VERSION "dbc-export 1 2025.20.8"

NS_ :

BS_:

BU_: ADSP APB APP APS APSB BB BMS CC CMP CMPD CP DAS DI DIF DIR DPB EPAS3P EPAS3S EPASTP EPASTS EPBL EPBR ESP EVSE FC GTW HCML HCMR HVP IBST ICR IDB LS OCS1P PARK PCS PM PMF PMR PNCD PTC RADC RCM RCM2 RCM3 RCU SCCM SCM SCS SDCR TAS TCU TPMS TRCM UI UIS UMC USM VC VCFRONT VCLEFT VCRIGHT VCSEC VEH

BO_ 1343 BMS_alertLog: 8 BMS
 SG_ BMS_alertID M : 0|8@1+ (1,0) [0|255] "" Vector__XXX
 SG_ BMS_alertSet : 15|1@1+ (1,0) [0|1] "" Vector__XXX
 SG_ BMS_a001_gatewayPackEnergy m1 : 16|2@1+ (1,0) [0|3] "" Vector__XXX
 SG_ BMS_a001_expectedPackEnergy m1 : 18|2@1+ (1,0) [0|3] "" Vector__XXX
 SG_ BMS_a002_gatewayPackPerformanceD m2 : 16|3@1+ (1,0) [0|7] "" Vector__XXX
 SG_ BMS_a002_expectedPackPerformance m2 : 19|3@1+ (1,0) [0|7] "" Vector__XXX
 SG_ BMS_a002_bmsPackMass m2 : 24|8@1+ (1,300) [300|555] "" Vector__XXX
 SG_ BMS_a003_calBlockData_0 m3 : 16|32@1+ (1,0) [0|4294967295] "" Vector__XXX
 SG_ BMS_a007_minPackTemperature m7 : 16|8@1+ (0.5,-40) [-40|87.5] "" Vector__XXX
 SG_ BMS_a007_packCurrent m7 : 24|14@1+ (0.1,0) [0|1638.3] "" Vector__XXX
 SG_ BMS_a007_idealCurrentTarget m7 : 40|14@1+ (0.1,0) [0|1638.3] "" Vector__XXX
 SG_ BMS_a017_packCurrent m17 : 16|8@1+ (8,-1500) [-1500|540] "" Vector__XXX
 SG_ BMS_a017_ovBrickVID m17 : 24|7@1+ (1,1) [1|128] "" Vector__XXX
 SG_ BMS_a017_ovBrickV m17 : 32|16@1+ (7.62939453125e-05,0) [0|4.99992370605] "" Vector__XXX
 SG_ BMS_a018_packCurrent m18 : 16|8@1+ (8,-1496) [-1496|544] "" Vector__XXX
 SG_ BMS_a018_uvBrickVID m18 : 24|7@1+ (1,1) [1|128] "" Vector__XXX
 SG_ BMS_a018_uvBrickV m18 : 32|16@1+ (7.62939453125e-05,0) [0|4.99992370605] "" Vector__XXX
 SG_ BMS_a019_coolantInletT m19 : 16|8@1+ (0.4,-20) [-20|82] "" Vector__XXX
 SG_ BMS_a019_activeCoolingTarget m19 : 24|8@1+ (0.4,-20) [-20|82] "" Vector__XXX
 SG_ BMS_a019_maxBrickT m19 : 32|8@1+ (0.4,-20) [-20|82] "" Vector__XXX
 SG_ BMS_a019_maxBrickTID m19 : 40|5@1+ (1,1) [1|32] "" Vector__XXX
 SG_ BMS_a021_chargeViolation m21 : 16|1@1+ (1,0) [0|1] "" Vector__XXX
 SG_ BMS_a021_currentLimit m21 : 24|8@1+ (8,-1496) [-1496|544] "" Vector__XXX
 SG_ BMS_a021_packCurrent m21 : 32|8@1+ (8,-1496) [-1496|544] "" Vector__XXX
 SG_ BMS_a022_chargeAccumulatorViolat m22 : 16|1@1+ (1,0) [0|1] "" Vector__XXX
 SG_ BMS_a022_chargeAccumulatorValue m22 : 17|23@1+ (10,0) [0|83886070] "" Vector__XXX
 SG_ BMS_a022_chargeAccumulatorLimit m22 : 40|23@1+ (10,0) [0|83886070] "" Vector__XXX
 SG_ BMS_a023_ovStackDeviceID m23 : 16|5@1+ (1,1) [1|32] "" Vector__XXX
 SG_ BMS_a023_ovStackV m23 : 24|16@1+ (0.00128,0) [0|83.8848] "" Vector__XXX
 SG_ BMS_a024_brickID m24 : 16|8@1+ (1,1) [1|256] "" Vector__XXX
 SG_ BMS_a024_deltaV m24 : 24|16@1- (0.0001,0) [-3.2768|3.2767] "" Vector__XXX
 SG_ BMS_a024_avgDvPrev m24 : 40|16@1- (0.0001,0) [-3.2768|3.2767] "" Vector__XXX
 SG_ BMS_a024_packCurrent m24 : 56|8@1+ (8,-1500) [-1500|540] "" Vector__XXX
 SG_ BMS_a027_swIsolationCount m27 : 16|8@1+ (1,0) [0|255] "" Vector__XXX
 SG_ BMS_a027_swIsoDegradationCount m27 : 24|8@1+ (1,0) [0|255] "" Vector__XXX
 SG_ BMS_a030_worstBrickID m30 : 16|8@1+ (1,1) [1|256] "" Vector__XXX
 SG_ BMS_a030_maxBrickImpedance m30 : 24|10@1+ (0.1,0) [0|102.3] "" Vector__XXX
 SG_ BMS_a030_maxNormalizedImpedanceD m30 : 34|7@1+ (0.04,0) [0|5.08] "" Vector__XXX
 SG_ BMS_a030_faultThreshold m30 : 41|7@1+ (0.04,0) [0|5.08] "" Vector__XXX
 SG_ BMS_a030_numBricks m30 : 48|8@1+ (1,0) [0|255] "" Vector__XXX
 SG_ BMS_a030_worstBrickSoc m30 : 56|8@1+ (0.5,0) [0|127.5] "" Vector__XXX
 SG_ BMS_a035_isoR m35 : 16|9@1+ (10,0) [0|5110] "" Vector__XXX
 SG_ BMS_a035_mode m35 : 25|3@1+ (1,0) [0|7] "" Vector__XXX
 SG_ BMS_a035_activeSideVNoR m35 : 28|9@1+ (1,0) [0|511] "" Vector__XXX
 SG_ BMS_a035_activeSideVWithR m35 : 37|9@1+ (1,0) [0|511] "" Vector__XXX
 SG_ BMS_a035_passiveSideVNoR m35 : 46|9@1+ (1,0) [0|511] "" Vector__XXX
 SG_ BMS_a035_passiveSideVWithR m35 : 55|9@1+ (1,0) [0|511] "" Vector__XXX
 SG_ BMS_a037_floodPort1State m37 : 16|3@1+ (1,0) [0|7] "" Vector__XXX
 SG_ BMS_a037_floodPort1Voltage m37 : 19|12@1+ (0.001,0) [0|4.095] "" Vector__XXX
 SG_ BMS_a037_floodPort2State m37 : 32|3@1+ (1,0) [0|7] "" Vector__XXX
 SG_ BMS_a037_floodPort2Voltage m37 : 35|12@1+ (0.001,0) [0|4.095] "" Vector__XXX
 SG_ BMS_a039_dcLinkVoltage m39 : 16|10@1+ (1,0) [0|1023] "" Vector__XXX
 SG_ BMS_a039_packVoltage m39 : 26|10@1+ (1,0) [0|1023] "" Vector__XXX
 SG_ BMS_a039_packContactorState m39 : 36|4@1+ (1,0) [0|15] "" Vector__XXX
 SG_ BMS_a039_packCurrent m39 : 40|8@1+ (8,-1496) [-1496|544] "" Vector__XXX
 SG_ BMS_a039_maxBrickV m39 : 48|8@1+ (0.01,2) [2|4.55] "" Vector__XXX
 SG_ BMS_a039_state m39 : 56|4@1+ (1,0) [0|15] "" Vector__XXX
 SG_ BMS_a041_resetType m41 : 16|4@1+ (1,0) [0|15] "" Vector__XXX
 SG_ BMS_a050_MIA_numBadReadings m50 : 16|8@1+ (1,0) [0|255] "" Vector__XXX
 SG_ BMS_a050_MIA_numSnaReadings m50 : 24|8@1+ (1,0) [0|255] "" Vector__XXX
 SG_ BMS_a051_hvp1V5Ref m51 : 16|12@1+ (0.001,0) [0|4.095] "" Vector__XXX
 SG_ BMS_a051_hvp3V0Ref m51 : 28|12@1+ (0.001,0) [0|4.095] "" Vector__XXX
 SG_ BMS_a051_bms3V0Ref m51 : 40|12@1+ (0.001,0) [0|4.095] "" Vector__XXX
 SG_ BMS_a056_standbySupplyOutV m56 : 16|12@1+ (0.01,0) [0|40.95] "" Vector__XXX
 SG_ BMS_a056_packVoltage m56 : 28|16@1+ (0.01,0) [0|655.35] "" Vector__XXX
 SG_ BMS_a056_minBrickVoltage m56 : 44|12@1+ (0.002,0) [0|8.19] "" Vector__XXX
 SG_ BMS_a056_standbyEnabled m56 : 56|1@1+ (1,0) [0|1] "" Vector__XXX
 SG_ BMS_a056_standbySwGood m56 : 57|1@1+ (1,0) [0|1] "" Vector__XXX
 SG_ BMS_a056_ssOutTooHigh m56 : 58|1@1+ (1,0) [0|1] "" Vector__XXX
 SG_ BMS_a056_ssOutTooLow m56 : 59|1@1+ (1,0) [0|1] "" Vector__XXX
 SG_ BMS_a056_ssStuckOn m56 : 60|1@1+ (1,0) [0|1] "" Vector__XXX
 SG_ BMS_a056_ssStuckOff m56 : 61|1@1+ (1,0) [0|1] "" Vector__XXX
 SG_ BMS_a058_bandoThmModelState m58 : 16|4@1+ (1,0) [0|15] "" Vector__XXX
 SG_ BMS_a058_thermistorTempsInvalid m58 : 20|1@1+ (1,0) [0|1] "" Vector__XXX
 SG_ BMS_a058_inletCoolantTempInvalid m58 : 21|1@1+ (1,0) [0|1] "" Vector__XXX
 SG_ BMS_a058_ambientTempInvalid m58 : 22|1@1+ (1,0) [0|1] "" Vector__XXX
 SG_ BMS_a058_flowRateInvalid m58 : 23|1@1+ (1,0) [0|1] "" Vector__XXX
 SG_ BMS_a058_brickDissipationInvalid m58 : 24|1@1+ (1,0) [0|1] "" Vector__XXX
 SG_ BMS_a058_sanityCheckFailed m58 : 25|1@1+ (1,0) [0|1] "" Vector__XXX
 SG_ BMS_a058_tempDelta1 m58 : 32|7@1- (0.2,0) [-12.8|12.6] "" Vector__XXX
 SG_ BMS_a058_tempDelta2 m58 : 40|7@1- (0.2,0) [-12.8|12.6] "" Vector__XXX
 SG_ BMS_a058_tempDelta3 m58 : 48|7@1- (0.2,0) [-12.8|12.6] "" Vector__XXX
 SG_ BMS_a058_tempDelta4 m58 : 56|7@1- (0.2,0) [-12.8|12.6] "" Vector__XXX
 SG_ BMS_a059_sumBrickVoltages m59 : 16|16@1+ (0.01,0) [0|655.35] "" Vector__XXX
 SG_ BMS_a059_packVoltage m59 : 32|16@1+ (0.01,0) [0|655.35] "" Vector__XXX
 SG_ BMS_a062_state m62 : 16|4@1+ (1,0) [0|15] "" Vector__XXX
 SG_ BMS_a062_minBrickVId m62 : 24|7@1+ (1,1) [1|128] "" Vector__XXX
 SG_ BMS_a062_minBrickVoltage m62 : 32|12@1+ (0.002,0) [0|8.19] "" Vector__XXX
 SG_ BMS_a062_maxBrickVId m62 : 44|7@1+ (1,1) [1|128] "" Vector__XXX
 SG_ BMS_a062_maxBrickVoltage m62 : 51|12@1+ (0.002,0) [0|8.19] "" Vector__XXX
 SG_ BMS_a063_cpFaultInV m63 : 16|12@1+ (0.001,0) [0|4.095] "" Vector__XXX
 SG_ BMS_a064_minBrickSOCID m64 : 16|7@1+ (1,1) [1|128] "" Vector__XXX
 SG_ BMS_a064_minBrickSOC m64 : 24|8@1+ (0.5,0) [0|127.5] "" Vector__XXX
 SG_ BMS_a064_maxBrickSOCID m64 : 32|7@1+ (1,1) [1|128] "" Vector__XXX
 SG_ BMS_a064_maxBrickSOC m64 : 40|8@1+ (0.5,0) [0|127.5] "" Vector__XXX
 SG_ BMS_a064_avgBrickSOC m64 : 48|8@1+ (0.5,0) [0|127.5] "" Vector__XXX
 SG_ BMS_a065_minBrickCacId m65 : 16|7@1+ (1,1) [1|128] "" Vector__XXX
 SG_ BMS_a065_minBrickCac m65 : 24|13@1+ (0.1,0) [0|819.1] "" Vector__XXX
 SG_ BMS_a065_avgBrickCac m65 : 40|13@1+ (0.1,0) [0|819.1] "" Vector__XXX
 SG_ BMS_a065_modCacImbalancePct m65 : 53|10@1+ (0.1,0) [0|102.3] "" Vector__XXX
 SG_ BMS_a066_minBrickSocId m66 : 16|7@1+ (1,1) [1|128] "" Vector__XXX
 SG_ BMS_a066_minBrickSocByOcvMax m66 : 24|8@1+ (0.5,0) [0|127.5] "" Vector__XXX
 SG_ BMS_a066_maxBrickSocId m66 : 32|7@1+ (1,1) [1|128] "" Vector__XXX
 SG_ BMS_a066_maxBrickSocByOcvMin m66 : 40|8@1+ (0.5,0) [0|127.5] "" Vector__XXX
 SG_ BMS_a066_maxBrickSoc m66 : 48|8@1+ (0.5,0) [0|127.5] "" Vector__XXX
 SG_ BMS_a066_avgBrickSoc m66 : 56|8@1+ (0.5,0) [0|127.5] "" Vector__XXX
 SG_ BMS_a067_minBrickCacId m67 : 16|7@1+ (1,1) [1|128] "" Vector__XXX
 SG_ BMS_a067_minBrickCac m67 : 24|13@1+ (0.1,0) [0|819.1] "" Vector__XXX
 SG_ BMS_a067_avgBrickCac m67 : 40|13@1+ (0.1,0) [0|819.1] "" Vector__XXX
 SG_ BMS_a067_modCacImbalancePct m67 : 53|10@1+ (0.1,0) [0|102.3] "" Vector__XXX
 SG_ BMS_a068_minBrickCacId m68 : 16|7@1+ (1,1) [1|128] "" Vector__XXX
 SG_ BMS_a068_minBrickCac m68 : 24|13@1+ (0.1,0) [0|819.1] "" Vector__XXX
 SG_ BMS_a068_avgBrickCac m68 : 40|13@1+ (0.1,0) [0|819.1] "" Vector__XXX
 SG_ BMS_a068_modCacImbalancePct m68 : 53|10@1+ (0.1,0) [0|102.3] "" Vector__XXX
 SG_ BMS_a069_dischargePowerPackVolta m69 : 16|8@1- (0.025,-3.15) [-6.35|0.025] "" Vector__XXX
 SG_ BMS_a069_dischargePowerBrickVolt m69 : 24|8@1- (0.005,-0.63) [-1.27|0.005] "" Vector__XXX
 SG_ BMS_a069_SOC m69 : 32|8@1+ (0.05,0) [0|12.75] "" Vector__XXX
 SG_ BMS_a069_minBrickT m69 : 40|8@1- (0.5,24) [-40|87.5] "" Vector__XXX
 SG_ BMS_a069_minBrickVLimit m69 : 48|8@1+ (0.01,2) [2|4.55] "" Vector__XXX
 SG_ BMS_a069_minBrickV m69 : 56|8@1+ (0.01,2) [2|4.55] "" Vector__XXX
 SG_ BMS_a070_state m70 : 16|4@1+ (1,0) [0|15] "" Vector__XXX
 SG_ BMS_a070_minBrickVId m70 : 24|7@1+ (1,1) [1|128] "" Vector__XXX
 SG_ BMS_a070_minBrickVoltage m70 : 32|12@1+ (0.002,0) [0|8.19] "" Vector__XXX
 SG_ BMS_a070_maxBrickVId m70 : 44|7@1+ (1,1) [1|128] "" Vector__XXX
 SG_ BMS_a070_maxBrickVoltage m70 : 51|12@1+ (0.002,0) [0|8.19] "" Vector__XXX
 SG_ BMS_a071_stateRequest m71 : 16|4@1+ (1,0) [0|15] "" Vector__XXX
 SG_ BMS_a071_state m71 : 20|4@1+ (1,0) [0|15] "" Vector__XXX
 SG_ BMS_a071_transitionAlertId m71 : 24|10@1+ (1,0) [0|1023] "" Vector__XXX
 SG_ BMS_a074_maxBrickVTarget m74 : 16|8@1+ (0.01,2) [2|4.55] "" Vector__XXX
 SG_ BMS_a074_maxBrickV m74 : 24|8@1+ (0.01,2) [2|4.55] "" Vector__XXX
 SG_ BMS_a075_chargeType m75 : 16|1@1+ (1,0) [0|1] "" Vector__XXX
 SG_ BMS_a076_netAh m76 : 16|21@1- (0.01,0) [-10485.76|10485.75] "" Vector__XXX
 SG_ BMS_a076_tetheringActive m76 : 37|1@1+ (1,0) [0|1] "" Vector__XXX
 SG_ BMS_a078_peakDchInChg m78 : 16|16@1- (0.1,0) [-3276.8|3276.7] "" Vector__XXX
 SG_ BMS_a079_maxBrickVTarget m79 : 16|8@1+ (0.01,2) [2|4.55] "" Vector__XXX
 SG_ BMS_a079_maxBrickV m79 : 24|8@1+ (0.01,2) [2|4.55] "" Vector__XXX
 SG_ BMS_a081_stateRequest m81 : 16|4@1+ (1,0) [0|15] "" Vector__XXX
 SG_ BMS_a081_firstBlockingAlertId m81 : 24|8@1+ (1,0) [0|255] "" Vector__XXX
 SG_ BMS_a081_secondBlockingAlertId m81 : 32|8@1+ (1,0) [0|255] "" Vector__XXX
 SG_ BMS_a081_thirdBlockingAlertId m81 : 40|8@1+ (1,0) [0|255] "" Vector__XXX
 SG_ BMS_a081_fourthBlockingAlertId m81 : 48|8@1+ (1,0) [0|255] "" Vector__XXX
 SG_ BMS_a081_totalAlertCount m81 : 56|8@1+ (1,0) [0|255] "" Vector__XXX
 SG_ BMS_a082_stateRequest m82 : 16|4@1+ (1,0) [0|15] "" Vector__XXX
 SG_ BMS_a082_firstAlertId m82 : 24|8@1+ (1,0) [0|255] "" Vector__XXX
 SG_ BMS_a082_secondAlertId m82 : 32|8@1+ (1,0) [0|255] "" Vector__XXX
 SG_ BMS_a082_thirdAlertId m82 : 40|8@1+ (1,0) [0|255] "" Vector__XXX
 SG_ BMS_a082_fourthAlertId m82 : 48|8@1+ (1,0) [0|255] "" Vector__XXX
 SG_ BMS_a082_totalAlertCount m82 : 56|8@1+ (1,0) [0|255] "" Vector__XXX
 SG_ BMS_a083_packContactorRequest m83 : 16|3@1+ (1,0) [0|7] "" Vector__XXX
 SG_ BMS_a085_packContactorSetStatePr m85 : 16|4@1+ (1,0) [0|15] "" Vector__XXX
 SG_ BMS_a085_packContactorSetState m85 : 20|4@1+ (1,0) [0|15] "" Vector__XXX
 SG_ BMS_a085_packContactorSetRe_0001 m85 : 24|3@1+ (1,0) [0|7] "" Vector__XXX
 SG_ BMS_a085_packContactorSetRequest m85 : 27|3@1+ (1,0) [0|7] "" Vector__XXX
 SG_ BMS_a086_fcContactorSetStatePrev m86 : 16|4@1+ (1,0) [0|15] "" Vector__XXX
 SG_ BMS_a086_fcContactorSetState m86 : 20|4@1+ (1,0) [0|15] "" Vector__XXX
 SG_ BMS_a086_fcContactorSetRequestPr m86 : 24|3@1+ (1,0) [0|7] "" Vector__XXX
 SG_ BMS_a086_fcContactorSetRequest m86 : 27|3@1+ (1,0) [0|7] "" Vector__XXX
 SG_ BMS_a087_blockingAlert m87 : 16|8@1+ (1,0) [0|255] "" Vector__XXX
 SG_ BMS_a090_GTWmessageTout m90 : 16|4@1+ (1,0) [0|15] "" Vector__XXX
 SG_ BMS_a097_missingFrame m97 : 16|1@1+ (1,0) [0|1] "" Vector__XXX
 SG_ BMS_a097_timeout m97 : 17|1@1+ (1,0) [0|1] "" Vector__XXX
 SG_ BMS_a098_breakLocationA m98 : 16|5@1+ (1,0) [0|31] "" Vector__XXX
 SG_ BMS_a098_bmbCommStatusTypeA m98 : 21|2@1+ (1,0) [0|3] "" Vector__XXX
 SG_ BMS_a098_breakLocationB m98 : 24|5@1+ (1,0) [0|31] "" Vector__XXX
 SG_ BMS_a098_bmbCommStatusTypeB m98 : 29|2@1+ (1,0) [0|3] "" Vector__XXX
 SG_ BMS_a098_alertFromHvp m98 : 31|1@1+ (1,0) [0|1] "" Vector__XXX
 SG_ BMS_a099_breakLocationA m99 : 16|5@1+ (1,0) [0|31] "" Vector__XXX
 SG_ BMS_a099_bmbCommStatusTypeA m99 : 21|2@1+ (1,0) [0|3] "" Vector__XXX
 SG_ BMS_a099_breakLocationB m99 : 24|5@1+ (1,0) [0|31] "" Vector__XXX
 SG_ BMS_a099_bmbCommStatusTypeB m99 : 29|2@1+ (1,0) [0|3] "" Vector__XXX
 SG_ BMS_a099_bmbChainBreakType m99 : 32|3@1+ (1,0) [0|7] "" Vector__XXX
 SG_ BMS_a099_alertFromHvp m99 : 35|1@1+ (1,0) [0|1] "" Vector__XXX
 SG_ BMS_a100_testTrigger m100 : 16|1@1+ (1,0) [0|1] "" Vector__XXX
 SG_ BMS_a100_setFromNvm m100 : 17|1@1+ (1,0) [0|1] "" Vector__XXX
 SG_ BMS_a100_voltageDeviation m100 : 18|1@1+ (1,0) [0|1] "" Vector__XXX
 SG_ BMS_a100_voltageLoss m100 : 19|1@1+ (1,0) [0|1] "" Vector__XXX
 SG_ BMS_a105_tSenseFailedModule1 m105 : 16|1@1+ (1,0) [0|1] "" Vector__XXX
 SG_ BMS_a105_avgBrickTModule1 m105 : 17|8@1+ (0.5,0) [0|127.5] "" Vector__XXX
 SG_ BMS_a105_tSenseFailedModule2 m105 : 25|1@1+ (1,0) [0|1] "" Vector__XXX
 SG_ BMS_a105_avgBrickTModule2 m105 : 26|8@1+ (0.5,0) [0|127.5] "" Vector__XXX
 SG_ BMS_a105_tSenseFailedModule3 m105 : 34|1@1+ (1,0) [0|1] "" Vector__XXX
 SG_ BMS_a105_avgBrickTModule3 m105 : 35|8@1+ (0.5,0) [0|127.5] "" Vector__XXX
 SG_ BMS_a105_tSenseFailedModule4 m105 : 43|1@1+ (1,0) [0|1] "" Vector__XXX
 SG_ BMS_a105_avgBrickTModule4 m105 : 44|8@1+ (0.5,0) [0|127.5] "" Vector__XXX
 SG_ BMS_a105_inletTemp m105 : 52|8@1+ (0.5,0) [0|127.5] "" Vector__XXX
 SG_ BMS_a106_minBrickT m106 : 16|8@1+ (0.5,0) [0|127.5] "" Vector__XXX
 SG_ BMS_a106_maxBrickT m106 : 24|8@1+ (0.5,0) [0|127.5] "" Vector__XXX
 SG_ BMS_a106_avgBrickT m106 : 32|8@1+ (0.5,0) [0|127.5] "" Vector__XXX
 SG_ BMS_a106_inletTemp m106 : 40|8@1+ (0.5,0) [0|127.5] "" Vector__XXX
 SG_ BMS_a107_MIA_numBadReadings m107 : 16|8@1+ (1,0) [0|255] "" Vector__XXX
 SG_ BMS_a107_MIA_numSnaReadings m107 : 24|8@1+ (1,0) [0|255] "" Vector__XXX
 SG_ BMS_a109_muteMask m109 : 16|16@1+ (1,0) [0|65535] "" Vector__XXX
 SG_ BMS_a109_packInBleed m109 : 32|1@1+ (1,0) [0|1] "" Vector__XXX
 SG_ BMS_a117_brickID m117 : 16|7@1+ (1,1) [1|128] "" Vector__XXX
 SG_ BMS_a117_brickSoc2 m117 : 23|10@1+ (0.1,0) [0|102.3] "" Vector__XXX
 SG_ BMS_a117_dSocAlertThreshold m117 : 33|5@1+ (0.125,-4) [-4|-0.125] "" Vector__XXX
 SG_ BMS_a117_dSocAlpha m117 : 48|12@1+ (0.0030517578125,-12.4969482422) [-12.4969482422|-1.25002230789e-11] "" Vector__XXX
 SG_ BMS_a122_thermistorID m122 : 16|5@1+ (1,1) [1|32] "" Vector__XXX
 SG_ BMS_a122_irrationalThermistorTem m122 : 24|8@1+ (0.5,-40) [-40|87.5] "" Vector__XXX
 SG_ BMS_a122_averageRawThermistorTem m122 : 32|8@1+ (0.5,-40) [-40|87.5] "" Vector__XXX
 SG_ BMS_a122_minRawThermistorTemp m122 : 40|8@1+ (0.5,-40) [-40|87.5] "" Vector__XXX
 SG_ BMS_a122_maxRawThermistorTemp m122 : 48|8@1+ (0.5,-40) [-40|87.5] "" Vector__XXX
 SG_ BMS_a122_numValidThermistors m122 : 56|5@1+ (1,0) [0|31] "" Vector__XXX
 SG_ BMS_a123_packPlus m123 : 32|8@1+ (4,0) [0|1020] "" Vector__XXX
 SG_ BMS_a123_isoR m123 : 40|10@1+ (10,0) [0|10230] "" Vector__XXX
 SG_ BMS_a123_packMinus m123 : 56|8@1- (4,0) [-512|508] "" Vector__XXX
 SG_ BMS_a129_brickID m129 : 16|8@1+ (1,1) [1|256] "" Vector__XXX
 SG_ BMS_a129_deltaV m129 : 24|16@1+ (0.0001,0) [0|6.5535] "" Vector__XXX
 SG_ BMS_a129_retryCount m129 : 40|4@1+ (1,0) [0|15] "" Vector__XXX
 SG_ BMS_a131_brickID m131 : 16|8@1+ (1,1) [1|256] "" Vector__XXX
 SG_ BMS_a131_deltaV m131 : 24|16@1+ (0.0001,0) [0|6.5535] "" Vector__XXX
 SG_ BMS_a131_retryCount m131 : 40|4@1+ (1,0) [0|15] "" Vector__XXX
 SG_ BMS_a132_multiVendorErrorMask m132 : 16|16@1+ (1,0) [0|65535] "" Vector__XXX
 SG_ BMS_a135_bmbDiagnosticsType m135 : 16|2@1+ (1,0) [0|3] "" Vector__XXX
 SG_ BMS_a135_bmbDeviceId m135 : 18|4@1+ (1,1) [1|16] "" Vector__XXX
 SG_ BMS_a135_readCVA m135 : 22|1@1+ (1,0) [0|1] "" Vector__XXX
 SG_ BMS_a135_readCVB m135 : 23|1@1+ (1,0) [0|1] "" Vector__XXX
 SG_ BMS_a135_readCVC m135 : 24|1@1+ (1,0) [0|1] "" Vector__XXX
 SG_ BMS_a135_readCVD m135 : 25|1@1+ (1,0) [0|1] "" Vector__XXX
 SG_ BMS_a135_readCVE m135 : 26|1@1+ (1,0) [0|1] "" Vector__XXX
 SG_ BMS_a135_readCVF m135 : 27|1@1+ (1,0) [0|1] "" Vector__XXX
 SG_ BMS_a135_readSNA m135 : 28|1@1+ (1,0) [0|1] "" Vector__XXX
 SG_ BMS_a135_readSNB m135 : 29|1@1+ (1,0) [0|1] "" Vector__XXX
 SG_ BMS_a135_readSNC m135 : 30|1@1+ (1,0) [0|1] "" Vector__XXX
 SG_ BMS_a135_readSND m135 : 31|1@1+ (1,0) [0|1] "" Vector__XXX
 SG_ BMS_a135_readSNE m135 : 32|1@1+ (1,0) [0|1] "" Vector__XXX
 SG_ BMS_a135_readSNF m135 : 33|1@1+ (1,0) [0|1] "" Vector__XXX
 SG_ BMS_a135_readAUXA m135 : 34|1@1+ (1,0) [0|1] "" Vector__XXX
 SG_ BMS_a135_readAUXB m135 : 35|1@1+ (1,0) [0|1] "" Vector__XXX
 SG_ BMS_a135_readSTAT m135 : 36|1@1+ (1,0) [0|1] "" Vector__XXX
 SG_ BMS_a136_maxBrickTID m136 : 16|5@1+ (1,1) [1|32] "" Vector__XXX
 SG_ BMS_a136_coolantInletT m136 : 24|8@1+ (0.4,-20) [-20|82] "" Vector__XXX
 SG_ BMS_a136_activeCoolingTarget m136 : 32|8@1+ (0.4,-20) [-20|82] "" Vector__XXX
 SG_ BMS_a136_maxBrickT m136 : 40|8@1+ (0.4,-20) [-20|82] "" Vector__XXX
 SG_ BMS_a139_packVoltage m139 : 16|16@1- (0.01,0) [-327.68|327.67] "" Vector__XXX
 SG_ BMS_a139_dcLinkVoltage m139 : 32|16@1+ (0.01,0) [0|655.35] "" Vector__XXX
 SG_ BMS_a140_bmbDeviceMask m140 : 16|16@1+ (1,0) [0|65535] "" Vector__XXX
 SG_ BMS_a140_faultType m140 : 32|8@1+ (1,0) [0|255] "" Vector__XXX
 SG_ BMS_a142_isolationResistance m142 : 16|10@1+ (10,0) [0|10230] "" Vector__XXX
 SG_ BMS_a142_mode m142 : 32|3@1+ (1,0) [0|7] "" Vector__XXX
 SG_ BMS_a143_initialSoc m143 : 16|9@1+ (0.2,0) [0|102.2] "" Vector__XXX
 SG_ BMS_a143_endingSoc m143 : 25|9@1+ (0.2,0) [0|102.2] "" Vector__XXX
 SG_ BMS_a143_deltaAh m143 : 34|9@1+ (0.5,0) [0|255.5] "" Vector__XXX
 SG_ BMS_a143_cacChangeBrickID m143 : 48|7@1+ (1,1) [1|128] "" Vector__XXX
 SG_ BMS_a143_cacUpdateError m143 : 56|8@1+ (0.1,0) [0|25.5] "" Vector__XXX
 SG_ BMS_a144_HVP_major_version m144 : 16|16@1+ (1,0) [0|65535] "" Vector__XXX
 SG_ BMS_a144_HVP_minor_version m144 : 32|16@1+ (1,0) [0|65535] "" Vector__XXX
 SG_ BMS_a144_BMS_minor_version m144 : 48|16@1+ (1,0) [0|65535] "" Vector__XXX
 SG_ BMS_a145_maxSocChange m145 : 16|11@1- (0.1,0) [-102.4|102.3] "" Vector__XXX
 SG_ BMS_a145_maxSocChangeBrickID m145 : 32|7@1+ (1,1) [1|128] "" Vector__XXX
 SG_ BMS_a145_numBricksChanged m145 : 40|7@1+ (1,0) [0|127] "" Vector__XXX
 SG_ BMS_a145_brickChangeHystRatio m145 : 48|10@1+ (0.001,0) [0|1.023] "" Vector__XXX
 SG_ BMS_a146_maxBrickV m146 : 16|8@1+ (0.01,2) [2|4.55] "" Vector__XXX
 SG_ BMS_a146_state m146 : 24|4@1+ (1,0) [0|15] "" Vector__XXX
 SG_ BMS_a146_packCurrent m146 : 32|8@1+ (8,-1496) [-1496|544] "" Vector__XXX
 SG_ BMS_a146_uvBrickVID m146 : 40|7@1+ (1,1) [1|128] "" Vector__XXX
 SG_ BMS_a146_uvBrickV m146 : 48|16@1+ (7.62939453125e-05,0) [0|4.99992370605] "" Vector__XXX
 SG_ BMS_a151_isoPositiveR m151 : 32|10@1+ (10,0) [0|10230] "" Vector__XXX
 SG_ BMS_a151_isoNegativeR m151 : 42|10@1+ (10,0) [0|10230] "" Vector__XXX
 SG_ BMS_a152_isoR m152 : 16|9@1+ (10,0) [0|5110] "" Vector__XXX
 SG_ BMS_a152_mode m152 : 25|3@1+ (1,0) [0|7] "" Vector__XXX
 SG_ BMS_a152_activeSideVNoR m152 : 28|9@1+ (1,0) [0|511] "" Vector__XXX
 SG_ BMS_a152_activeSideVWithR m152 : 37|9@1+ (1,0) [0|511] "" Vector__XXX
 SG_ BMS_a152_passiveSideVNoR m152 : 46|9@1+ (1,0) [0|511] "" Vector__XXX
 SG_ BMS_a152_passiveSideVWithR m152 : 55|9@1+ (1,0) [0|511] "" Vector__XXX
 SG_ BMS_a156_VrefSample m156 : 16|16@1+ (0.0001,0) [0|6.5535] "" Vector__XXX
 SG_ BMS_a156_bmbDeviceId m156 : 32|4@1+ (1,1) [1|16] "" Vector__XXX
 SG_ BMS_a156_VrefStatus m156 : 36|2@1+ (1,0) [0|3] "" Vector__XXX
 SG_ BMS_a158_shuntCurrentMia m158 : 16|1@1+ (1,0) [0|1] "" Vector__XXX
 SG_ BMS_a158_contactorStateMia m158 : 17|1@1+ (1,0) [0|1] "" Vector__XXX
 SG_ BMS_a158_hvpFaultsMia m158 : 18|1@1+ (1,0) [0|1] "" Vector__XXX
 SG_ BMS_a162_dischargePower_W m162 : 16|16@1- (1,0) [-32768|32767] "" Vector__XXX
 SG_ BMS_a162_minSoc m162 : 32|16@1+ (1,0) [0|65535] "" Vector__XXX
 SG_ BMS_a162_socThreshold m162 : 48|16@1+ (1,0) [0|65535] "" Vector__XXX
 SG_ BMS_a164_regenPower m164 : 16|32@1+ (1,0) [0|4294967295] "" Vector__XXX
 SG_ BMS_a165_packPositiveV m165 : 16|12@1- (0.25,0) [-512|511.75] "" Vector__XXX
 SG_ BMS_a165_packNegativeV m165 : 28|12@1- (0.25,0) [-512|511.75] "" Vector__XXX
 SG_ BMS_a165_dcLinkPositiveV m165 : 40|12@1- (0.25,0) [-512|511.75] "" Vector__XXX
 SG_ BMS_a165_dcLinkNegativeV m165 : 52|12@1- (0.25,0) [-512|511.75] "" Vector__XXX
 SG_ BMS_a166_packPositiveV m166 : 16|12@1- (0.25,0) [-512|511.75] "" Vector__XXX
 SG_ BMS_a166_packNegativeV m166 : 28|12@1- (0.25,0) [-512|511.75] "" Vector__XXX
 SG_ BMS_a166_dcLinkPositiveV m166 : 40|12@1- (0.25,0) [-512|511.75] "" Vector__XXX
 SG_ BMS_a166_dcLinkNegativeV m166 : 52|12@1- (0.25,0) [-512|511.75] "" Vector__XXX
 SG_ BMS_a167_fcContPositiveAuxOpen m167 : 16|1@1+ (1,0) [0|1] "" Vector__XXX
 SG_ BMS_a167_fcContNegativeAuxOpen m167 : 17|1@1+ (1,0) [0|1] "" Vector__XXX
 SG_ BMS_a167_dcLinkPositiveV m167 : 18|11@1- (0.5,0) [-512|511.5] "" Vector__XXX
 SG_ BMS_a167_dcLinkNegativeV m167 : 29|11@1- (0.5,0) [-512|511.5] "" Vector__XXX
 SG_ BMS_a167_fcLinkPositiveV m167 : 40|11@1- (0.5,0) [-512|511.5] "" Vector__XXX
 SG_ BMS_a167_fcLinkNegativeV m167 : 51|11@1- (0.5,0) [-512|511.5] "" Vector__XXX
 SG_ BMS_a168_fcContPositiveAuxOpen m168 : 16|1@1+ (1,0) [0|1] "" Vector__XXX
 SG_ BMS_a168_fcContNegativeAuxOpen m168 : 17|1@1+ (1,0) [0|1] "" Vector__XXX
 SG_ BMS_a168_dcLinkPositiveV m168 : 18|11@1- (0.5,0) [-512|511.5] "" Vector__XXX
 SG_ BMS_a168_dcLinkNegativeV m168 : 29|11@1- (0.5,0) [-512|511.5] "" Vector__XXX
 SG_ BMS_a168_fcLinkPositiveV m168 : 40|11@1- (0.5,0) [-512|511.5] "" Vector__XXX
 SG_ BMS_a168_fcLinkNegativeV m168 : 51|11@1- (0.5,0) [-512|511.5] "" Vector__XXX
 SG_ BMS_a169_DCAndFCContactorsWelded m169 : 16|1@1+ (1,0) [0|1] "" Vector__XXX
 SG_ BMS_a170_limpModeActive m170 : 16|1@1+ (1,0) [0|1] "" Vector__XXX
 SG_ BMS_a171_stackVoltage m171 : 16|16@1+ (0.00128,0) [0|83.8848] "" Vector__XXX
 SG_ BMS_a171_sumBrickVoltage m171 : 32|16@1+ (0.00128,0) [0|83.8848] "" Vector__XXX
 SG_ BMS_a171_stackId m171 : 48|8@1+ (1,1) [1|256] "" Vector__XXX
 SG_ BMS_a172_swIsolationCount m172 : 16|8@1+ (1,0) [0|255] "" Vector__XXX
 SG_ BMS_a172_swIsoDegradationCount m172 : 24|8@1+ (1,0) [0|255] "" Vector__XXX
 SG_ BMS_a177_energyAlertThreshold m177 : 16|10@1+ (0.1,0) [0|102.3] "" Vector__XXX
 SG_ BMS_a177_energyBuffer m177 : 26|10@1+ (0.1,0) [0|102.3] "" Vector__XXX
 SG_ BMS_a178_diPower m178 : 16|9@1- (4.3137254715,250.196075439) [-854.117645265|1350.19607067] "" Vector__XXX
 SG_ BMS_a178_energyError m178 : 25|8@1- (2,0) [-256|254] "" Vector__XXX
 SG_ BMS_a178_powerError m178 : 33|9@1- (1,0) [-256|255] "" Vector__XXX
 SG_ BMS_a178_minPowerError m178 : 42|9@1- (1,0) [-256|255] "" Vector__XXX
 SG_ BMS_a178_maxPowerError m178 : 51|9@1- (1,0) [-256|255] "" Vector__XXX
 SG_ BMS_a178_diMiaCount m178 : 60|2@1+ (1,0) [0|3] "" Vector__XXX
 SG_ BMS_a178_diSnaCount m178 : 62|2@1+ (1,0) [0|3] "" Vector__XXX

BO_ 800 BMS_alertMatrix: 8 BMS
 SG_ BMS_matrixIndex M : 0|4@1+ (1,0) [0|15] "" Vector__XXX
 SG_ BMS_a001_Pack_Config_Mismatch m0 : 4|1@1+ (1,0) [0|1] "" Vector__XXX
 SG_ BMS_a002_Pack_Performance_Config m0 : 5|1@1+ (1,0) [0|1] "" Vector__XXX
 SG_ BMS_a003_SW_Pack_Birth_Date_Miss m0 : 6|1@1+ (1,0) [0|1] "" Vector__XXX
 SG_ BMS_a004_Cal_Vs_Serial_Birth_Dat m0 : 7|1@1+ (1,0) [0|1] "" Vector__XXX
 SG_ BMS_a007_SW_Slowed_Chg_Batt_Cold m0 : 10|1@1+ (1,0) [0|1] "" Vector__XXX
 SG_ BMS_a016_Pack_Module_Id_Mismatch m0 : 19|1@1+ (1,0) [0|1] "" Vector__XXX
 SG_ BMS_a017_SW_Brick_OV m0 : 20|1@1+ (1,0) [0|1] "" Vector__XXX
 SG_ BMS_a018_SW_Brick_UV m0 : 21|1@1+ (1,0) [0|1] "" Vector__XXX
 SG_ BMS_a019_SW_Module_OT m0 : 22|1@1+ (1,0) [0|1] "" Vector__XXX
 SG_ BMS_a020_SW_Brick_Instability m0 : 23|1@1+ (1,0) [0|1] "" Vector__XXX
 SG_ BMS_a021_SW_Dr_Limits_Regulation m0 : 24|1@1+ (1,0) [0|1] "" Vector__XXX
 SG_ BMS_a022_SW_Over_Current m0 : 25|1@1+ (1,0) [0|1] "" Vector__XXX
 SG_ BMS_a023_SW_Stack_OV m0 : 26|1@1+ (1,0) [0|1] "" Vector__XXX
 SG_ BMS_a024_SW_Islanded_Brick m0 : 27|1@1+ (1,0) [0|1] "" Vector__XXX
 SG_ BMS_a025_SW_PwrBalance_Anomaly m0 : 28|1@1+ (1,0) [0|1] "" Vector__XXX
 SG_ BMS_a026_SW_HFCurrent_Anomaly m0 : 29|1@1+ (1,0) [0|1] "" Vector__XXX
 SG_ BMS_a027_SW_Repeated_Isolation_F m0 : 30|1@1+ (1,0) [0|1] "" Vector__XXX
 SG_ BMS_a028_ShuntAsicCurrentOffsetD m0 : 31|1@1+ (1,0) [0|1] "" Vector__XXX
 SG_ BMS_a029_dSoc_Limiting m0 : 32|1@1+ (1,0) [0|1] "" Vector__XXX
 SG_ BMS_a030_Impedance_Deviation m0 : 33|1@1+ (1,0) [0|1] "" Vector__XXX
 SG_ BMS_a031_AlertsSetDuringSleep m0 : 34|1@1+ (1,0) [0|1] "" Vector__XXX
 SG_ BMS_a032_VoltageLoss m0 : 35|1@1+ (1,0) [0|1] "" Vector__XXX
 SG_ BMS_a033_VoltageDeviation m0 : 36|1@1+ (1,0) [0|1] "" Vector__XXX
 SG_ BMS_a034_SW_Passive_Isolation m0 : 37|1@1+ (1,0) [0|1] "" Vector__XXX
 SG_ BMS_a035_SW_Isolation m0 : 38|1@1+ (1,0) [0|1] "" Vector__XXX
 SG_ BMS_a036_SW_HvpHvilFault m0 : 39|1@1+ (1,0) [0|1] "" Vector__XXX
 SG_ BMS_a037_SW_Flood_Port_Open m0 : 40|1@1+ (1,0) [0|1] "" Vector__XXX
 SG_ BMS_a039_SW_DC_Link_Over_Voltage m0 : 42|1@1+ (1,0) [0|1] "" Vector__XXX
 SG_ BMS_a040_SW_Watch_Dog_HW_Trigger m0 : 43|1@1+ (1,0) [0|1] "" Vector__XXX
 SG_ BMS_a041_SW_Destructive_Reset_So m0 : 44|1@1+ (1,0) [0|1] "" Vector__XXX
 SG_ BMS_a042_SW_MPU_Error m0 : 45|1@1+ (1,0) [0|1] "" Vector__XXX
 SG_ BMS_a043_SW_Watch_Dog_Reset m0 : 46|1@1+ (1,0) [0|1] "" Vector__XXX
 SG_ BMS_a044_SW_Assertion m0 : 47|1@1+ (1,0) [0|1] "" Vector__XXX
 SG_ BMS_a045_SW_Exception m0 : 48|1@1+ (1,0) [0|1] "" Vector__XXX
 SG_ BMS_a046_SW_Task_Stack_Usage m0 : 49|1@1+ (1,0) [0|1] "" Vector__XXX
 SG_ BMS_a047_SW_Task_Stack_Overflow m0 : 50|1@1+ (1,0) [0|1] "" Vector__XXX
 SG_ BMS_a048_SW_Watch_Dog_Warning m0 : 51|1@1+ (1,0) [0|1] "" Vector__XXX
 SG_ BMS_a049_SW_Thermal_Event m0 : 52|1@1+ (1,0) [0|1] "" Vector__XXX
 SG_ BMS_a050_SW_Brick_Voltage_MIA m0 : 53|1@1+ (1,0) [0|1] "" Vector__XXX
 SG_ BMS_a051_SW_HVC_Vref_Bad m0 : 54|1@1+ (1,0) [0|1] "" Vector__XXX
 SG_ BMS_a052_SW_PCS_MIA m0 : 55|1@1+ (1,0) [0|1] "" Vector__XXX
 SG_ BMS_a054_SW_Ver_Supply_Fault m0 : 57|1@1+ (1,0) [0|1] "" Vector__XXX
 SG_ BMS_a055_SW_HvChain_Model_Fault m0 : 58|1@1+ (1,0) [0|1] "" Vector__XXX
 SG_ BMS_a056_SW_Standby_Supply_Fault m0 : 59|1@1+ (1,0) [0|1] "" Vector__XXX
 SG_ BMS_a057_SW_Bandolier_Model_Warn m0 : 60|1@1+ (1,0) [0|1] "" Vector__XXX
 SG_ BMS_a058_SW_Bandolier_Model_Rese m0 : 61|1@1+ (1,0) [0|1] "" Vector__XXX
 SG_ BMS_a059_SW_Pack_Voltage_Sensing m0 : 62|1@1+ (1,0) [0|1] "" Vector__XXX
 SG_ BMS_a060_SW_Leakage_Test_Failure m0 : 63|1@1+ (1,0) [0|1] "" Vector__XXX
 SG_ BMS_a061_SW_BrickV_Change m1 : 4|1@1+ (1,0) [0|1] "" Vector__XXX
 SG_ BMS_a062_SW_BrickV_Imbalance m1 : 5|1@1+ (1,0) [0|1] "" Vector__XXX
 SG_ BMS_a063_SW_ChargePort_Fault m1 : 6|1@1+ (1,0) [0|1] "" Vector__XXX
 SG_ BMS_a064_SW_SOC_Imbalance m1 : 7|1@1+ (1,0) [0|1] "" Vector__XXX
 SG_ BMS_a065_SW_CAC_Imbalance m1 : 8|1@1+ (1,0) [0|1] "" Vector__XXX
 SG_ BMS_a066_SOC_Imbalance_Warning m1 : 9|1@1+ (1,0) [0|1] "" Vector__XXX
 SG_ BMS_a067_CAC_Imbalance_Limiting m1 : 10|1@1+ (1,0) [0|1] "" Vector__XXX
 SG_ BMS_a068_CAC_Imbalance_Limp m1 : 11|1@1+ (1,0) [0|1] "" Vector__XXX
 SG_ BMS_a069_SW_Low_Power m1 : 12|1@1+ (1,0) [0|1] "" Vector__XXX
 SG_ BMS_a070_BrickV_Imbalance_Limiti m1 : 13|1@1+ (1,0) [0|1] "" Vector__XXX
 SG_ BMS_a071_SW_SM_TransCon_Not_Met m1 : 14|1@1+ (1,0) [0|1] "" Vector__XXX
 SG_ BMS_a072_Module_Brick_Split m1 : 15|1@1+ (1,0) [0|1] "" Vector__XXX
 SG_ BMS_a073_Unexpected_Loss_Of_Lv m1 : 16|1@1+ (1,0) [0|1] "" Vector__XXX
 SG_ BMS_a074_Max_Charge_Level_Reduce m1 : 17|1@1+ (1,0) [0|1] "" Vector__XXX
 SG_ BMS_a075_SW_Chg_Disable_Failure m1 : 18|1@1+ (1,0) [0|1] "" Vector__XXX
 SG_ BMS_a076_SW_Dch_While_Charging m1 : 19|1@1+ (1,0) [0|1] "" Vector__XXX
 SG_ BMS_a077_SW_Charger_Regulation m1 : 20|1@1+ (1,0) [0|1] "" Vector__XXX
 SG_ BMS_a078_Rapid_Dch_While_Chargin m1 : 21|1@1+ (1,0) [0|1] "" Vector__XXX
 SG_ BMS_a079_Max_Charge_Level_Exceed m1 : 22|1@1+ (1,0) [0|1] "" Vector__XXX
 SG_ BMS_a080_SW_Pack_Ctr_Impedance m1 : 23|1@1+ (1,0) [0|1] "" Vector__XXX
 SG_ BMS_a081_SW_Ctr_Close_Blocked m1 : 24|1@1+ (1,0) [0|1] "" Vector__XXX
 SG_ BMS_a082_SW_Ctr_Force_Open m1 : 25|1@1+ (1,0) [0|1] "" Vector__XXX
 SG_ BMS_a083_SW_Ctr_Close_Failure m1 : 26|1@1+ (1,0) [0|1] "" Vector__XXX
 SG_ BMS_a084_SW_Sleep_Wake_Aborted m1 : 27|1@1+ (1,0) [0|1] "" Vector__XXX
 SG_ BMS_a085_SW_Pack_Contactor_Misma m1 : 28|1@1+ (1,0) [0|1] "" Vector__XXX
 SG_ BMS_a086_SW_FC_Contactor_Mismatc m1 : 29|1@1+ (1,0) [0|1] "" Vector__XXX
 SG_ BMS_a087_SW_Feim_Test_Blocked m1 : 30|1@1+ (1,0) [0|1] "" Vector__XXX
 SG_ BMS_a088_SW_VcFront_MIA_InDrive m1 : 31|1@1+ (1,0) [0|1] "" Vector__XXX
 SG_ BMS_a089_SW_VcFront_MIA m1 : 32|1@1+ (1,0) [0|1] "" Vector__XXX
 SG_ BMS_a090_SW_Gateway_MIA m1 : 33|1@1+ (1,0) [0|1] "" Vector__XXX
 SG_ BMS_a091_SW_ChargePort_MIA m1 : 34|1@1+ (1,0) [0|1] "" Vector__XXX
 SG_ BMS_a092_SW_ChargePort_Mia_On_Hv m1 : 35|1@1+ (1,0) [0|1] "" Vector__XXX
 SG_ BMS_a094_SW_Drive_Inverter_MIA m1 : 37|1@1+ (1,0) [0|1] "" Vector__XXX
 SG_ BMS_a095_SW_UI_MIA m1 : 38|1@1+ (1,0) [0|1] "" Vector__XXX
 SG_ BMS_a097_SW_BMB_Over_CAN_Communi m1 : 40|1@1+ (1,0) [0|1] "" Vector__XXX
 SG_ BMS_a098_SW_BMB_Data_Integrity_L m1 : 41|1@1+ (1,0) [0|1] "" Vector__XXX
 SG_ BMS_a099_SW_BMB_Communication m1 : 42|1@1+ (1,0) [0|1] "" Vector__XXX
 SG_ BMS_a100_ThermalEventSuspected m1 : 43|1@1+ (1,0) [0|1] "" Vector__XXX
 SG_ BMS_a105_SW_One_Module_Tsense m1 : 48|1@1+ (1,0) [0|1] "" Vector__XXX
 SG_ BMS_a106_SW_All_Module_Tsense m1 : 49|1@1+ (1,0) [0|1] "" Vector__XXX
 SG_ BMS_a107_SW_Stack_Voltage_MIA m1 : 50|1@1+ (1,0) [0|1] "" Vector__XXX
 SG_ BMS_a108_SW_BMB_Device_OT m1 : 51|1@1+ (1,0) [0|1] "" Vector__XXX
 SG_ BMS_a109_HW_BMB_Mute_Status_Mism m1 : 52|1@1+ (1,0) [0|1] "" Vector__XXX
 SG_ BMS_a110_LifeModel_AvgOffset_Cha m1 : 53|1@1+ (1,0) [0|1] "" Vector__XXX
 SG_ BMS_a111_LifeModel_Spread_Change m1 : 54|1@1+ (1,0) [0|1] "" Vector__XXX
 SG_ BMS_a112_LifeModel_Discontinuity m1 : 55|1@1+ (1,0) [0|1] "" Vector__XXX
 SG_ BMS_a115_Energy_Rubberbanding_Re m1 : 58|1@1+ (1,0) [0|1] "" Vector__XXX
 SG_ BMS_a117_SW_Delta_SOC_Weak_Short m1 : 60|1@1+ (1,0) [0|1] "" Vector__XXX
 SG_ BMS_a119_Fast_Open_Vsh_Detected m1 : 62|1@1+ (1,0) [0|1] "" Vector__XXX
 SG_ BMS_a121_SW_NVRAM_Config_Error m2 : 4|1@1+ (1,0) [0|1] "" Vector__XXX
 SG_ BMS_a122_SW_BMS_Therm_Irrational m2 : 5|1@1+ (1,0) [0|1] "" Vector__XXX
 SG_ BMS_a123_SW_Internal_Isolation m2 : 6|1@1+ (1,0) [0|1] "" Vector__XXX
 SG_ BMS_a124_Battery_Coolant_Flood m2 : 7|1@1+ (1,0) [0|1] "" Vector__XXX
 SG_ BMS_a126_SW_Thermistor_Failure m2 : 9|1@1+ (1,0) [0|1] "" Vector__XXX
 SG_ BMS_a127_SW_shunt_SNA m2 : 10|1@1+ (1,0) [0|1] "" Vector__XXX
 SG_ BMS_a128_SW_shunt_MIA m2 : 11|1@1+ (1,0) [0|1] "" Vector__XXX
 SG_ BMS_a129_SW_VSH_Failure m2 : 12|1@1+ (1,0) [0|1] "" Vector__XXX
 SG_ BMS_a130_IO_CAN_Error m2 : 13|1@1+ (1,0) [0|1] "" Vector__XXX
 SG_ BMS_a131_Bleed_FET_Failure m2 : 14|1@1+ (1,0) [0|1] "" Vector__XXX
 SG_ BMS_a132_HW_BMB_OTP_Uncorrctbl m2 : 15|1@1+ (1,0) [0|1] "" Vector__XXX
 SG_ BMS_a133_IO_CAN_Bus_Off m2 : 16|1@1+ (1,0) [0|1] "" Vector__XXX
 SG_ BMS_a134_SW_Delayed_Ctr_Off m2 : 17|1@1+ (1,0) [0|1] "" Vector__XXX
 SG_ BMS_a135_HW_BMB_Diagnostics_Fail m2 : 18|1@1+ (1,0) [0|1] "" Vector__XXX
 SG_ BMS_a136_SW_Module_OT_Warning m2 : 19|1@1+ (1,0) [0|1] "" Vector__XXX
 SG_ BMS_a137_SW_Brick_UV_Warning m2 : 20|1@1+ (1,0) [0|1] "" Vector__XXX
 SG_ BMS_a138_SW_Brick_OV_Warning m2 : 21|1@1+ (1,0) [0|1] "" Vector__XXX
 SG_ BMS_a139_SW_DC_Link_V_Irrational m2 : 22|1@1+ (1,0) [0|1] "" Vector__XXX
 SG_ BMS_a140_HW_BMB_Status_Fault m2 : 23|1@1+ (1,0) [0|1] "" Vector__XXX
 SG_ BMS_a141_SW_BMB_Status_Warning m2 : 24|1@1+ (1,0) [0|1] "" Vector__XXX
 SG_ BMS_a142_SW_Isolation_Degradatio m2 : 25|1@1+ (1,0) [0|1] "" Vector__XXX
 SG_ BMS_a143_SW_CAC_Change m2 : 26|1@1+ (1,0) [0|1] "" Vector__XXX
 SG_ BMS_a144_Hvp_Config_Mismatch m2 : 27|1@1+ (1,0) [0|1] "" Vector__XXX
 SG_ BMS_a145_SW_SOC_Change m2 : 28|1@1+ (1,0) [0|1] "" Vector__XXX
 SG_ BMS_a146_SW_Brick_Overdischarged m2 : 29|1@1+ (1,0) [0|1] "" Vector__XXX
 SG_ BMS_a147_SW_SOC_High_Ah_Error m2 : 30|1@1+ (1,0) [0|1] "" Vector__XXX
 SG_ BMS_a148_SW_Unsupported_BMB_ASIC m2 : 31|1@1+ (1,0) [0|1] "" Vector__XXX
 SG_ BMS_a149_SW_Missing_Config_Block m2 : 32|1@1+ (1,0) [0|1] "" Vector__XXX
 SG_ BMS_a150_SW_Missing_Part_Number m2 : 33|1@1+ (1,0) [0|1] "" Vector__XXX
 SG_ BMS_a151_SW_external_isolation m2 : 34|1@1+ (1,0) [0|1] "" Vector__XXX
 SG_ BMS_a152_Isolation_In_Dc_Charge m2 : 35|1@1+ (1,0) [0|1] "" Vector__XXX
 SG_ BMS_a154_SW_Brick_OV_Warning_Sto m2 : 37|1@1+ (1,0) [0|1] "" Vector__XXX
 SG_ BMS_a155_SW_Weak_short_impedence m2 : 38|1@1+ (1,0) [0|1] "" Vector__XXX
 SG_ BMS_a156_SW_BMB_Vref_bad m2 : 39|1@1+ (1,0) [0|1] "" Vector__XXX
 SG_ BMS_a157_SW_Hist_Update_Missed m2 : 40|1@1+ (1,0) [0|1] "" Vector__XXX
 SG_ BMS_a158_SW_HVP_HVI_Comms m2 : 41|1@1+ (1,0) [0|1] "" Vector__XXX
 SG_ BMS_a159_SW_HVP_ECU_Error m2 : 42|1@1+ (1,0) [0|1] "" Vector__XXX
 SG_ BMS_a160_SW_FC_Ctr_Clean_Failed m2 : 43|1@1+ (1,0) [0|1] "" Vector__XXX
 SG_ BMS_a161_SW_BMB_Vref_warning m2 : 44|1@1+ (1,0) [0|1] "" Vector__XXX
 SG_ BMS_a162_SW_No_Power_For_Support m2 : 45|1@1+ (1,0) [0|1] "" Vector__XXX
 SG_ BMS_a164_SW_Uncontrolled_Regen m2 : 47|1@1+ (1,0) [0|1] "" Vector__XXX
 SG_ BMS_a165_SW_Pack_Partial_Weld m2 : 48|1@1+ (1,0) [0|1] "" Vector__XXX
 SG_ BMS_a166_SW_Pack_Full_Weld m2 : 49|1@1+ (1,0) [0|1] "" Vector__XXX
 SG_ BMS_a167_SW_FC_Partial_Weld m2 : 50|1@1+ (1,0) [0|1] "" Vector__XXX
 SG_ BMS_a168_SW_FC_Full_Weld m2 : 51|1@1+ (1,0) [0|1] "" Vector__XXX
 SG_ BMS_a169_SW_FC_Pack_Weld m2 : 52|1@1+ (1,0) [0|1] "" Vector__XXX
 SG_ BMS_a170_SW_Limp_Mode m2 : 53|1@1+ (1,0) [0|1] "" Vector__XXX
 SG_ BMS_a171_SW_Stack_Voltage_Sense m2 : 54|1@1+ (1,0) [0|1] "" Vector__XXX
 SG_ BMS_a172_SW_Isolation_Failure_In m2 : 55|1@1+ (1,0) [0|1] "" Vector__XXX
 SG_ BMS_a174_SW_Charge_Failure m2 : 57|1@1+ (1,0) [0|1] "" Vector__XXX
 SG_ BMS_a175_Charge_Failure_External m2 : 58|1@1+ (1,0) [0|1] "" Vector__XXX
 SG_ BMS_a176_SW_GracefulPowerOff m2 : 59|1@1+ (1,0) [0|1] "" Vector__XXX
 SG_ BMS_a177_SW_Energy_Buffer_Size m2 : 60|1@1+ (1,0) [0|1] "" Vector__XXX
 SG_ BMS_a178_SW_Uncontrolled_Regen_P m2 : 61|1@1+ (1,0) [0|1] "" Vector__XXX
 SG_ BMS_a179_HvpGpoRequestActive m2 : 62|1@1+ (1,0) [0|1] "" Vector__XXX
 SG_ BMS_a180_SW_ECU_reset_blocked m2 : 63|1@1+ (1,0) [0|1] "" Vector__XXX
 SG_ BMS_a181_SW_Shunt_Over_Temperatu m3 : 4|1@1+ (1,0) [0|1] "" Vector__XXX
 SG_ BMS_a182_LifeModel_NoCurrentLoss m3 : 5|1@1+ (1,0) [0|1] "" Vector__XXX
 SG_ BMS_a183_LifeModel_StoDcrGrowth_ m3 : 6|1@1+ (1,0) [0|1] "" Vector__XXX
 SG_ BMS_a184_LifeModel_CyclingLoss_C m3 : 7|1@1+ (1,0) [0|1] "" Vector__XXX
 SG_ BMS_a185_LifeModel_CyclingDcrGro m3 : 8|1@1+ (1,0) [0|1] "" Vector__XXX
 SG_ BMS_a186_RippleHeatingChargeFaul m3 : 9|1@1+ (1,0) [0|1] "" Vector__XXX
 SG_ BMS_a187_RippleHeatingEmergencyS m3 : 10|1@1+ (1,0) [0|1] "" Vector__XXX
 SG_ BMS_a188_DtcConfirmed m3 : 11|1@1+ (1,0) [0|1] "" Vector__XXX

BO_ 818 BMS_bmbMinMax: 8 BMS
 SG_ BMS_bmbMinMaxMultiplexer M : 0|2@1+ (1,0) [0|3] "" Vector__XXX
 SG_ BMS_thermistorNumTMin m0 : 2|4@1+ (1,0) [0|15] "" Vector__XXX
 SG_ BMS_thermistorNumTMax m0 : 8|4@1+ (1,0) [0|15] "" Vector__XXX
 SG_ BMS_thermistorTMax m0 : 16|8@1+ (0.5,-40) [-40|87.5] "DegC" Vector__XXX
 SG_ BMS_thermistorTMin m0 : 24|8@1+ (0.5,-40) [-40|87.5] "DegC" Vector__XXX
 SG_ BMS_thermistorTAvg m0 : 32|8@1+ (0.5,-40) [-40|87.5] "DegC" Vector__XXX
 SG_ BMS_brickVoltageMax m1 : 2|12@1+ (0.002,0) [0|5] "V" Vector__XXX
 SG_ BMS_brickVoltageMin m1 : 16|12@1+ (0.002,0) [0|5] "V" Vector__XXX
 SG_ BMS_brickNumVoltageMax m1 : 32|7@1+ (1,1) [1|128] "" Vector__XXX
 SG_ BMS_brickNumVoltageMin m1 : 40|7@1+ (1,1) [1|128] "" Vector__XXX

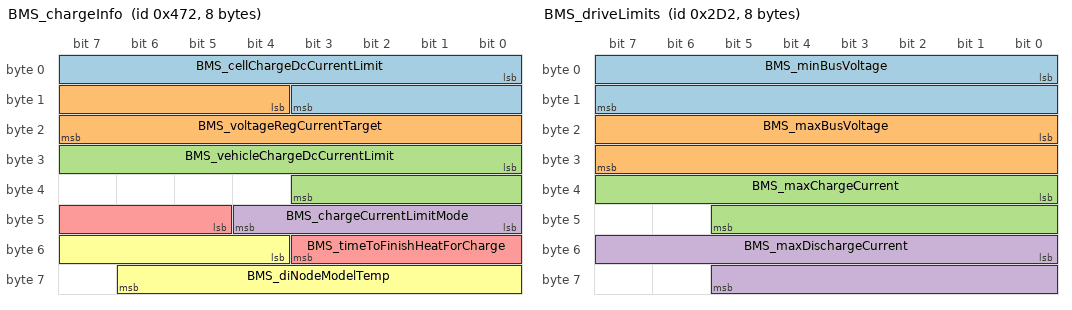
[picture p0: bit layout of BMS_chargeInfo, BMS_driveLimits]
BO_ 1138 BMS_chargeInfo: 8 BMS
 SG_ BMS_cellChargeDcCurrentLimit : 0|12@1+ (0.5,0) [0|2047.5] "A" Vector__XXX
 SG_ BMS_voltageRegCurrentTarget : 12|12@1+ (0.5,0) [0|2047.5] "A" Vector__XXX
 SG_ BMS_vehicleChargeDcCurrentLimit : 24|12@1+ (0.5,0) [0|2047.5] "A" Vector__XXX
 SG_ BMS_chargeCurrentLimitMode : 40|5@1+ (1,0) [0|31] "" Vector__XXX
 SG_ BMS_timeToFinishHeatForCharge : 45|7@1+ (5,0) [0|600] "min" Vector__XXX
 SG_ BMS_diNodeModelTemp : 52|11@1+ (0.1,-50) [-50|154.7] "degC" Vector__XXX

BO_ 2029 BMS_debugInfo_10Hz: 8 BMS
 SG_ BMS_10HzDebug_Id M : 0|6@1+ (1,0) [0|63] "" Vector__XXX
 SG_ BMS_activeCoolCellTargetT m33 : 6|9@1+ (0.25,-25) [-25|100] "DegC" Vector__XXX
 SG_ BMS_passiveCoolCellTargetT m33 : 15|9@1+ (0.25,-25) [-25|100] "DegC" Vector__XXX

BO_ 722 BMS_driveLimits: 8 BMS
 SG_ BMS_minBusVoltage : 0|16@1+ (0.02,0) [0|1200] "V" Vector__XXX
 SG_ BMS_maxBusVoltage : 16|16@1+ (0.02,0) [0|1200] "V" Vector__XXX
 SG_ BMS_maxChargeCurrent : 32|14@1+ (0.1,0) [0|1638.2] "A" Vector__XXX
 SG_ BMS_maxDischargeCurrent : 48|14@1+ (0.15,0) [0|2455] "A" Vector__XXX

BO_ 690 BMS_energyStatus: 8 BMS
 SG_ BMS_energyStatusMultiplexer M : 0|2@1+ (1,0) [0|3] "" Vector__XXX
 SG_ BMS_nominalFullPackEnergy m0 : 16|16@1+ (0.02,0) [0|1310.68] "kWh" Vector__XXX
 SG_ BMS_nominalEnergyRemaining m0 : 32|16@1+ (0.02,0) [0|1310.68] "kWh" Vector__XXX
 SG_ BMS_idealEnergyRemaining m0 : 48|16@1+ (0.02,0) [0|1310.68] "kWh" Vector__XXX
 SG_ BMS_fullChargeComplete m1 : 15|1@1+ (1,0) [0|1] "" Vector__XXX
 SG_ BMS_energyBuffer m1 : 16|16@1+ (0.01,0) [0|655.34] "kWh" Vector__XXX
 SG_ BMS_expectedEnergyRemaining m1 : 32|16@1+ (0.02,0) [0|1310.68] "kWh" Vector__XXX
 SG_ BMS_energyToChargeComplete m1 : 48|16@1+ (0.02,0) [0|1310.68] "kWh" Vector__XXX
 SG_ BMS_energyRemainingDisplay m2 : 8|16@1+ (0.02,0) [0|1310.68] "kWh" Vector__XXX
 SG_ BMS_energyRemainingTDisplay m2 : 24|16@1+ (0.02,0) [0|1310.68] "kWh" Vector__XXX
 SG_ BMS_energyDisplayErrorBlendRate m2 : 40|12@1+ (0.0156288165599,0) [0|64] "%" Vector__XXX
 SG_ BMS_userFacingSoe m2 : 52|11@1+ (0.05,0) [0|100] "%" Vector__XXX

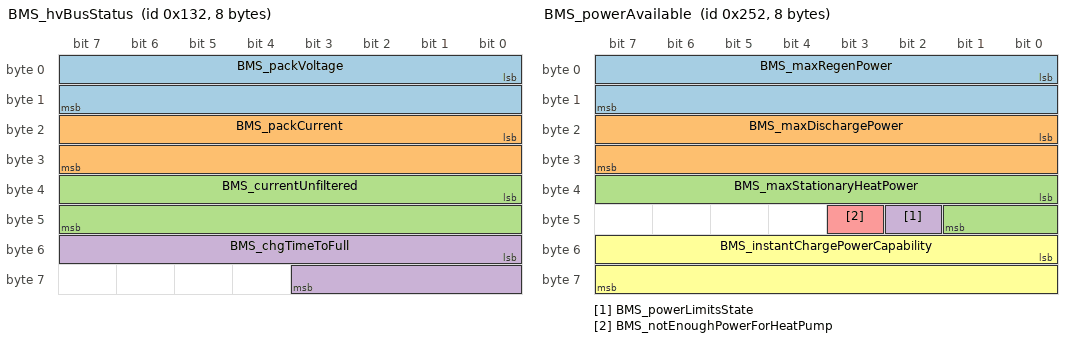
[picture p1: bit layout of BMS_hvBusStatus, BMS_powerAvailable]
BO_ 306 BMS_hvBusStatus: 8 BMS
 SG_ BMS_packVoltage : 0|16@1+ (0.01,0) [0|655.35] "V" Vector__XXX
 SG_ BMS_packCurrent : 16|16@1- (0.1,0) [-3276.7|3276.7] "A" Vector__XXX
 SG_ BMS_currentUnfiltered : 32|16@1- (0.05,-822) [-2460.3|816.3] "A" Vector__XXX
 SG_ BMS_chgTimeToFull : 48|12@1+ (0.01666667,0) [0|68.25001365] "Hours" Vector__XXX

BO_ 768 BMS_info: 8 BMS
 SG_ BMS_infoIndex M : 0|8@1+ (1,0) [0|255] "" Vector__XXX
 SG_ BMS_buildType m10 : 8|3@1+ (1,0) [0|7] "" Vector__XXX
 SG_ BMS_buildConfigId m10 : 16|16@1+ (1,0) [0|65535] "" Vector__XXX
 SG_ BMS_hardwareId m10 : 32|16@1+ (1,0) [0|65535] "" Vector__XXX
 SG_ BMS_componentId m10 : 48|16@1+ (1,0) [0|65535] "" Vector__XXX
 SG_ BMS_pcbaId m11 : 16|8@1+ (1,0) [0|255] "" Vector__XXX
 SG_ BMS_assemblyId m11 : 24|8@1+ (1,0) [0|255] "" Vector__XXX
 SG_ BMS_usageId m11 : 32|16@1+ (1,0) [0|65535] "" Vector__XXX
 SG_ BMS_subUsageId m11 : 48|16@1+ (1,0) [0|65535] "" Vector__XXX
 SG_ BMS_platformType m13 : 8|8@1+ (1,0) [0|255] "" Vector__XXX
 SG_ BMS_appCrc m13 : 32|32@1+ (1,0) [0|4294967295] "" Vector__XXX
 SG_ BMS_appGitHash m17 : 8|56@1+ (1,0) [0|7.20575940379e+16] "" Vector__XXX
 SG_ BMS_bootGitHash m18 : 8|56@1+ (1,0) [0|7.20575940379e+16] "" Vector__XXX
 SG_ BMS_bootUdsProtoVersion m20 : 8|8@1+ (1,0) [0|255] "" Vector__XXX
 SG_ BMS_bootCrc m20 : 32|32@1+ (1,0) [0|4294967295] "" Vector__XXX

BO_ 978 BMS_kwhCounter: 8 BMS
 SG_ BMS_kwhDischargeTotal : 0|32@1+ (0.001,0) [0|268435.456] "KWh" Vector__XXX
 SG_ BMS_kwhChargeTotal : 32|32@1+ (0.001,0) [0|268435.456] "KWh" Vector__XXX

BO_ 1010 BMS_kwhCountersMultiplexed: 8 BMS
 SG_ BMS_kwhCounter_Id M : 0|4@1+ (1,0) [0|15] "" Vector__XXX
 SG_ BMS_acChargerKwhTotal m0 : 8|32@1+ (0.001,0) [0|268435.456] "KWh" Vector__XXX
 SG_ BMS_dcChargerKwhTotal m1 : 8|32@1+ (0.001,0) [0|268435.456] "KWh" Vector__XXX
 SG_ BMS_kwhRegenChargeTotal m2 : 8|32@1+ (0.001,0) [0|268435.456] "KWh" Vector__XXX
 SG_ BMS_kwhDriveDischargeTotal m3 : 8|32@1+ (0.001,0) [0|268435.456] "KWh" Vector__XXX
 SG_ BMS_kwhDischargeTotalModule1 m4 : 8|28@1+ (0.001,0) [0|268435.455] "KWh" Vector__XXX
 SG_ BMS_kwhChargeTotalModule1 m4 : 36|28@1+ (0.001,0) [0|268435.455] "KWh" Vector__XXX
 SG_ BMS_kwhAcChargeTotalModule1 m5 : 8|28@1+ (0.001,0) [0|268435.455] "KWh" Vector__XXX
 SG_ BMS_kwhDcChargeTotalModule1 m5 : 36|28@1+ (0.001,0) [0|268435.455] "KWh" Vector__XXX
 SG_ BMS_kwhDischargeTotalModule2 m6 : 8|28@1+ (0.001,0) [0|268435.455] "KWh" Vector__XXX
 SG_ BMS_kwhChargeTotalModule2 m6 : 36|28@1+ (0.001,0) [0|268435.455] "KWh" Vector__XXX
 SG_ BMS_kwhAcChargeTotalModule2 m7 : 8|28@1+ (0.001,0) [0|268435.455] "KWh" Vector__XXX
 SG_ BMS_kwhDcChargeTotalModule2 m7 : 36|28@1+ (0.001,0) [0|268435.455] "KWh" Vector__XXX
 SG_ BMS_kwhDischargeTotalModule3 m8 : 8|28@1+ (0.001,0) [0|268435.455] "KWh" Vector__XXX
 SG_ BMS_kwhChargeTotalModule3 m8 : 36|28@1+ (0.001,0) [0|268435.455] "KWh" Vector__XXX
 SG_ BMS_kwhAcChargeTotalModule3 m9 : 8|28@1+ (0.001,0) [0|268435.455] "KWh" Vector__XXX
 SG_ BMS_kwhDcChargeTotalModule3 m9 : 36|28@1+ (0.001,0) [0|268435.455] "KWh" Vector__XXX
 SG_ BMS_kwhDischargeTotalModule4 m10 : 8|28@1+ (0.001,0) [0|268435.455] "KWh" Vector__XXX
 SG_ BMS_kwhChargeTotalModule4 m10 : 36|28@1+ (0.001,0) [0|268435.455] "KWh" Vector__XXX
 SG_ BMS_kwhAcChargeTotalModule4 m11 : 8|28@1+ (0.001,0) [0|268435.455] "KWh" Vector__XXX
 SG_ BMS_kwhDcChargeTotalModule4 m11 : 36|28@1+ (0.001,0) [0|268435.455] "KWh" Vector__XXX

BO_ 884 BMS_log1: 8 BMS
 SG_ BMS_log1MuxId M : 0|8@1+ (1,0) [0|255] "" Vector__XXX
 SG_ BMS_hvChargeStatus m8 : 16|4@1+ (1,0) [0|15] "" Vector__XXX
 SG_ BMS_extDcPrechargeVoltageLimit m8 : 20|12@1+ (0.146502256393,0) [0|599.926739929] "V" Vector__XXX
 SG_ BMS_dcChargeCurrentRequest m8 : 32|14@1- (0.25,0) [-2048|2047.75] "A" Vector__XXX
 SG_ BMS_dcChargeCurrentLimit m8 : 46|13@1- (0.5,0) [-2048|2047.5] "A" Vector__XXX
 SG_ BMS_dcDischargeEnabled m8 : 59|1@1+ (1,0) [0|1] "" Vector__XXX
 SG_ BMS_rippleChargeRetryCount m8 : 60|3@1+ (1,0) [0|7] "" Vector__XXX
 SG_ BMS_dcChargeVoltageLimit m9 : 8|12@1+ (0.146502256393,0) [0|599.926739929] "V" Vector__XXX
 SG_ BMS_dcChargePowerLimit m9 : 20|12@1- (1,0) [-2048|2047] "kW" Vector__XXX
 SG_ BMS_acChargePowerRequest m9 : 32|16@1+ (0.001,0) [0|65.535] "" Vector__XXX
 SG_ BMS_maxExtIsoFcLinkV m9 : 48|13@1+ (0.134293735027,0) [0|1099.99998361] "V" Vector__XXX
 SG_ BMS_socByDeltaVEnabled m15 : 8|1@1+ (1,0) [0|1] "" Vector__XXX
 SG_ BMS_socByDvMaxSocLimit m15 : 9|10@1+ (0.1,0) [0|102.2] "%" Vector__XXX
 SG_ BMS_socByDvVoltageChangeOverAh m15 : 19|9@1+ (0.002,0) [0|1] "V" Vector__XXX
 SG_ BMS_socByDvMaxSocByAhCorrected m15 : 28|10@1+ (0.1,0) [0|102.2] "%" Vector__XXX
 SG_ BMS_socByDvMaxBrickVoltage m15 : 40|12@1+ (0.002,0) [0|5] "V" Vector__XXX
 SG_ BMS_socByDvMaxBrickId m15 : 56|8@1+ (1,1) [1|256] "" Vector__XXX

BO_ 946 BMS_log2: 8 BMS
 SG_ BMS_log2MuxId M : 0|7@1+ (1,0) [0|127] "" Vector__XXX
 SG_ BMS_cacAvg m0 : 8|13@1+ (0.1,0) [0|819.1] "Ah" Vector__XXX
 SG_ BMS_cacMin m0 : 24|13@1+ (0.1,0) [0|819.1] "Ah" Vector__XXX
 SG_ BMS_cacMinBrickId m0 : 37|7@1+ (1,1) [1|128] "" Vector__XXX
 SG_ BMS_cacMax m0 : 44|13@1+ (0.1,0) [0|819.1] "Ah" Vector__XXX
 SG_ BMS_cacMaxBrickId m0 : 57|7@1+ (1,1) [1|128] "" Vector__XXX
 SG_ BMS_acRippleConfigNvramValid m18 : 7|1@1+ (1,0) [0|1] "" Vector__XXX
 SG_ BMS_hvChain_useLeakyBucket m18 : 8|1@1+ (1,0) [0|1] "" Vector__XXX
 SG_ BMS_hvChain_iLimit m18 : 9|14@1+ (0.2,0) [0|3275] "A" Vector__XXX
 SG_ BMS_hvChain_limitingState m18 : 23|9@1+ (1,1) [1|512] "" Vector__XXX
 SG_ BMS_hvChain_limitingStateTempera m18 : 32|13@1- (0.1,367.6) [-40|775] "DegC" Vector__XXX
 SG_ BMS_acRippleIsSupported m18 : 45|1@1+ (1,0) [0|1] "" Vector__XXX
 SG_ BMS_acRippleStartTemperatureMax m18 : 46|9@1+ (0.25,-25) [-25|100] "DegC" Vector__XXX
 SG_ BMS_acRippleStartTemperatureMin m18 : 55|9@1+ (0.25,-25) [-25|100] "DegC" Vector__XXX
 SG_ BMS_fcLinkTestDecayTime m20 : 8|10@1+ (2,0) [0|2044] "mS" Vector__XXX
 SG_ BMS_fcLinkTestTimeSinceLastRun m20 : 18|12@1+ (0.0175824183971,0) [0|71.99] "Hours" Vector__XXX
 SG_ BMS_pcsPrechargeRequestActive m20 : 30|1@1+ (1,0) [0|1] "" Vector__XXX
 SG_ BMS_pcsPrechargeTargetVoltage m20 : 32|16@1- (0.1,0) [-3276.8|3276.7] "V" Vector__XXX
 SG_ BMS_recentOvUvAlert m20 : 48|1@1+ (1,0) [0|1] "" Vector__XXX
 SG_ BMS_recentIsoAlert m20 : 49|1@1+ (1,0) [0|1] "" Vector__XXX
 SG_ BMS_recentBmbMiaAlert m20 : 50|1@1+ (1,0) [0|1] "" Vector__XXX
 SG_ BMS_cacBlendingConfigNvramValid m20 : 51|1@1+ (1,0) [0|1] "" Vector__XXX
 SG_ BMS_cacBlendingEnabled m20 : 52|1@1+ (1,0) [0|1] "" Vector__XXX
 SG_ BMS_cacBlendPercentPerCycle m20 : 53|10@1+ (0.001,0) [0|1.023] "%" Vector__XXX
 SG_ BMS_energyVariableChgRequested m21 : 8|1@1+ (1,0) [0|1] "" Vector__XXX
 SG_ BMS_packRestTime m21 : 9|12@1+ (0.0175824183971,0) [0|71.99] "Hours" Vector__XXX
 SG_ BMS_idealEnergyFloor m21 : 21|10@1+ (0.1,0) [0|102.2] "KWh" Vector__XXX
 SG_ BMS_thmGradientSlopeCondition m21 : 31|1@1+ (1,0) [0|1] "" Vector__XXX
 SG_ BMS_recentSlopeConditon m21 : 32|1@1+ (1,0) [0|1] "" Vector__XXX
 SG_ BMS_dynamicEnergyBuffer m21 : 33|10@1+ (0.1,0) [0|102.2] "KWh" Vector__XXX
 SG_ BMS_temperatureCondition m21 : 43|1@1+ (1,0) [0|1] "" Vector__XXX
 SG_ BMS_thmGradientSlope m21 : 44|10@1- (0.01,0) [-5.12|5.11] "C/min" Vector__XXX
 SG_ BMS_thmGradient m21 : 56|8@1+ (0.1,0) [0|25.5] "C" Vector__XXX
 SG_ BMS_dSocNormalizedMin m33 : 8|12@1+ (0.0030517578125,-12.4969482422) [-12.4969482422|-0.0030517578125] "%" Vector__XXX
 SG_ BMS_dSocNormalizedFiltMin m33 : 20|12@1+ (0.0030517578125,-12.4969482422) [-12.4969482422|-0.0030517578125] "%" Vector__XXX
 SG_ BMS_dSocMinAlpha m33 : 32|12@1+ (0.0030517578125,-12.4969482422) [-12.4969482422|-0.0030517578125] "%" Vector__XXX
 SG_ BMS_dSocMaxLowAlphaCounter m33 : 44|4@1+ (1,0) [0|15] "" Vector__XXX
 SG_ BMS_dSocMinAlphaBrickID m33 : 48|7@1+ (1,1) [1|128] "" Vector__XXX
 SG_ BMS_dSocCacMargin m33 : 55|9@1+ (0.0030517578125,0) [0|1.55639648438] "%" Vector__XXX
 SG_ BMS_lifeModelAvgTempSeverity m55 : 8|5@1+ (0.1,0) [0|3] "-" Vector__XXX
 SG_ BMS_lifeModelDepthOfDischargeSev m55 : 16|8@1+ (0.01,0) [0|1.5] "-" Vector__XXX
 SG_ BMS_lifeModelHistogramCapacityLo m55 : 24|9@1+ (0.1,0) [0|51] "%" Vector__XXX
 SG_ BMS_lifeModelHistogramBrickCapac m55 : 33|13@1+ (0.1,0) [0|819] "Ah" Vector__XXX
 SG_ BMS_lifeModelDcrGrowthPercent m55 : 48|14@1- (0.1,200) [-100|500] "%" Vector__XXX
 SG_ BMS_nominalFullPackEnergyRaw m56 : 8|16@1+ (0.02,0) [0|1310.68] "kWh" Vector__XXX
 SG_ BMS_userChargeCalibratingReason m56 : 24|2@1+ (1,0) [0|3] "" Vector__XXX
 SG_ BMS_nominalEnergyRemainingBuffer m56 : 32|16@1+ (0.02,0) [0|1310.68] "kWh" Vector__XXX
 SG_ BMS_idealEnergyRemainingBuffered m56 : 48|16@1+ (0.02,0) [0|1310.68] "kWh" Vector__XXX
 SG_ BMS_largestCacSpreadErrorLower m64 : 8|12@1+ (0.1,0) [0|409.4] "Ah" Vector__XXX
 SG_ BMS_lifeModelAverageCac m64 : 20|12@1+ (0.1,0) [0|409.4] "Ah" Vector__XXX
 SG_ BMS_lifeModelCacBrick1 m64 : 32|12@1+ (0.1,0) [0|409.4] "Ah" Vector__XXX
 SG_ BMS_lifeModelAverageOffset m64 : 44|10@1- (0.1,0) [-51.1|51.1] "Ah" Vector__XXX
 SG_ BMS_percentCacUpdatesInTimeWindo m64 : 54|10@1+ (0.1,0) [0|100] "%" Vector__XXX
 SG_ BMS_lifeModelMaxCacBrickId m65 : 8|8@1+ (1,1) [1|255] "" Vector__XXX
 SG_ BMS_lifeModelMaxCac m65 : 16|12@1+ (0.1,0) [0|409.4] "Ah" Vector__XXX
 SG_ BMS_lifeModelMinCacBrickId m65 : 28|8@1+ (1,1) [1|255] "" Vector__XXX
 SG_ BMS_lifeModelMinCac m65 : 36|12@1+ (0.1,0) [0|409.4] "Ah" Vector__XXX
 SG_ BMS_restingPointCacAvg m65 : 48|12@1+ (0.1,0) [0|409.4] "Ah" Vector__XXX
 SG_ BMS_cacEstimationSource m65 : 60|2@1+ (1,0) [0|3] "" Vector__XXX
 SG_ BMS_synchronizedCacMaxRaw m71 : 8|12@1+ (0.1,0) [0|409.4] "Ah" Vector__XXX
 SG_ BMS_synchronizedCacMinRaw m71 : 20|12@1+ (0.1,0) [0|409.4] "Ah" Vector__XXX
 SG_ BMS_largestSyncCacErrorStartSoc m71 : 32|10@1+ (0.1,0) [0|102.2] "%" Vector__XXX
 SG_ BMS_largestSyncCacErrorEndSoc m71 : 42|10@1+ (0.1,0) [0|102.2] "%" Vector__XXX
 SG_ BMS_runtimeSocConfigNvramValid m71 : 52|1@1+ (1,0) [0|1] "" Vector__XXX
 SG_ BMS_runtimeSocCorrectionsEnabled m71 : 53|1@1+ (1,0) [0|1] "" Vector__XXX
 SG_ BMS_rubberBandingEnabled m71 : 54|1@1+ (1,0) [0|1] "" Vector__XXX
 SG_ BMS_rubberBandingConfigNvramVali m71 : 55|1@1+ (1,0) [0|1] "" Vector__XXX
 SG_ BMS_runtimeSocMinTempForModel m71 : 56|6@1+ (0.5,0) [0|20] "DegC" Vector__XXX
 SG_ BMS_energyBufferConfigNvramValid m71 : 62|1@1+ (1,0) [0|1] "" Vector__XXX
 SG_ BMS_thermalEvent1pDetectConfigDi m71 : 63|1@1+ (1,0) [0|1] "" Vector__XXX
 SG_ BMS_sohEnergy m79 : 8|11@1+ (0.1,0) [0|204.7] "KWh" Vector__XXX
 SG_ BMS_fullCapacitySohEnergy m79 : 19|11@1+ (0.1,0) [0|204.7] "KWh" Vector__XXX
 SG_ BMS_calibratedCapacitySohEnergy m79 : 30|11@1+ (0.1,0) [0|204.7] "KWh" Vector__XXX
 SG_ BMS_estimatedCapacitySohEnergy m79 : 41|11@1+ (0.1,0) [0|204.7] "KWh" Vector__XXX
 SG_ BMS_prevUserFacingSohEnergy m79 : 52|11@1+ (0.1,0) [0|204.7] "KWh" Vector__XXX
 SG_ BMS_stateOfHealthMinCac m80 : 8|13@1+ (0.1,0) [0|819] "Ah" Vector__XXX
 SG_ BMS_lifeModelStorageLossPackAge m80 : 24|14@1+ (1,0) [0|16382] "days" Vector__XXX
 SG_ BMS_lifeModelThroughputCycleCoun m80 : 40|12@1+ (1,0) [0|4094] "Cycles" Vector__XXX
 SG_ BMS_lifeModelThroughputDcrCycleC m80 : 52|12@1+ (1,0) [0|4094] "Cycles" Vector__XXX
 SG_ BMS_energyWalkCounter m83 : 8|8@1+ (1,0) [0|255] "" Vector__XXX
 SG_ BMS_energyWalkTimeoutCounter m83 : 16|8@1+ (1,0) [0|255] "" Vector__XXX
 SG_ BMS_dynamicCcvEnabled m83 : 24|1@1+ (1,0) [0|1] "" Vector__XXX
 SG_ BMS_chargeTargetLookupSoc m83 : 32|10@1+ (0.1,0) [0|102.2] "%" Vector__XXX
 SG_ BMS_stateOfHealth m83 : 42|10@1+ (0.1,0) [0|100] "%" Vector__XXX

BO_ 914 BMS_packConfig: 8 BMS
 SG_ BMS_packConfigMultiplexer M : 0|8@1+ (1,0) [0|255] "" Vector__XXX
 SG_ BMS_reservedConfig_0 m0 : 8|5@1+ (1,0) [0|31] "" Vector__XXX
 SG_ BMS_moduleType m1 : 8|3@1+ (1,0) [0|7] "" Vector__XXX
 SG_ BMS_thermalPackType m1 : 11|4@1+ (1,0) [0|15] "" Vector__XXX
 SG_ BMS_packMass m1 : 16|8@1+ (1,300) [342|540] "kg" Vector__XXX
 SG_ BMS_platformMaxBusVoltage m1 : 24|10@1+ (1,300) [300|1300] "V" Vector__XXX
 SG_ BMS_standbySupplyContinuousPower m1 : 36|2@1+ (1,0) [0|3] "" Vector__XXX

BO_ 594 BMS_powerAvailable: 8 BMS
 SG_ BMS_maxRegenPower : 0|16@1+ (0.01,0) [0|655.35] "kW" Vector__XXX
 SG_ BMS_maxDischargePower : 16|16@1+ (0.013,0) [0|850] "kW" Vector__XXX
 SG_ BMS_maxStationaryHeatPower : 32|10@1+ (0.01,0) [0|10.23] "kW" Vector__XXX
 SG_ BMS_powerLimitsState : 42|1@1+ (1,0) [0|1] "" Vector__XXX
 SG_ BMS_notEnoughPowerForHeatPump : 43|1@1+ (1,0) [0|1] "" Vector__XXX
 SG_ BMS_instantChargePowerCapability : 48|16@1+ (0.05,0) [0|3276.75] "kW" Vector__XXX

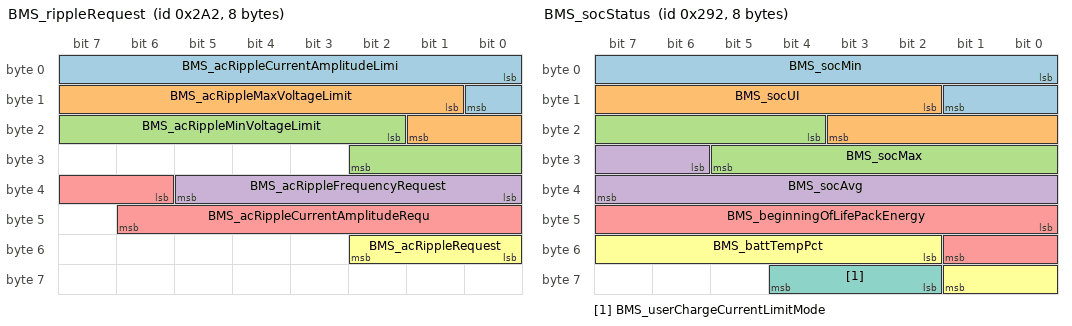
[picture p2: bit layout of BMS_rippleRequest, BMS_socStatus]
BO_ 674 BMS_rippleRequest: 8 BMS
 SG_ BMS_acRippleCurrentAmplitudeLimi : 0|9@1+ (1,0) [0|511] "A" Vector__XXX
 SG_ BMS_acRippleMaxVoltageLimit : 9|9@1+ (1,0) [0|511] "V" Vector__XXX
 SG_ BMS_acRippleMinVoltageLimit : 18|9@1+ (1,0) [0|511] "V" Vector__XXX
 SG_ BMS_acRippleFrequencyRequest : 32|6@1+ (1,80) [80|143] "Hz" Vector__XXX
 SG_ BMS_acRippleCurrentAmplitudeRequ : 38|9@1+ (1,0) [0|511] "A" Vector__XXX
 SG_ BMS_acRippleRequest : 48|3@1+ (1,0) [0|7] "" Vector__XXX

BO_ 658 BMS_socStatus: 8 BMS
 SG_ BMS_socMin : 0|10@1+ (0.1,0) [0|102.2] "%" Vector__XXX
 SG_ BMS_socUI : 10|10@1+ (0.1,0) [0|100] "%" Vector__XXX
 SG_ BMS_socMax : 20|10@1+ (0.1,0) [0|102.2] "%" Vector__XXX
 SG_ BMS_socAvg : 30|10@1+ (0.1,0) [0|102.2] "%" Vector__XXX
 SG_ BMS_beginningOfLifePackEnergy : 40|10@1+ (0.1,0) [0|102.2] "KWh" Vector__XXX
 SG_ BMS_battTempPct : 50|8@1+ (0.4,0) [0|100] "%" Vector__XXX
 SG_ BMS_userChargeCurrentLimitMode : 58|3@1+ (1,0) [0|7] "" Vector__XXX

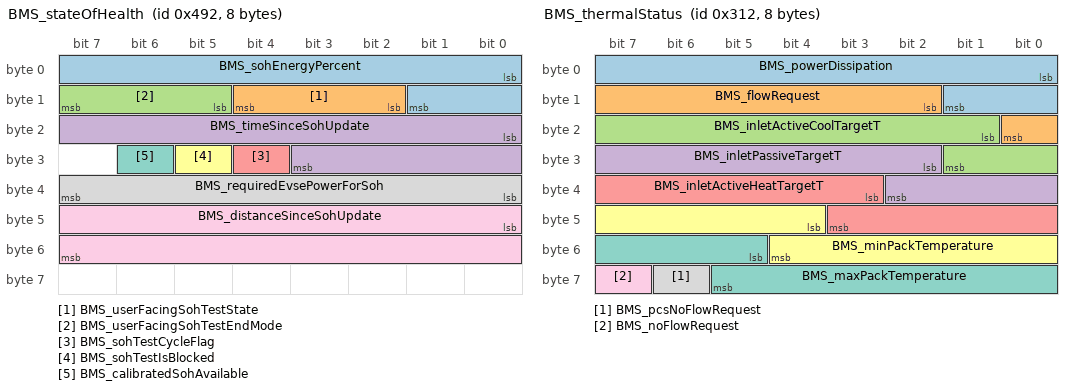
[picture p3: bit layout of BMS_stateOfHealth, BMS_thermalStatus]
BO_ 1170 BMS_stateOfHealth: 8 BMS
 SG_ BMS_sohEnergyPercent : 0|10@1+ (0.1,0) [0|100] "%" Vector__XXX
 SG_ BMS_userFacingSohTestState : 10|3@1+ (1,0) [0|7] "" Vector__XXX
 SG_ BMS_userFacingSohTestEndMode : 13|3@1+ (1,0) [0|7] "" Vector__XXX
 SG_ BMS_timeSinceSohUpdate : 16|12@1+ (1,0) [0|3650] "days" Vector__XXX
 SG_ BMS_sohTestCycleFlag : 28|1@1+ (1,0) [0|1] "" Vector__XXX
 SG_ BMS_sohTestIsBlocked : 29|1@1+ (1,0) [0|1] "" Vector__XXX
 SG_ BMS_calibratedSohAvailable : 30|1@1+ (1,0) [0|1] "" Vector__XXX
 SG_ BMS_requiredEvsePowerForSoh : 32|8@1+ (0.125,0) [0|31.75] "kW" Vector__XXX
 SG_ BMS_distanceSinceSohUpdate : 40|16@1+ (1,0) [0|65534] "km" Vector__XXX

BO_ 530 BMS_status: 8 BMS
 SG_ BMS_hvacPowerRequest : 0|1@1+ (1,0) [0|1] "" Vector__XXX
 SG_ BMS_notEnoughPowerForDrive : 1|1@1+ (1,0) [0|1] "" Vector__XXX
 SG_ BMS_notEnoughPowerForSupport : 2|1@1+ (1,0) [0|1] "" Vector__XXX
 SG_ BMS_preconditionAllowed : 3|1@1+ (1,0) [0|1] "" Vector__XXX
 SG_ BMS_updateAllowed : 4|1@1+ (1,0) [0|1] "" Vector__XXX
 SG_ BMS_activeHeatingWorthwhile : 5|1@1+ (1,0) [0|1] "" Vector__XXX
 SG_ BMS_cpMiaOnHvs : 6|1@1+ (1,0) [0|1] "" Vector__XXX
 SG_ BMS_pcsPwmEnabled : 7|1@1+ (1,0) [0|1] "" Vector__XXX
 SG_ BMS_contactorState : 8|3@1+ (1,0) [0|7] "" Vector__XXX
 SG_ BMS_userChargeStatus : 11|3@1+ (1,0) [0|7] "" Vector__XXX
 SG_ BMS_totalBatteryPower : 14|17@1- (0.05,0) [-3276.8|3276.75] "" Vector__XXX
 SG_ BMS_chargeRequest : 31|1@1+ (1,0) [0|1] "" Vector__XXX
 SG_ BMS_state : 32|4@1+ (1,0) [0|15] "" Vector__XXX
 SG_ BMS_diLimpRequest : 37|1@1+ (1,0) [0|1] "" Vector__XXX
 SG_ BMS_okToShipByAir : 38|1@1+ (1,0) [0|1] "" Vector__XXX
 SG_ BMS_okToShipByLand : 39|1@1+ (1,0) [0|1] "" Vector__XXX
 SG_ BMS_chgPowerAvailable : 40|12@1+ (0.125,0) [0|511.75] "kW" Vector__XXX
 SG_ BMS_chargeRetryCount : 53|3@1+ (1,0) [0|7] "" Vector__XXX
 SG_ BMS_conditioningRequest : 56|1@1+ (1,0) [0|1] "" Vector__XXX
 SG_ BMS_smStateRequest : 57|4@1+ (1,0) [0|15] "" Vector__XXX
 SG_ BMS_hvState : 61|3@1+ (1,0) [0|7] "" Vector__XXX

BO_ 786 BMS_thermalStatus: 8 BMS
 SG_ BMS_powerDissipation : 0|10@1+ (0.02,0) [0|20] "kW" Vector__XXX
 SG_ BMS_flowRequest : 10|7@1+ (0.3,0) [0|38.1] "LPM" Vector__XXX
 SG_ BMS_inletActiveCoolTargetT : 17|9@1+ (0.25,-25) [-25|100] "DegC" Vector__XXX
 SG_ BMS_inletPassiveTargetT : 26|9@1+ (0.25,-25) [-25|100] "DegC" Vector__XXX
 SG_ BMS_inletActiveHeatTargetT : 35|9@1+ (0.25,-25) [-25|100] "DegC" Vector__XXX
 SG_ BMS_minPackTemperature : 44|9@1+ (0.25,-25) [-25|102.75] "DegC" Vector__XXX
 SG_ BMS_maxPackTemperature : 53|9@1+ (0.25,-25) [-25|102.75] "DegC" Vector__XXX
 SG_ BMS_pcsNoFlowRequest : 62|1@1+ (1,0) [0|1] "" Vector__XXX
 SG_ BMS_noFlowRequest : 63|1@1+ (1,0) [0|1] "" Vector__XXX

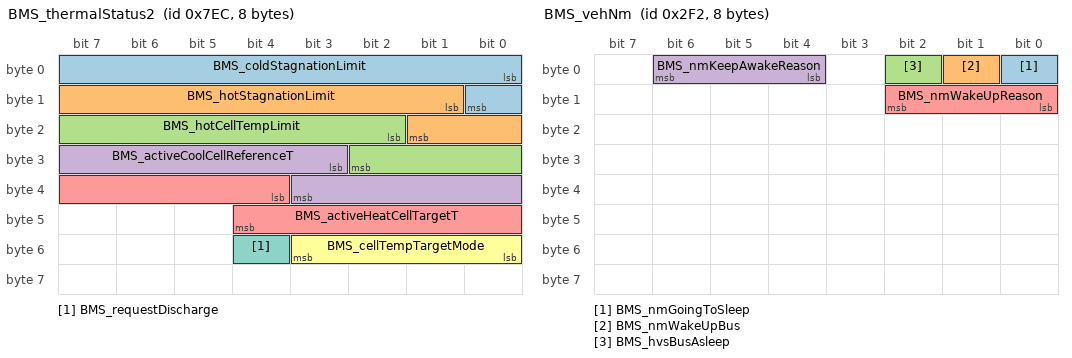
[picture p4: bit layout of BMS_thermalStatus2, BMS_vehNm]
BO_ 2028 BMS_thermalStatus2: 8 BMS
 SG_ BMS_coldStagnationLimit : 0|9@1+ (0.25,-25) [-25|100] "DegC" Vector__XXX
 SG_ BMS_hotStagnationLimit : 9|9@1+ (0.25,-25) [-25|100] "DegC" Vector__XXX
 SG_ BMS_hotCellTempLimit : 18|9@1+ (0.25,-25) [-25|100] "DegC" Vector__XXX
 SG_ BMS_activeCoolCellReferenceT : 27|9@1+ (0.25,-25) [-25|100] "DegC" Vector__XXX
 SG_ BMS_activeHeatCellTargetT : 36|9@1+ (0.25,-25) [-25|100] "DegC" Vector__XXX
 SG_ BMS_cellTempTargetMode : 48|4@1+ (1,0) [0|15] "" Vector__XXX
 SG_ BMS_requestDischarge : 52|1@1+ (1,0) [0|1] "" Vector__XXX

BO_ 754 BMS_vehNm: 8 BMS
 SG_ BMS_nmGoingToSleep : 0|1@1+ (1,0) [0|1] "" Vector__XXX
 SG_ BMS_nmWakeUpBus : 1|1@1+ (1,0) [0|1] "" Vector__XXX
 SG_ BMS_hvsBusAsleep : 2|1@1+ (1,0) [0|1] "" Vector__XXX
 SG_ BMS_nmKeepAwakeReason : 4|3@1+ (1,0) [0|7] "" Vector__XXX
 SG_ BMS_nmWakeUpReason : 8|3@1+ (1,0) [0|7] "" Vector__XXX

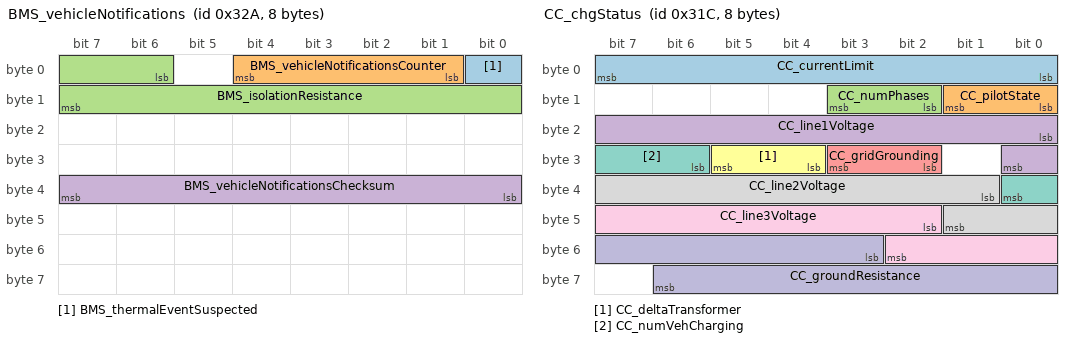
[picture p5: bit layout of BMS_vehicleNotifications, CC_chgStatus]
BO_ 810 BMS_vehicleNotifications: 8 BMS
 SG_ BMS_thermalEventSuspected : 0|1@1+ (1,0) [0|1] "" Vector__XXX
 SG_ BMS_vehicleNotificationsCounter : 1|4@1+ (1,0) [0|15] "" Vector__XXX
 SG_ BMS_isolationResistance : 6|10@1+ (10,0) [0|10000] "kOhm" Vector__XXX
 SG_ BMS_vehicleNotificationsChecksum : 32|8@1+ (1,0) [0|255] "" Vector__XXX

BO_ 1116 CC_alertLog: 8 CC
 SG_ CC_alertID M : 0|15@1+ (1,0) [0|32767] "" Vector__XXX
 SG_ CC_alertType : 15|1@1+ (1,0) [0|1] "" Vector__XXX
 SG_ CC_a001_groundResistance m1 : 16|12@1+ (1000,0) [0|4095000] "" Vector__XXX
 SG_ CC_a003_gfciRmsCurrent m3 : 16|12@1+ (0.001,0) [0|4.095] "" Vector__XXX
 SG_ CC_a003_gfciRmsCurrentAvg m3 : 28|12@1+ (0.001,0) [0|4.095] "" Vector__XXX
 SG_ CC_a003_dcGfciCurrent m3 : 40|10@1- (0.001,0) [-0.512|0.511] "" Vector__XXX
 SG_ CC_a003_gfciFaultReason m3 : 50|4@1+ (1,0) [0|15] "" Vector__XXX
 SG_ CC_a003_gfciFaultBucket m3 : 56|4@1+ (1,0) [0|15] "" Vector__XXX
 SG_ CC_a004_gfciErrorReason m4 : 16|8@1+ (1,0) [0|255] "" Vector__XXX
 SG_ CC_a004_gfciAsicErrorBitfield m4 : 24|8@1+ (1,0) [0|255] "" Vector__XXX
 SG_ CC_a004_gfciSelfTestDuty m4 : 32|16@1- (0.0001,50) [46.7232|53.2767] "" Vector__XXX
 SG_ CC_a004_gfciSelfTestCurrent m4 : 48|16@1- (0.0001,0) [-3.2768|3.2767] "" Vector__XXX
 SG_ CC_a006_line1Current m6 : 16|16@1+ (0.01,0) [0|655.35] "" Vector__XXX
 SG_ CC_a006_line2Current m6 : 32|16@1+ (0.01,0) [0|655.35] "" Vector__XXX
 SG_ CC_a006_line3Current m6 : 48|16@1+ (0.01,0) [0|655.35] "" Vector__XXX
 SG_ CC_a007_inputVoltage m7 : 16|16@1+ (0.01,0) [0|655.35] "" Vector__XXX
 SG_ CC_a007_inputLineVoltage m7 : 32|16@1+ (0.01,0) [0|655.35] "" Vector__XXX
 SG_ CC_a007_inputNeutralVoltage m7 : 48|16@1+ (0.01,0) [0|655.35] "" Vector__XXX
 SG_ CC_a008_inputVoltage m8 : 16|16@1+ (0.01,0) [0|655.35] "" Vector__XXX
 SG_ CC_a008_inputLineVoltage m8 : 32|16@1+ (0.01,0) [0|655.35] "" Vector__XXX
 SG_ CC_a008_inputNeutralVoltage m8 : 48|16@1+ (0.01,0) [0|655.35] "" Vector__XXX
 SG_ CC_a010_line1Voltage m10 : 16|12@1+ (0.1,0) [0|409.5] "" Vector__XXX
 SG_ CC_a010_line2Voltage m10 : 28|12@1+ (0.1,0) [0|409.5] "" Vector__XXX
 SG_ CC_a010_line3Voltage m10 : 40|12@1+ (0.1,0) [0|409.5] "" Vector__XXX
 SG_ CC_a010_line1StuckClosed m10 : 52|1@1+ (1,0) [0|1] "" Vector__XXX
 SG_ CC_a010_line2StuckClosed m10 : 53|1@1+ (1,0) [0|1] "" Vector__XXX
 SG_ CC_a010_line3StuckClosed m10 : 54|1@1+ (1,0) [0|1] "" Vector__XXX
 SG_ CC_a011_pcbaTemp m11 : 16|9@1- (1,88) [-168|343] "" Vector__XXX
 SG_ CC_a012_inputThermopile m12 : 16|12@1+ (1.0e-06,0) [0|0.004095] "" Vector__XXX
 SG_ CC_a012_inputThermopileDvdt m12 : 28|12@1+ (1.0e-06,0) [0|0.004095] "" Vector__XXX
 SG_ CC_a013_handleTemp m13 : 16|9@1- (1,88) [-168|343] "" Vector__XXX
 SG_ CC_a014_failureCause m14 : 16|9@1+ (1,0) [0|511] "" Vector__XXX
 SG_ CC_a014_meterFaultAddress m14 : 25|16@1+ (1,0) [0|65535] "" Vector__XXX
 SG_ CC_a014_meterFaultData m14 : 41|16@1+ (1,0) [0|65535] "" Vector__XXX
 SG_ CC_a014_meterRetryCount m14 : 57|4@1+ (1,0) [0|15] "" Vector__XXX
 SG_ CC_a015_pilotHighVolage m15 : 16|16@1+ (0.001,0) [0|65.535] "" Vector__XXX
 SG_ CC_a015_smState m15 : 32|8@1+ (1,0) [0|255] "" Vector__XXX
 SG_ CC_a027_handleTemperature m27 : 16|12@1- (0.1,0) [-204.8|204.7] "" Vector__XXX
 SG_ CC_a027_handleTempFaultReason m27 : 28|4@1+ (1,0) [0|15] "" Vector__XXX
 SG_ CC_a032_meteringSpiCommsFailure m32 : 16|1@1+ (1,0) [0|1] "" Vector__XXX
 SG_ CC_a032_meteringConfigMismatch m32 : 17|1@1+ (1,0) [0|1] "" Vector__XXX
 SG_ CC_a033_nominalVoltage m33 : 16|9@1+ (0.01,0) [0|5.11] "" Vector__XXX
 SG_ CC_a033_measuredVoltage m33 : 25|9@1+ (0.01,0) [0|5.11] "" Vector__XXX
 SG_ CC_a036_line1Voltage m36 : 16|12@1+ (0.1,0) [0|409.5] "" Vector__XXX
 SG_ CC_a036_line2Voltage m36 : 28|12@1+ (0.1,0) [0|409.5] "" Vector__XXX
 SG_ CC_a036_line3Voltage m36 : 40|12@1+ (0.1,0) [0|409.5] "" Vector__XXX
 SG_ CC_a036_line1StuckOpen m36 : 52|1@1+ (1,0) [0|1] "" Vector__XXX
 SG_ CC_a036_line2StuckOpen m36 : 53|1@1+ (1,0) [0|1] "" Vector__XXX
 SG_ CC_a036_line3StuckOpen m36 : 54|1@1+ (1,0) [0|1] "" Vector__XXX
 SG_ CC_a037_expiredWatchdogModuleId m37 : 16|8@1+ (1,0) [0|255] "" Vector__XXX
 SG_ CC_a037_expiredWatchdogTaskId m37 : 24|8@1+ (1,0) [0|255] "" Vector__XXX
 SG_ CC_a037_expiredWatchdogAppCRC m37 : 32|32@1+ (1,0) [0|4294967295] "" Vector__XXX
 SG_ CC_a038_moduleMiaModuleId m38 : 16|8@1+ (1,0) [0|255] "" Vector__XXX
 SG_ CC_a038_moduleMiaTaskId m38 : 24|8@1+ (1,0) [0|255] "" Vector__XXX
 SG_ CC_a038_moduleMiaAppCRC m38 : 32|32@1+ (1,0) [0|4294967295] "" Vector__XXX
 SG_ CC_a039_intModuleTemperature m39 : 16|9@1- (1,88) [-168|343] "" Vector__XXX
 SG_ CC_a040_handleTemperature m40 : 16|9@1- (1,88) [-168|343] "" Vector__XXX
 SG_ CC_a041_inputThermopile m41 : 16|16@1- (1.0e-06,0) [-0.032768|0.032767] "" Vector__XXX
 SG_ CC_a041_inputThermopileDvdt m41 : 32|16@1- (1.0e-06,0) [-0.032768|0.032767] "" Vector__XXX
 SG_ CC_a042_pcbaTemperature m42 : 16|9@1- (1,88) [-168|343] "" Vector__XXX
 SG_ CC_a044_relayCoilVoltage m44 : 16|8@1+ (0.14,0) [0|35.7] "" Vector__XXX
 SG_ CC_a044_pcbaTemperature m44 : 24|9@1- (1,88) [-168|343] "" Vector__XXX

BO_ 1132 CC_alertMatrix1: 8 CC
 SG_ CC_a001_gndMonIntrptLineSide : 0|1@1+ (1,0) [0|1] "" Vector__XXX
 SG_ CC_a002_gndMonIntrptLoadSide : 1|1@1+ (1,0) [0|1] "" Vector__XXX
 SG_ CC_a003_CCIDTripped : 2|1@1+ (1,0) [0|1] "" Vector__XXX
 SG_ CC_a004_CCIDSelfTestFault : 3|1@1+ (1,0) [0|1] "" Vector__XXX
 SG_ CC_a005_groundedNeutral : 4|1@1+ (1,0) [0|1] "" Vector__XXX
 SG_ CC_a006_inputOverCurrent : 5|1@1+ (1,0) [0|1] "" Vector__XXX
 SG_ CC_a007_inputOverVoltage : 6|1@1+ (1,0) [0|1] "" Vector__XXX
 SG_ CC_a008_inputUnderVoltage : 7|1@1+ (1,0) [0|1] "" Vector__XXX
 SG_ CC_a009_inputMiswired : 8|1@1+ (1,0) [0|1] "" Vector__XXX
 SG_ CC_a010_contactorWelded : 9|1@1+ (1,0) [0|1] "" Vector__XXX
 SG_ CC_a011_ambientOT : 10|1@1+ (1,0) [0|1] "" Vector__XXX
 SG_ CC_a012_wallPlugOT : 11|1@1+ (1,0) [0|1] "" Vector__XXX
 SG_ CC_a013_vehConnOT : 12|1@1+ (1,0) [0|1] "" Vector__XXX
 SG_ CC_a014_mcuSelfTestFault : 13|1@1+ (1,0) [0|1] "" Vector__XXX
 SG_ CC_a015_PilotAFault : 14|1@1+ (1,0) [0|1] "" Vector__XXX
 SG_ CC_a016_PilotBFault : 15|1@1+ (1,0) [0|1] "" Vector__XXX
 SG_ CC_a017_PilotCFault : 16|1@1+ (1,0) [0|1] "" Vector__XXX
 SG_ CC_a018_PilotDFault : 17|1@1+ (1,0) [0|1] "" Vector__XXX
 SG_ CC_a019_proxDisconnected : 18|1@1+ (1,0) [0|1] "" Vector__XXX
 SG_ CC_a020_3vRailIncorrect : 19|1@1+ (1,0) [0|1] "" Vector__XXX
 SG_ CC_a021_CB_noMaster : 20|1@1+ (1,0) [0|1] "" Vector__XXX
 SG_ CC_a022_CB_tooManyMasters : 21|1@1+ (1,0) [0|1] "" Vector__XXX
 SG_ CC_a023_CB_tooManySlaves : 22|1@1+ (1,0) [0|1] "" Vector__XXX
 SG_ CC_a024_CB_masterISetTooLow : 23|1@1+ (1,0) [0|1] "" Vector__XXX
 SG_ CC_a025_evseTemp : 24|1@1+ (1,0) [0|1] "" Vector__XXX
 SG_ CC_a026_wallPlugTemp : 25|1@1+ (1,0) [0|1] "" Vector__XXX
 SG_ CC_a027_vehicleHandleTemp : 26|1@1+ (1,0) [0|1] "" Vector__XXX
 SG_ CC_a028_CB_rotarySelect : 27|1@1+ (1,0) [0|1] "" Vector__XXX
 SG_ CC_a029_PilotFFault : 28|1@1+ (1,0) [0|1] "" Vector__XXX
 SG_ CC_a030_masterSlaveMismatch : 29|1@1+ (1,0) [0|1] "" Vector__XXX
 SG_ CC_a031_pllLockLost : 30|1@1+ (1,0) [0|1] "" Vector__XXX
 SG_ CC_a032_meteringFailure : 31|1@1+ (1,0) [0|1] "" Vector__XXX
 SG_ CC_a033_vRefOutOfRange : 32|1@1+ (1,0) [0|1] "" Vector__XXX
 SG_ CC_a034_bootAlert : 33|1@1+ (1,0) [0|1] "" Vector__XXX
 SG_ CC_a035_CCIDCalibration : 34|1@1+ (1,0) [0|1] "" Vector__XXX
 SG_ CC_a036_contactorStuckOpen : 35|1@1+ (1,0) [0|1] "" Vector__XXX
 SG_ CC_a037_internalModuleWatchdogEx : 36|1@1+ (1,0) [0|1] "" Vector__XXX
 SG_ CC_a038_internalModuleMia : 37|1@1+ (1,0) [0|1] "" Vector__XXX
 SG_ CC_a039_internalModuleOverTemp : 38|1@1+ (1,0) [0|1] "" Vector__XXX
 SG_ CC_a040_handleTempFoldback : 39|1@1+ (1,0) [0|1] "" Vector__XXX
 SG_ CC_a041_inputWiringFoldback : 40|1@1+ (1,0) [0|1] "" Vector__XXX
 SG_ CC_a042_pcbaTempFoldback : 41|1@1+ (1,0) [0|1] "" Vector__XXX
 SG_ CC_a043_configurationRequired : 42|1@1+ (1,0) [0|1] "" Vector__XXX
 SG_ CC_a044_relayCoilVoltageRational : 43|1@1+ (1,0) [0|1] "" Vector__XXX
 SG_ CC_a045_ACPowerLoss : 44|1@1+ (1,0) [0|1] "" Vector__XXX
 SG_ CC_a046_GFCIConfigInvalid : 45|1@1+ (1,0) [0|1] "" Vector__XXX
 SG_ CC_a047_MDMotorContFault : 46|1@1+ (1,0) [0|1] "" Vector__XXX
 SG_ CC_a048_ACMDAdapterFault : 47|1@1+ (1,0) [0|1] "" Vector__XXX
 SG_ CC_a049_rs485Fault : 48|1@1+ (1,0) [0|1] "" Vector__XXX
 SG_ CC_a050_eFuseFault : 49|1@1+ (1,0) [0|1] "" Vector__XXX
 SG_ CC_a051_chcCriticalFault : 50|1@1+ (1,0) [0|1] "" Vector__XXX
 SG_ CC_a052_vRefOutOfRangePWM : 51|1@1+ (1,0) [0|1] "" Vector__XXX
 SG_ CC_a057_chcVitalsRequestFailure : 56|1@1+ (1,0) [0|1] "" Vector__XXX
 SG_ CC_a060_persistenceFault : 59|1@1+ (1,0) [0|1] "" Vector__XXX
 SG_ CC_a061_unfinishedCommissioning : 60|1@1+ (1,0) [0|1] "" Vector__XXX

BO_ 796 CC_chgStatus: 8 CC
 SG_ CC_currentLimit : 0|8@1+ (0.5,0) [0|127.5] "A" Vector__XXX
 SG_ CC_pilotState : 8|2@1+ (1,0) [0|3] "" Vector__XXX
 SG_ CC_numPhases : 10|2@1+ (1,0) [0|3] "" Vector__XXX
 SG_ CC_line1Voltage : 16|9@1+ (1,0) [0|511] "V" Vector__XXX
 SG_ CC_gridGrounding : 26|2@1+ (1,0) [0|3] "" Vector__XXX
 SG_ CC_deltaTransformer : 28|2@1+ (1,0) [0|3] "" Vector__XXX
 SG_ CC_numVehCharging : 30|3@1+ (1,0) [0|7] "" Vector__XXX
 SG_ CC_line2Voltage : 33|9@1+ (1,0) [0|511] "V" Vector__XXX
 SG_ CC_line3Voltage : 42|9@1+ (1,0) [0|511] "V" Vector__XXX
 SG_ CC_groundResistance : 51|12@1+ (1,0) [0|4094] "kOhm" Vector__XXX

BO_ 797 CC_chgStatus2: 8 CC
 SG_ CC_chgStatus2Index M : 0|8@1+ (1,0) [0|255] "" Vector__XXX
 SG_ CC_buttonState m0 : 8|1@1+ (1,0) [0|1] "" Vector__XXX

BO_ 812 CC_logData: 8 CC
 SG_ CC_logIndex M : 0|8@1+ (1,0) [0|255] "" Vector__XXX
 SG_ CC_activeConnectorID m0 : 8|8@1+ (1,0) [0|255] "" Vector__XXX
 SG_ CC_temperature1 m0 : 16|8@1- (1,88) [-40|215] "DegC" Vector__XXX
 SG_ CC_temperature2 m0 : 24|8@1- (1,88) [-40|215] "DegC" Vector__XXX
 SG_ CC_temperature3 m0 : 32|8@1- (1,88) [-40|215] "DegC" Vector__XXX
 SG_ CC_contactor1Closed m0 : 40|2@1+ (1,0) [0|3] "" Vector__XXX
 SG_ CC_contactor2Closed m0 : 42|2@1+ (1,0) [0|3] "" Vector__XXX
 SG_ CC_temperature4 m0 : 44|8@1- (1,88) [-40|215] "DegC" Vector__XXX
 SG_ CC_conn1Current m1 : 8|8@1+ (0.5,0) [0|127.5] "A" Vector__XXX
 SG_ CC_conn2Current m2 : 8|8@1+ (0.5,0) [0|127.5] "A" Vector__XXX
 SG_ CC_conn3Current m3 : 8|8@1+ (0.5,0) [0|127.5] "A" Vector__XXX
 SG_ CC_conn4Current m4 : 8|8@1+ (0.5,0) [0|127.5] "A" Vector__XXX
 SG_ CC_lifetimei2t m10 : 32|32@1+ (0.1,0) [0|429496729.5] "A2h" Vector__XXX
 SG_ CC_lifetimeCtrCycles m11 : 8|28@1+ (1,0) [0|268435455] "" Vector__XXX
 SG_ CC_lifetimeCtrCyclesLoaded m11 : 36|28@1+ (1,0) [0|268435455] "" Vector__XXX
 SG_ CC_lifetimeAlertCount m12 : 8|28@1+ (1,0) [0|268435455] "" Vector__XXX
 SG_ CC_lifetimeThermalFoldbacks m12 : 36|28@1+ (1,0) [0|268435455] "" Vector__XXX
 SG_ CC_lifetimeAvgStartupTemp m13 : 36|28@1- (0.1,0) [-13421772.8|13421772.7] "degC" Vector__XXX

BO_ 870 CMPD_info: 8 CMPD
 SG_ CMPD_infoIndex M : 0|8@1+ (1,0) [0|255] "" Vector__XXX
 SG_ CMPD_infoBuildType m10 : 8|8@1+ (1,0) [0|255] "" Vector__XXX
 SG_ CMPD_infoBuildConfigId m10 : 16|16@1+ (1,0) [0|65535] "" Vector__XXX
 SG_ CMPD_infoHardwareId m10 : 32|16@1+ (1,0) [0|65535] "" Vector__XXX
 SG_ CMPD_infoComponentId m10 : 48|16@1+ (1,0) [0|65535] "" Vector__XXX
 SG_ CMPD_infoPcbaId m11 : 16|8@1+ (1,0) [0|255] "" Vector__XXX
 SG_ CMPD_infoAssemblyId m11 : 24|8@1+ (1,0) [0|255] "" Vector__XXX
 SG_ CMPD_infoUsageId m11 : 32|16@1+ (1,0) [0|65535] "" Vector__XXX
 SG_ CMPD_infoSubUsageId m11 : 48|16@1+ (1,0) [0|65535] "" Vector__XXX

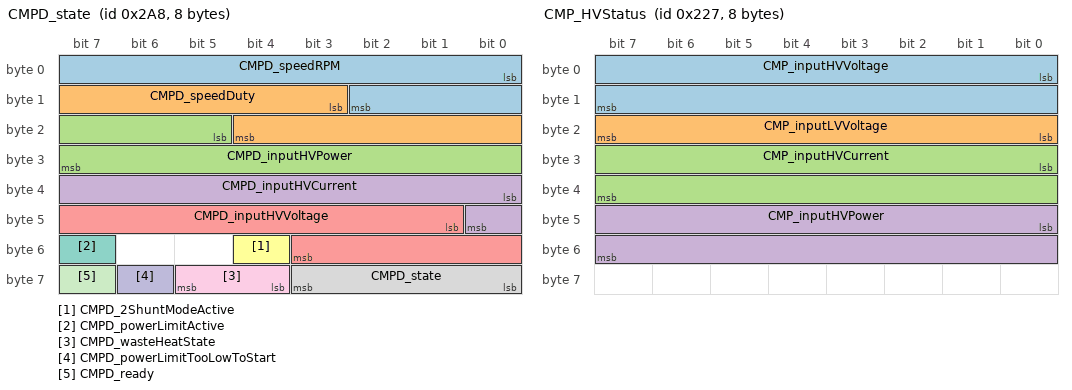
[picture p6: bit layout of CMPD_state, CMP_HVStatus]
BO_ 680 CMPD_state: 8 CMPD
 SG_ CMPD_speedRPM : 0|11@1+ (10,0) [0|20000] "RPM" Vector__XXX
 SG_ CMPD_speedDuty : 11|10@1+ (0.1,0) [0|100] "%" Vector__XXX
 SG_ CMPD_inputHVPower : 21|11@1+ (10,0) [0|20000] "W" Vector__XXX
 SG_ CMPD_inputHVCurrent : 32|9@1+ (0.1,0) [0|50] "A" Vector__XXX
 SG_ CMPD_inputHVVoltage : 41|11@1+ (0.5,0) [0|1000] "V" Vector__XXX
 SG_ CMPD_2ShuntModeActive : 52|1@1+ (1,0) [0|1] "" Vector__XXX
 SG_ CMPD_powerLimitActive : 55|1@1+ (1,0) [0|1] "" Vector__XXX
 SG_ CMPD_state : 56|4@1+ (1,0) [0|15] "" Vector__XXX
 SG_ CMPD_wasteHeatState : 60|2@1+ (1,0) [0|3] "" Vector__XXX
 SG_ CMPD_powerLimitTooLowToStart : 62|1@1+ (1,0) [0|1] "" Vector__XXX
 SG_ CMPD_ready : 63|1@1+ (1,0) [0|1] "" Vector__XXX

BO_ 551 CMP_HVStatus: 8 CMP
 SG_ CMP_inputHVVoltage : 0|16@1+ (0.1,0) [0|6553.4] "V" Vector__XXX
 SG_ CMP_inputLVVoltage : 16|8@1+ (0.1,0) [0|25.5] "V" Vector__XXX
 SG_ CMP_inputHVCurrent : 24|16@1+ (0.1,0) [0|6553.4] "A" Vector__XXX
 SG_ CMP_inputHVPower : 40|16@1+ (1,0) [0|65534] "W" Vector__XXX

BO_ 867 CMP_info: 8 CMP
 SG_ CMP_infoIndex M : 0|8@1+ (1,0) [0|255] "" Vector__XXX
 SG_ CMP_infoBuildType m10 : 8|8@1+ (1,0) [0|255] "" Vector__XXX
 SG_ CMP_infoBuildConfigId m10 : 16|16@1+ (1,0) [0|65535] "" Vector__XXX
 SG_ CMP_infoHardwareId m10 : 32|16@1+ (1,0) [0|65535] "" Vector__XXX
 SG_ CMP_infoComponentId m10 : 48|16@1+ (1,0) [0|65535] "" Vector__XXX
 SG_ CMP_infoPcbaId m11 : 16|8@1+ (1,0) [0|255] "" Vector__XXX
 SG_ CMP_infoAssemblyId m11 : 24|8@1+ (1,0) [0|255] "" Vector__XXX
 SG_ CMP_infoUsageId m11 : 32|16@1+ (1,0) [0|65535] "" Vector__XXX
 SG_ CMP_infoSubUsageId m11 : 48|16@1+ (1,0) [0|65535] "" Vector__XXX
 SG_ CMP_infoPlatformType m13 : 8|8@1+ (1,0) [0|255] "" Vector__XXX
 SG_ CMP_infoAppCrc m13 : 32|32@1+ (1,0) [0|4294967295] "" Vector__XXX
 SG_ CMP_infoBootUdsProtoVersion m20 : 8|8@1+ (1,0) [0|255] "" Vector__XXX
 SG_ CMP_infoBootCrc m20 : 32|32@1+ (1,0) [0|4294967295] "" Vector__XXX

BO_ 1767 CP_IsoTpPipeToPncd: 8 CP
 SG_ CP_isoTpToPncdData : 0|64@1+ (1,0) [0|1.84467440737e+19] "" Vector__XXX

CM_ BO_ 1343 "High-voltage battery management system message: alert log";
CM_ SG_ 1343 BMS_alertID "High-voltage battery management system: alert ID";
CM_ SG_ 1343 BMS_alertSet "High-voltage battery management system: alert set";
CM_ SG_ 1343 BMS_a001_gatewayPackEnergy "High-voltage battery management system: a001 gateway pack energy";
CM_ SG_ 1343 BMS_a001_expectedPackEnergy "High-voltage battery management system: a001 expected pack energy";
CM_ SG_ 1343 BMS_a002_gatewayPackPerformanceD "High-voltage battery management system: a002 gateway pack performance deviation";
CM_ SG_ 1343 BMS_a002_expectedPackPerformance "High-voltage battery management system: a002 expected pack performance deviation";
CM_ SG_ 1343 BMS_a002_bmsPackMass "High-voltage battery management system: a002 bms pack mass";
CM_ SG_ 1343 BMS_a003_calBlockData_0 "High-voltage battery management system: a003 cal block data 0";
CM_ SG_ 1343 BMS_a007_minPackTemperature "High-voltage battery management system: a007 min pack temperature";
CM_ SG_ 1343 BMS_a007_packCurrent "High-voltage battery management system: a007 pack current";
CM_ SG_ 1343 BMS_a007_idealCurrentTarget "High-voltage battery management system: a007 ideal current target";
CM_ SG_ 1343 BMS_a017_packCurrent "High-voltage battery management system: a017 pack current";
CM_ SG_ 1343 BMS_a017_ovBrickVID "High-voltage battery management system: a017 ov brick VID";
CM_ SG_ 1343 BMS_a017_ovBrickV "High-voltage battery management system: a017 ov brick v";
CM_ SG_ 1343 BMS_a018_packCurrent "High-voltage battery management system: a018 pack current";
CM_ SG_ 1343 BMS_a018_uvBrickVID "High-voltage battery management system: a018 uv brick VID";
CM_ SG_ 1343 BMS_a018_uvBrickV "High-voltage battery management system: a018 uv brick v";
CM_ SG_ 1343 BMS_a019_coolantInletT "High-voltage battery management system: a019 coolant inlet t";
CM_ SG_ 1343 BMS_a019_activeCoolingTarget "High-voltage battery management system: a019 active cooling target";
CM_ SG_ 1343 BMS_a019_maxBrickT "High-voltage battery management system: a019 max brick t";
CM_ SG_ 1343 BMS_a019_maxBrickTID "High-voltage battery management system: a019 max brick TID";
CM_ SG_ 1343 BMS_a021_chargeViolation "High-voltage battery management system: a021 charge violation";
CM_ SG_ 1343 BMS_a021_currentLimit "High-voltage battery management system: a021 current limit";
CM_ SG_ 1343 BMS_a021_packCurrent "High-voltage battery management system: a021 pack current";
CM_ SG_ 1343 BMS_a022_chargeAccumulatorViolat "High-voltage battery management system: a022 charge accumulator violation";
CM_ SG_ 1343 BMS_a022_chargeAccumulatorValue "High-voltage battery management system: a022 charge accumulator value";
CM_ SG_ 1343 BMS_a022_chargeAccumulatorLimit "High-voltage battery management system: a022 charge accumulator limit";
CM_ SG_ 1343 BMS_a023_ovStackDeviceID "High-voltage battery management system: a023 ov stack device ID";
CM_ SG_ 1343 BMS_a023_ovStackV "High-voltage battery management system: a023 ov stack v";
CM_ SG_ 1343 BMS_a024_brickID "High-voltage battery management system: a024 brick ID";
CM_ SG_ 1343 BMS_a024_deltaV "High-voltage battery management system: a024 delta v";
CM_ SG_ 1343 BMS_a024_avgDvPrev "High-voltage battery management system: a024 avg dv prev";
CM_ SG_ 1343 BMS_a024_packCurrent "High-voltage battery management system: a024 pack current";
CM_ SG_ 1343 BMS_a027_swIsolationCount "High-voltage battery management system: a027 sw isolation count";
CM_ SG_ 1343 BMS_a027_swIsoDegradationCount "High-voltage battery management system: a027 sw iso degradation count";
CM_ SG_ 1343 BMS_a030_worstBrickID "High-voltage battery management system: a030 worst brick ID";
CM_ SG_ 1343 BMS_a030_maxBrickImpedance "High-voltage battery management system: a030 max brick impedance";
CM_ SG_ 1343 BMS_a030_maxNormalizedImpedanceD "High-voltage battery management system: a030 max normalized impedance dev";
CM_ SG_ 1343 BMS_a030_faultThreshold "High-voltage battery management system: a030 fault threshold";
CM_ SG_ 1343 BMS_a030_numBricks "High-voltage battery management system: a030 num bricks";
CM_ SG_ 1343 BMS_a030_worstBrickSoc "High-voltage battery management system: a030 worst brick soc";
CM_ SG_ 1343 BMS_a035_isoR "High-voltage battery management system: a035 iso r";
CM_ SG_ 1343 BMS_a035_mode "High-voltage battery management system: a035 mode";
CM_ SG_ 1343 BMS_a035_activeSideVNoR "High-voltage battery management system: a035 active side v no r";
CM_ SG_ 1343 BMS_a035_activeSideVWithR "High-voltage battery management system: a035 active side v with r";
CM_ SG_ 1343 BMS_a035_passiveSideVNoR "High-voltage battery management system: a035 passive side v no r";
CM_ SG_ 1343 BMS_a035_passiveSideVWithR "High-voltage battery management system: a035 passive side v with r";
CM_ SG_ 1343 BMS_a037_floodPort1State "High-voltage battery management system: a037 flood port1 state";
CM_ SG_ 1343 BMS_a037_floodPort1Voltage "High-voltage battery management system: a037 flood port1 voltage";
CM_ SG_ 1343 BMS_a037_floodPort2State "High-voltage battery management system: a037 flood port2 state";
CM_ SG_ 1343 BMS_a037_floodPort2Voltage "High-voltage battery management system: a037 flood port2 voltage";
CM_ SG_ 1343 BMS_a039_dcLinkVoltage "High-voltage battery management system: a039 dc link voltage";
CM_ SG_ 1343 BMS_a039_packVoltage "High-voltage battery management system: a039 pack voltage";
CM_ SG_ 1343 BMS_a039_packContactorState "High-voltage battery management system: a039 pack contactor state";
CM_ SG_ 1343 BMS_a039_packCurrent "High-voltage battery management system: a039 pack current";
CM_ SG_ 1343 BMS_a039_maxBrickV "High-voltage battery management system: a039 max brick v";
CM_ SG_ 1343 BMS_a039_state "High-voltage battery management system: a039 state";
CM_ SG_ 1343 BMS_a041_resetType "High-voltage battery management system: a041 reset type";
CM_ SG_ 1343 BMS_a050_MIA_numBadReadings "High-voltage battery management system: a050 MIA num bad readings";
CM_ SG_ 1343 BMS_a050_MIA_numSnaReadings "High-voltage battery management system: a050 MIA num sna readings";
CM_ SG_ 1343 BMS_a051_hvp1V5Ref "High-voltage battery management system: a051 hvp1 V5 ref";
CM_ SG_ 1343 BMS_a051_hvp3V0Ref "High-voltage battery management system: a051 hvp3 V0 ref";
CM_ SG_ 1343 BMS_a051_bms3V0Ref "High-voltage battery management system: a051 bms3 V0 ref";
CM_ SG_ 1343 BMS_a056_standbySupplyOutV "High-voltage battery management system: a056 standby supply out v";
CM_ SG_ 1343 BMS_a056_packVoltage "High-voltage battery management system: a056 pack voltage";
CM_ SG_ 1343 BMS_a056_minBrickVoltage "High-voltage battery management system: a056 min brick voltage";
CM_ SG_ 1343 BMS_a056_standbyEnabled "High-voltage battery management system: a056 standby enabled";
CM_ SG_ 1343 BMS_a056_standbySwGood "High-voltage battery management system: a056 standby sw good";
CM_ SG_ 1343 BMS_a056_ssOutTooHigh "High-voltage battery management system: a056 ss out too high";
CM_ SG_ 1343 BMS_a056_ssOutTooLow "High-voltage battery management system: a056 ss out too low";
CM_ SG_ 1343 BMS_a056_ssStuckOn "High-voltage battery management system: a056 ss stuck on";
CM_ SG_ 1343 BMS_a056_ssStuckOff "High-voltage battery management system: a056 ss stuck off";
CM_ SG_ 1343 BMS_a058_bandoThmModelState "High-voltage battery management system: a058 bando thm model state";
CM_ SG_ 1343 BMS_a058_thermistorTempsInvalid "High-voltage battery management system: a058 thermistor temps invalid";
CM_ SG_ 1343 BMS_a058_inletCoolantTempInvalid "High-voltage battery management system: a058 inlet coolant temp invalid";
CM_ SG_ 1343 BMS_a058_ambientTempInvalid "High-voltage battery management system: a058 ambient temp invalid";
CM_ SG_ 1343 BMS_a058_flowRateInvalid "High-voltage battery management system: a058 flow rate invalid";
CM_ SG_ 1343 BMS_a058_brickDissipationInvalid "High-voltage battery management system: a058 brick dissipation invalid";
CM_ SG_ 1343 BMS_a058_sanityCheckFailed "High-voltage battery management system: a058 sanity check failed";
CM_ SG_ 1343 BMS_a058_tempDelta1 "High-voltage battery management system: a058 temp delta1";
CM_ SG_ 1343 BMS_a058_tempDelta2 "High-voltage battery management system: a058 temp delta2";
CM_ SG_ 1343 BMS_a058_tempDelta3 "High-voltage battery management system: a058 temp delta3";
CM_ SG_ 1343 BMS_a058_tempDelta4 "High-voltage battery management system: a058 temp delta4";
CM_ SG_ 1343 BMS_a059_sumBrickVoltages "High-voltage battery management system: a059 sum brick voltages";
CM_ SG_ 1343 BMS_a059_packVoltage "High-voltage battery management system: a059 pack voltage";
CM_ SG_ 1343 BMS_a062_state "High-voltage battery management system: a062 state";
CM_ SG_ 1343 BMS_a062_minBrickVId "High-voltage battery management system: a062 min brick v id";
CM_ SG_ 1343 BMS_a062_minBrickVoltage "High-voltage battery management system: a062 min brick voltage";
CM_ SG_ 1343 BMS_a062_maxBrickVId "High-voltage battery management system: a062 max brick v id";
CM_ SG_ 1343 BMS_a062_maxBrickVoltage "High-voltage battery management system: a062 max brick voltage";
CM_ SG_ 1343 BMS_a063_cpFaultInV "High-voltage battery management system: a063 cp fault in v";
CM_ SG_ 1343 BMS_a064_minBrickSOCID "High-voltage battery management system: a064 min brick SOCID";
CM_ SG_ 1343 BMS_a064_minBrickSOC "High-voltage battery management system: a064 min brick SOC";
CM_ SG_ 1343 BMS_a064_maxBrickSOCID "High-voltage battery management system: a064 max brick SOCID";
CM_ SG_ 1343 BMS_a064_maxBrickSOC "High-voltage battery management system: a064 max brick SOC";
CM_ SG_ 1343 BMS_a064_avgBrickSOC "High-voltage battery management system: a064 avg brick SOC";
CM_ SG_ 1343 BMS_a065_minBrickCacId "High-voltage battery management system: a065 min brick cac id";
CM_ SG_ 1343 BMS_a065_minBrickCac "High-voltage battery management system: a065 min brick cac";
CM_ SG_ 1343 BMS_a065_avgBrickCac "High-voltage battery management system: a065 avg brick cac";
CM_ SG_ 1343 BMS_a065_modCacImbalancePct "High-voltage battery management system: a065 mod cac imbalance pct";
CM_ SG_ 1343 BMS_a066_minBrickSocId "High-voltage battery management system: a066 min brick soc id";
CM_ SG_ 1343 BMS_a066_minBrickSocByOcvMax "High-voltage battery management system: a066 min brick soc by ocv max";
CM_ SG_ 1343 BMS_a066_maxBrickSocId "High-voltage battery management system: a066 max brick soc id";
CM_ SG_ 1343 BMS_a066_maxBrickSocByOcvMin "High-voltage battery management system: a066 max brick soc by ocv min";
CM_ SG_ 1343 BMS_a066_maxBrickSoc "High-voltage battery management system: a066 max brick soc";
CM_ SG_ 1343 BMS_a066_avgBrickSoc "High-voltage battery management system: a066 avg brick soc";
CM_ SG_ 1343 BMS_a067_minBrickCacId "High-voltage battery management system: a067 min brick cac id";
CM_ SG_ 1343 BMS_a067_minBrickCac "High-voltage battery management system: a067 min brick cac";
CM_ SG_ 1343 BMS_a067_avgBrickCac "High-voltage battery management system: a067 avg brick cac";
CM_ SG_ 1343 BMS_a067_modCacImbalancePct "High-voltage battery management system: a067 mod cac imbalance pct";
CM_ SG_ 1343 BMS_a068_minBrickCacId "High-voltage battery management system: a068 min brick cac id";
CM_ SG_ 1343 BMS_a068_minBrickCac "High-voltage battery management system: a068 min brick cac";
CM_ SG_ 1343 BMS_a068_avgBrickCac "High-voltage battery management system: a068 avg brick cac";
CM_ SG_ 1343 BMS_a068_modCacImbalancePct "High-voltage battery management system: a068 mod cac imbalance pct";
CM_ SG_ 1343 BMS_a069_dischargePowerPackVolta "High-voltage battery management system: a069 discharge power pack voltage floor";
CM_ SG_ 1343 BMS_a069_dischargePowerBrickVolt "High-voltage battery management system: a069 discharge power brick voltage floor";
CM_ SG_ 1343 BMS_a069_SOC "High-voltage battery management system: a069 SOC";
CM_ SG_ 1343 BMS_a069_minBrickT "High-voltage battery management system: a069 min brick t";
CM_ SG_ 1343 BMS_a069_minBrickVLimit "High-voltage battery management system: a069 min brick v limit";
CM_ SG_ 1343 BMS_a069_minBrickV "High-voltage battery management system: a069 min brick v";
CM_ SG_ 1343 BMS_a070_state "High-voltage battery management system: a070 state";
CM_ SG_ 1343 BMS_a070_minBrickVId "High-voltage battery management system: a070 min brick v id";
CM_ SG_ 1343 BMS_a070_minBrickVoltage "High-voltage battery management system: a070 min brick voltage";
CM_ SG_ 1343 BMS_a070_maxBrickVId "High-voltage battery management system: a070 max brick v id";
CM_ SG_ 1343 BMS_a070_maxBrickVoltage "High-voltage battery management system: a070 max brick voltage";
CM_ SG_ 1343 BMS_a071_stateRequest "High-voltage battery management system: a071 state request";
CM_ SG_ 1343 BMS_a071_state "High-voltage battery management system: a071 state";
CM_ SG_ 1343 BMS_a071_transitionAlertId "High-voltage battery management system: a071 transition alert id";
CM_ SG_ 1343 BMS_a074_maxBrickVTarget "High-voltage battery management system: a074 max brick v target";
CM_ SG_ 1343 BMS_a074_maxBrickV "High-voltage battery management system: a074 max brick v";
CM_ SG_ 1343 BMS_a075_chargeType "High-voltage battery management system: a075 charge type";
CM_ SG_ 1343 BMS_a076_netAh "High-voltage battery management system: a076 net ah";
CM_ SG_ 1343 BMS_a076_tetheringActive "High-voltage battery management system: a076 tethering active";
CM_ SG_ 1343 BMS_a078_peakDchInChg "High-voltage battery management system: a078 peak dch in chg";
CM_ SG_ 1343 BMS_a079_maxBrickVTarget "High-voltage battery management system: a079 max brick v target";
CM_ SG_ 1343 BMS_a079_maxBrickV "High-voltage battery management system: a079 max brick v";
CM_ SG_ 1343 BMS_a081_stateRequest "High-voltage battery management system: a081 state request";
CM_ SG_ 1343 BMS_a081_firstBlockingAlertId "High-voltage battery management system: a081 first blocking alert id";
CM_ SG_ 1343 BMS_a081_secondBlockingAlertId "High-voltage battery management system: a081 second blocking alert id";
CM_ SG_ 1343 BMS_a081_thirdBlockingAlertId "High-voltage battery management system: a081 third blocking alert id";
CM_ SG_ 1343 BMS_a081_fourthBlockingAlertId "High-voltage battery management system: a081 fourth blocking alert id";
CM_ SG_ 1343 BMS_a081_totalAlertCount "High-voltage battery management system: a081 total alert count";
CM_ SG_ 1343 BMS_a082_stateRequest "High-voltage battery management system: a082 state request";
CM_ SG_ 1343 BMS_a082_firstAlertId "High-voltage battery management system: a082 first alert id";
CM_ SG_ 1343 BMS_a082_secondAlertId "High-voltage battery management system: a082 second alert id";
CM_ SG_ 1343 BMS_a082_thirdAlertId "High-voltage battery management system: a082 third alert id";
CM_ SG_ 1343 BMS_a082_fourthAlertId "High-voltage battery management system: a082 fourth alert id";
CM_ SG_ 1343 BMS_a082_totalAlertCount "High-voltage battery management system: a082 total alert count";
CM_ SG_ 1343 BMS_a083_packContactorRequest "High-voltage battery management system: a083 pack contactor request";
CM_ SG_ 1343 BMS_a085_packContactorSetStatePr "High-voltage battery management system: a085 pack contactor set state prev";
CM_ SG_ 1343 BMS_a085_packContactorSetState "High-voltage battery management system: a085 pack contactor set state";
CM_ SG_ 1343 BMS_a085_packContactorSetRe_0001 "High-voltage battery management system: a085 pack contactor set request prev";
CM_ SG_ 1343 BMS_a085_packContactorSetRequest "High-voltage battery management system: a085 pack contactor set request";
CM_ SG_ 1343 BMS_a086_fcContactorSetStatePrev "High-voltage battery management system: a086 fc contactor set state prev";
CM_ SG_ 1343 BMS_a086_fcContactorSetState "High-voltage battery management system: a086 fc contactor set state";
CM_ SG_ 1343 BMS_a086_fcContactorSetRequestPr "High-voltage battery management system: a086 fc contactor set request prev";
CM_ SG_ 1343 BMS_a086_fcContactorSetRequest "High-voltage battery management system: a086 fc contactor set request";
CM_ SG_ 1343 BMS_a087_blockingAlert "High-voltage battery management system: a087 blocking alert";
CM_ SG_ 1343 BMS_a090_GTWmessageTout "High-voltage battery management system: a090 GT wmessage tout";
CM_ SG_ 1343 BMS_a097_missingFrame "High-voltage battery management system: a097 missing frame";
CM_ SG_ 1343 BMS_a097_timeout "High-voltage battery management system: a097 timeout";
CM_ SG_ 1343 BMS_a098_breakLocationA "High-voltage battery management system: a098 break location a";
CM_ SG_ 1343 BMS_a098_bmbCommStatusTypeA "High-voltage battery management system: a098 bmb comm status type a";
CM_ SG_ 1343 BMS_a098_breakLocationB "High-voltage battery management system: a098 break location b";
CM_ SG_ 1343 BMS_a098_bmbCommStatusTypeB "High-voltage battery management system: a098 bmb comm status type b";
CM_ SG_ 1343 BMS_a098_alertFromHvp "High-voltage battery management system: a098 alert from hvp";
CM_ SG_ 1343 BMS_a099_breakLocationA "High-voltage battery management system: a099 break location a";
CM_ SG_ 1343 BMS_a099_bmbCommStatusTypeA "High-voltage battery management system: a099 bmb comm status type a";
CM_ SG_ 1343 BMS_a099_breakLocationB "High-voltage battery management system: a099 break location b";
CM_ SG_ 1343 BMS_a099_bmbCommStatusTypeB "High-voltage battery management system: a099 bmb comm status type b";
CM_ SG_ 1343 BMS_a099_bmbChainBreakType "High-voltage battery management system: a099 bmb chain break type";
CM_ SG_ 1343 BMS_a099_alertFromHvp "High-voltage battery management system: a099 alert from hvp";
CM_ SG_ 1343 BMS_a100_testTrigger "High-voltage battery management system: a100 test trigger";
CM_ SG_ 1343 BMS_a100_setFromNvm "High-voltage battery management system: a100 set from nvm";
CM_ SG_ 1343 BMS_a100_voltageDeviation "High-voltage battery management system: a100 voltage deviation";
CM_ SG_ 1343 BMS_a100_voltageLoss "High-voltage battery management system: a100 voltage loss";
CM_ SG_ 1343 BMS_a105_tSenseFailedModule1 "High-voltage battery management system: a105 t sense failed module1";
CM_ SG_ 1343 BMS_a105_avgBrickTModule1 "High-voltage battery management system: a105 avg brick t module1";
CM_ SG_ 1343 BMS_a105_tSenseFailedModule2 "High-voltage battery management system: a105 t sense failed module2";
CM_ SG_ 1343 BMS_a105_avgBrickTModule2 "High-voltage battery management system: a105 avg brick t module2";
CM_ SG_ 1343 BMS_a105_tSenseFailedModule3 "High-voltage battery management system: a105 t sense failed module3";
CM_ SG_ 1343 BMS_a105_avgBrickTModule3 "High-voltage battery management system: a105 avg brick t module3";
CM_ SG_ 1343 BMS_a105_tSenseFailedModule4 "High-voltage battery management system: a105 t sense failed module4";
CM_ SG_ 1343 BMS_a105_avgBrickTModule4 "High-voltage battery management system: a105 avg brick t module4";
CM_ SG_ 1343 BMS_a105_inletTemp "High-voltage battery management system: a105 inlet temp";
CM_ SG_ 1343 BMS_a106_minBrickT "High-voltage battery management system: a106 min brick t";
CM_ SG_ 1343 BMS_a106_maxBrickT "High-voltage battery management system: a106 max brick t";
CM_ SG_ 1343 BMS_a106_avgBrickT "High-voltage battery management system: a106 avg brick t";
CM_ SG_ 1343 BMS_a106_inletTemp "High-voltage battery management system: a106 inlet temp";
CM_ SG_ 1343 BMS_a107_MIA_numBadReadings "High-voltage battery management system: a107 MIA num bad readings";
CM_ SG_ 1343 BMS_a107_MIA_numSnaReadings "High-voltage battery management system: a107 MIA num sna readings";
CM_ SG_ 1343 BMS_a109_muteMask "High-voltage battery management system: a109 mute mask";
CM_ SG_ 1343 BMS_a109_packInBleed "High-voltage battery management system: a109 pack in bleed";
CM_ SG_ 1343 BMS_a117_brickID "High-voltage battery management system: a117 brick ID";
CM_ SG_ 1343 BMS_a117_brickSoc2 "High-voltage battery management system: a117 brick soc2";
CM_ SG_ 1343 BMS_a117_dSocAlertThreshold "High-voltage battery management system: a117 d soc alert threshold";
CM_ SG_ 1343 BMS_a117_dSocAlpha "High-voltage battery management system: a117 d soc alpha";
CM_ SG_ 1343 BMS_a122_thermistorID "High-voltage battery management system: a122 thermistor ID";
CM_ SG_ 1343 BMS_a122_irrationalThermistorTem "High-voltage battery management system: a122 irrational thermistor temp";
CM_ SG_ 1343 BMS_a122_averageRawThermistorTem "High-voltage battery management system: a122 average raw thermistor temp";
CM_ SG_ 1343 BMS_a122_minRawThermistorTemp "High-voltage battery management system: a122 min raw thermistor temp";
CM_ SG_ 1343 BMS_a122_maxRawThermistorTemp "High-voltage battery management system: a122 max raw thermistor temp";
CM_ SG_ 1343 BMS_a122_numValidThermistors "High-voltage battery management system: a122 num valid thermistors";
CM_ SG_ 1343 BMS_a123_packPlus "High-voltage battery management system: a123 pack plus";
CM_ SG_ 1343 BMS_a123_isoR "High-voltage battery management system: a123 iso r";
CM_ SG_ 1343 BMS_a123_packMinus "High-voltage battery management system: a123 pack minus";
CM_ SG_ 1343 BMS_a129_brickID "High-voltage battery management system: a129 brick ID";
CM_ SG_ 1343 BMS_a129_deltaV "High-voltage battery management system: a129 delta v";
CM_ SG_ 1343 BMS_a129_retryCount "High-voltage battery management system: a129 retry count";
CM_ SG_ 1343 BMS_a131_brickID "High-voltage battery management system: a131 brick ID";
CM_ SG_ 1343 BMS_a131_deltaV "High-voltage battery management system: a131 delta v";
CM_ SG_ 1343 BMS_a131_retryCount "High-voltage battery management system: a131 retry count";
CM_ SG_ 1343 BMS_a132_multiVendorErrorMask "High-voltage battery management system: a132 multi vendor error mask";
CM_ SG_ 1343 BMS_a135_bmbDiagnosticsType "High-voltage battery management system: a135 bmb diagnostics type";
CM_ SG_ 1343 BMS_a135_bmbDeviceId "High-voltage battery management system: a135 bmb device id";
CM_ SG_ 1343 BMS_a135_readCVA "High-voltage battery management system: a135 read CVA";
CM_ SG_ 1343 BMS_a135_readCVB "High-voltage battery management system: a135 read CVB";
CM_ SG_ 1343 BMS_a135_readCVC "High-voltage battery management system: a135 read CVC";
CM_ SG_ 1343 BMS_a135_readCVD "High-voltage battery management system: a135 read CVD";
CM_ SG_ 1343 BMS_a135_readCVE "High-voltage battery management system: a135 read CVE";
CM_ SG_ 1343 BMS_a135_readCVF "High-voltage battery management system: a135 read CVF";
CM_ SG_ 1343 BMS_a135_readSNA "High-voltage battery management system: a135 read SNA";
CM_ SG_ 1343 BMS_a135_readSNB "High-voltage battery management system: a135 read SNB";
CM_ SG_ 1343 BMS_a135_readSNC "High-voltage battery management system: a135 read SNC";
CM_ SG_ 1343 BMS_a135_readSND "High-voltage battery management system: a135 read SND";
CM_ SG_ 1343 BMS_a135_readSNE "High-voltage battery management system: a135 read SNE";
CM_ SG_ 1343 BMS_a135_readSNF "High-voltage battery management system: a135 read SNF";
CM_ SG_ 1343 BMS_a135_readAUXA "High-voltage battery management system: a135 read AUXA";
CM_ SG_ 1343 BMS_a135_readAUXB "High-voltage battery management system: a135 read AUXB";
CM_ SG_ 1343 BMS_a135_readSTAT "High-voltage battery management system: a135 read STAT";
CM_ SG_ 1343 BMS_a136_maxBrickTID "High-voltage battery management system: a136 max brick TID";
CM_ SG_ 1343 BMS_a136_coolantInletT "High-voltage battery management system: a136 coolant inlet t";
CM_ SG_ 1343 BMS_a136_activeCoolingTarget "High-voltage battery management system: a136 active cooling target";
CM_ SG_ 1343 BMS_a136_maxBrickT "High-voltage battery management system: a136 max brick t";
CM_ SG_ 1343 BMS_a139_packVoltage "High-voltage battery management system: a139 pack voltage";
CM_ SG_ 1343 BMS_a139_dcLinkVoltage "High-voltage battery management system: a139 dc link voltage";
CM_ SG_ 1343 BMS_a140_bmbDeviceMask "High-voltage battery management system: a140 bmb device mask";
CM_ SG_ 1343 BMS_a140_faultType "High-voltage battery management system: a140 fault type";
CM_ SG_ 1343 BMS_a142_isolationResistance "High-voltage battery management system: a142 isolation resistance";
CM_ SG_ 1343 BMS_a142_mode "High-voltage battery management system: a142 mode";
CM_ SG_ 1343 BMS_a143_initialSoc "High-voltage battery management system: a143 initial soc";
CM_ SG_ 1343 BMS_a143_endingSoc "High-voltage battery management system: a143 ending soc";
CM_ SG_ 1343 BMS_a143_deltaAh "High-voltage battery management system: a143 delta ah";
CM_ SG_ 1343 BMS_a143_cacChangeBrickID "High-voltage battery management system: a143 cac change brick ID";
CM_ SG_ 1343 BMS_a143_cacUpdateError "High-voltage battery management system: a143 cac update error";
CM_ SG_ 1343 BMS_a144_HVP_major_version "High-voltage battery management system: a144 HVP major version";
CM_ SG_ 1343 BMS_a144_HVP_minor_version "High-voltage battery management system: a144 HVP minor version";
CM_ SG_ 1343 BMS_a144_BMS_minor_version "High-voltage battery management system: a144 BMS minor version";
CM_ SG_ 1343 BMS_a145_maxSocChange "High-voltage battery management system: a145 max soc change";
CM_ SG_ 1343 BMS_a145_maxSocChangeBrickID "High-voltage battery management system: a145 max soc change brick ID";
CM_ SG_ 1343 BMS_a145_numBricksChanged "High-voltage battery management system: a145 num bricks changed";
CM_ SG_ 1343 BMS_a145_brickChangeHystRatio "High-voltage battery management system: a145 brick change hyst ratio";
CM_ SG_ 1343 BMS_a146_maxBrickV "High-voltage battery management system: a146 max brick v";
CM_ SG_ 1343 BMS_a146_state "High-voltage battery management system: a146 state";
CM_ SG_ 1343 BMS_a146_packCurrent "High-voltage battery management system: a146 pack current";
CM_ SG_ 1343 BMS_a146_uvBrickVID "High-voltage battery management system: a146 uv brick VID";
CM_ SG_ 1343 BMS_a146_uvBrickV "High-voltage battery management system: a146 uv brick v";
CM_ SG_ 1343 BMS_a151_isoPositiveR "High-voltage battery management system: a151 iso positive r";
CM_ SG_ 1343 BMS_a151_isoNegativeR "High-voltage battery management system: a151 iso negative r";
CM_ SG_ 1343 BMS_a152_isoR "High-voltage battery management system: a152 iso r";
CM_ SG_ 1343 BMS_a152_mode "High-voltage battery management system: a152 mode";
CM_ SG_ 1343 BMS_a152_activeSideVNoR "High-voltage battery management system: a152 active side v no r";
CM_ SG_ 1343 BMS_a152_activeSideVWithR "High-voltage battery management system: a152 active side v with r";
CM_ SG_ 1343 BMS_a152_passiveSideVNoR "High-voltage battery management system: a152 passive side v no r";
CM_ SG_ 1343 BMS_a152_passiveSideVWithR "High-voltage battery management system: a152 passive side v with r";
CM_ SG_ 1343 BMS_a156_VrefSample "High-voltage battery management system: a156 vref sample";
CM_ SG_ 1343 BMS_a156_bmbDeviceId "High-voltage battery management system: a156 bmb device id";
CM_ SG_ 1343 BMS_a156_VrefStatus "High-voltage battery management system: a156 vref status";
CM_ SG_ 1343 BMS_a158_shuntCurrentMia "High-voltage battery management system: a158 shunt current mia";
CM_ SG_ 1343 BMS_a158_contactorStateMia "High-voltage battery management system: a158 contactor state mia";
CM_ SG_ 1343 BMS_a158_hvpFaultsMia "High-voltage battery management system: a158 hvp faults mia";
CM_ SG_ 1343 BMS_a162_dischargePower_W "High-voltage battery management system: a162 discharge power w";
CM_ SG_ 1343 BMS_a162_minSoc "High-voltage battery management system: a162 min soc";
CM_ SG_ 1343 BMS_a162_socThreshold "High-voltage battery management system: a162 soc threshold";
CM_ SG_ 1343 BMS_a164_regenPower "High-voltage battery management system: a164 regen power";
CM_ SG_ 1343 BMS_a165_packPositiveV "High-voltage battery management system: a165 pack positive v";
CM_ SG_ 1343 BMS_a165_packNegativeV "High-voltage battery management system: a165 pack negative v";
CM_ SG_ 1343 BMS_a165_dcLinkPositiveV "High-voltage battery management system: a165 dc link positive v";
CM_ SG_ 1343 BMS_a165_dcLinkNegativeV "High-voltage battery management system: a165 dc link negative v";
CM_ SG_ 1343 BMS_a166_packPositiveV "High-voltage battery management system: a166 pack positive v";
CM_ SG_ 1343 BMS_a166_packNegativeV "High-voltage battery management system: a166 pack negative v";
CM_ SG_ 1343 BMS_a166_dcLinkPositiveV "High-voltage battery management system: a166 dc link positive v";
CM_ SG_ 1343 BMS_a166_dcLinkNegativeV "High-voltage battery management system: a166 dc link negative v";
CM_ SG_ 1343 BMS_a167_fcContPositiveAuxOpen "High-voltage battery management system: a167 fc cont positive aux open";
CM_ SG_ 1343 BMS_a167_fcContNegativeAuxOpen "High-voltage battery management system: a167 fc cont negative aux open";
CM_ SG_ 1343 BMS_a167_dcLinkPositiveV "High-voltage battery management system: a167 dc link positive v";
CM_ SG_ 1343 BMS_a167_dcLinkNegativeV "High-voltage battery management system: a167 dc link negative v";
CM_ SG_ 1343 BMS_a167_fcLinkPositiveV "High-voltage battery management system: a167 fc link positive v";
CM_ SG_ 1343 BMS_a167_fcLinkNegativeV "High-voltage battery management system: a167 fc link negative v";
CM_ SG_ 1343 BMS_a168_fcContPositiveAuxOpen "High-voltage battery management system: a168 fc cont positive aux open";
CM_ SG_ 1343 BMS_a168_fcContNegativeAuxOpen "High-voltage battery management system: a168 fc cont negative aux open";
CM_ SG_ 1343 BMS_a168_dcLinkPositiveV "High-voltage battery management system: a168 dc link positive v";
CM_ SG_ 1343 BMS_a168_dcLinkNegativeV "High-voltage battery management system: a168 dc link negative v";
CM_ SG_ 1343 BMS_a168_fcLinkPositiveV "High-voltage battery management system: a168 fc link positive v";
CM_ SG_ 1343 BMS_a168_fcLinkNegativeV "High-voltage battery management system: a168 fc link negative v";
CM_ SG_ 1343 BMS_a169_DCAndFCContactorsWelded "High-voltage battery management system: a169 DC and FC contactors welded";
CM_ SG_ 1343 BMS_a170_limpModeActive "High-voltage battery management system: a170 limp mode active";
CM_ SG_ 1343 BMS_a171_stackVoltage "High-voltage battery management system: a171 stack voltage";
CM_ SG_ 1343 BMS_a171_sumBrickVoltage "High-voltage battery management system: a171 sum brick voltage";
CM_ SG_ 1343 BMS_a171_stackId "High-voltage battery management system: a171 stack id";
CM_ SG_ 1343 BMS_a172_swIsolationCount "High-voltage battery management system: a172 sw isolation count";
CM_ SG_ 1343 BMS_a172_swIsoDegradationCount "High-voltage battery management system: a172 sw iso degradation count";
CM_ SG_ 1343 BMS_a177_energyAlertThreshold "High-voltage battery management system: a177 energy alert threshold";
CM_ SG_ 1343 BMS_a177_energyBuffer "High-voltage battery management system: a177 energy buffer";
CM_ SG_ 1343 BMS_a178_diPower "High-voltage battery management system: a178 di power";
CM_ SG_ 1343 BMS_a178_energyError "High-voltage battery management system: a178 energy error";
CM_ SG_ 1343 BMS_a178_powerError "High-voltage battery management system: a178 power error";
CM_ SG_ 1343 BMS_a178_minPowerError "High-voltage battery management system: a178 min power error";
CM_ SG_ 1343 BMS_a178_maxPowerError "High-voltage battery management system: a178 max power error";
CM_ SG_ 1343 BMS_a178_diMiaCount "High-voltage battery management system: a178 di mia count";
CM_ SG_ 1343 BMS_a178_diSnaCount "High-voltage battery management system: a178 di sna count";
CM_ BO_ 800 "High-voltage battery management system message: alert matrix";
CM_ SG_ 800 BMS_matrixIndex "High-voltage battery management system: matrix index";
CM_ SG_ 800 BMS_a001_Pack_Config_Mismatch "High-voltage battery management system: a001 pack config mismatch";
CM_ SG_ 800 BMS_a002_Pack_Performance_Config "High-voltage battery management system: a002 pack performance config mismatch";
CM_ SG_ 800 BMS_a003_SW_Pack_Birth_Date_Miss "High-voltage battery management system: a003 SW pack birth date missing";
CM_ SG_ 800 BMS_a004_Cal_Vs_Serial_Birth_Dat "High-voltage battery management system: a004 cal vs serial birth date mismatch";
CM_ SG_ 800 BMS_a007_SW_Slowed_Chg_Batt_Cold "High-voltage battery management system: a007 SW slowed chg batt cold";
CM_ SG_ 800 BMS_a016_Pack_Module_Id_Mismatch "High-voltage battery management system: a016 pack module id mismatch";
CM_ SG_ 800 BMS_a017_SW_Brick_OV "High-voltage battery management system: a017 SW brick OV";
CM_ SG_ 800 BMS_a018_SW_Brick_UV "High-voltage battery management system: a018 SW brick UV";
CM_ SG_ 800 BMS_a019_SW_Module_OT "High-voltage battery management system: a019 SW module OT";
CM_ SG_ 800 BMS_a020_SW_Brick_Instability "High-voltage battery management system: a020 SW brick instability";
CM_ SG_ 800 BMS_a021_SW_Dr_Limits_Regulation "High-voltage battery management system: a021 SW dr limits regulation";
CM_ SG_ 800 BMS_a022_SW_Over_Current "High-voltage battery management system: a022 SW over current";
CM_ SG_ 800 BMS_a023_SW_Stack_OV "High-voltage battery management system: a023 SW stack OV";
CM_ SG_ 800 BMS_a024_SW_Islanded_Brick "High-voltage battery management system: a024 SW islanded brick";
CM_ SG_ 800 BMS_a025_SW_PwrBalance_Anomaly "High-voltage battery management system: a025 SW pwr balance anomaly";
CM_ SG_ 800 BMS_a026_SW_HFCurrent_Anomaly "High-voltage battery management system: a026 SW HF current anomaly";
CM_ SG_ 800 BMS_a027_SW_Repeated_Isolation_F "High-voltage battery management system: a027 SW repeated isolation failure in drive";
CM_ SG_ 800 BMS_a028_ShuntAsicCurrentOffsetD "High-voltage battery management system: a028 shunt asic current offset deviation";
CM_ SG_ 800 BMS_a029_dSoc_Limiting "High-voltage battery management system: a029 d soc limiting";
CM_ SG_ 800 BMS_a030_Impedance_Deviation "High-voltage battery management system: a030 impedance deviation";
CM_ SG_ 800 BMS_a031_AlertsSetDuringSleep "High-voltage battery management system: a031 alerts set during sleep";
CM_ SG_ 800 BMS_a032_VoltageLoss "High-voltage battery management system: a032 voltage loss";
CM_ SG_ 800 BMS_a033_VoltageDeviation "High-voltage battery management system: a033 voltage deviation";
CM_ SG_ 800 BMS_a034_SW_Passive_Isolation "High-voltage battery management system: a034 SW passive isolation";
CM_ SG_ 800 BMS_a035_SW_Isolation "High-voltage battery management system: a035 SW isolation";
CM_ SG_ 800 BMS_a036_SW_HvpHvilFault "High-voltage battery management system: a036 SW hvp hvil fault";
CM_ SG_ 800 BMS_a037_SW_Flood_Port_Open "High-voltage battery management system: a037 SW flood port open";
CM_ SG_ 800 BMS_a039_SW_DC_Link_Over_Voltage "High-voltage battery management system: a039 SW DC link over voltage";
CM_ SG_ 800 BMS_a040_SW_Watch_Dog_HW_Trigger "High-voltage battery management system: a040 SW watch dog HW triggered";
CM_ SG_ 800 BMS_a041_SW_Destructive_Reset_So "High-voltage battery management system: a041 SW destructive reset source";
CM_ SG_ 800 BMS_a042_SW_MPU_Error "High-voltage battery management system: a042 SW MPU error";
CM_ SG_ 800 BMS_a043_SW_Watch_Dog_Reset "High-voltage battery management system: a043 SW watch dog reset";
CM_ SG_ 800 BMS_a044_SW_Assertion "High-voltage battery management system: a044 SW assertion";
CM_ SG_ 800 BMS_a045_SW_Exception "High-voltage battery management system: a045 SW exception";
CM_ SG_ 800 BMS_a046_SW_Task_Stack_Usage "High-voltage battery management system: a046 SW task stack usage";
CM_ SG_ 800 BMS_a047_SW_Task_Stack_Overflow "High-voltage battery management system: a047 SW task stack overflow";
CM_ SG_ 800 BMS_a048_SW_Watch_Dog_Warning "High-voltage battery management system: a048 SW watch dog warning";
CM_ SG_ 800 BMS_a049_SW_Thermal_Event "High-voltage battery management system: a049 SW thermal event";
CM_ SG_ 800 BMS_a050_SW_Brick_Voltage_MIA "High-voltage battery management system: a050 SW brick voltage MIA";
CM_ SG_ 800 BMS_a051_SW_HVC_Vref_Bad "High-voltage battery management system: a051 SW HVC vref bad";
CM_ SG_ 800 BMS_a052_SW_PCS_MIA "High-voltage battery management system: a052 SW PCS MIA";
CM_ SG_ 800 BMS_a054_SW_Ver_Supply_Fault "High-voltage battery management system: a054 SW ver supply fault";
CM_ SG_ 800 BMS_a055_SW_HvChain_Model_Fault "High-voltage battery management system: a055 SW hv chain model fault";
CM_ SG_ 800 BMS_a056_SW_Standby_Supply_Fault "High-voltage battery management system: a056 SW standby supply fault";
CM_ SG_ 800 BMS_a057_SW_Bandolier_Model_Warn "High-voltage battery management system: a057 SW bandolier model warning";
CM_ SG_ 800 BMS_a058_SW_Bandolier_Model_Rese "High-voltage battery management system: a058 SW bandolier model reset";
CM_ SG_ 800 BMS_a059_SW_Pack_Voltage_Sensing "High-voltage battery management system: a059 SW pack voltage sensing";
CM_ SG_ 800 BMS_a060_SW_Leakage_Test_Failure "High-voltage battery management system: a060 SW leakage test failure";
CM_ SG_ 800 BMS_a061_SW_BrickV_Change "High-voltage battery management system: a061 SW brick v change";
CM_ SG_ 800 BMS_a062_SW_BrickV_Imbalance "High-voltage battery management system: a062 SW brick v imbalance";
CM_ SG_ 800 BMS_a063_SW_ChargePort_Fault "High-voltage battery management system: a063 SW charge port fault";
CM_ SG_ 800 BMS_a064_SW_SOC_Imbalance "High-voltage battery management system: a064 SW SOC imbalance";
CM_ SG_ 800 BMS_a065_SW_CAC_Imbalance "High-voltage battery management system: a065 SW CAC imbalance";
CM_ SG_ 800 BMS_a066_SOC_Imbalance_Warning "High-voltage battery management system: a066 SOC imbalance warning";
CM_ SG_ 800 BMS_a067_CAC_Imbalance_Limiting "High-voltage battery management system: a067 CAC imbalance limiting";
CM_ SG_ 800 BMS_a068_CAC_Imbalance_Limp "High-voltage battery management system: a068 CAC imbalance limp";
CM_ SG_ 800 BMS_a069_SW_Low_Power "High-voltage battery management system: a069 SW low power";
CM_ SG_ 800 BMS_a070_BrickV_Imbalance_Limiti "High-voltage battery management system: a070 brick v imbalance limiting";
CM_ SG_ 800 BMS_a071_SW_SM_TransCon_Not_Met "High-voltage battery management system: a071 SW SM trans con not met";
CM_ SG_ 800 BMS_a072_Module_Brick_Split "High-voltage battery management system: a072 module brick split";
CM_ SG_ 800 BMS_a073_Unexpected_Loss_Of_Lv "High-voltage battery management system: a073 unexpected loss of lv";
CM_ SG_ 800 BMS_a074_Max_Charge_Level_Reduce "High-voltage battery management system: a074 max charge level reduced";
CM_ SG_ 800 BMS_a075_SW_Chg_Disable_Failure "High-voltage battery management system: a075 SW chg disable failure";
CM_ SG_ 800 BMS_a076_SW_Dch_While_Charging "High-voltage battery management system: a076 SW dch while charging";
CM_ SG_ 800 BMS_a077_SW_Charger_Regulation "High-voltage battery management system: a077 SW charger regulation";
CM_ SG_ 800 BMS_a078_Rapid_Dch_While_Chargin "High-voltage battery management system: a078 rapid dch while charging";
CM_ SG_ 800 BMS_a079_Max_Charge_Level_Exceed "High-voltage battery management system: a079 max charge level exceeded";
CM_ SG_ 800 BMS_a080_SW_Pack_Ctr_Impedance "High-voltage battery management system: a080 SW pack ctr impedance";
CM_ SG_ 800 BMS_a081_SW_Ctr_Close_Blocked "High-voltage battery management system: a081 SW ctr close blocked";
CM_ SG_ 800 BMS_a082_SW_Ctr_Force_Open "High-voltage battery management system: a082 SW ctr force open";
CM_ SG_ 800 BMS_a083_SW_Ctr_Close_Failure "High-voltage battery management system: a083 SW ctr close failure";
CM_ SG_ 800 BMS_a084_SW_Sleep_Wake_Aborted "High-voltage battery management system: a084 SW sleep wake aborted";
CM_ SG_ 800 BMS_a085_SW_Pack_Contactor_Misma "High-voltage battery management system: a085 SW pack contactor mismatch";
CM_ SG_ 800 BMS_a086_SW_FC_Contactor_Mismatc "High-voltage battery management system: a086 SW FC contactor mismatch";
CM_ SG_ 800 BMS_a087_SW_Feim_Test_Blocked "High-voltage battery management system: a087 SW feim test blocked";
CM_ SG_ 800 BMS_a088_SW_VcFront_MIA_InDrive "High-voltage battery management system: a088 SW vc front MIA in drive";
CM_ SG_ 800 BMS_a089_SW_VcFront_MIA "High-voltage battery management system: a089 SW vc front MIA";
CM_ SG_ 800 BMS_a090_SW_Gateway_MIA "High-voltage battery management system: a090 SW gateway MIA";
CM_ SG_ 800 BMS_a091_SW_ChargePort_MIA "High-voltage battery management system: a091 SW charge port MIA";
CM_ SG_ 800 BMS_a092_SW_ChargePort_Mia_On_Hv "High-voltage battery management system: a092 SW charge port mia on hvs";
CM_ SG_ 800 BMS_a094_SW_Drive_Inverter_MIA "High-voltage battery management system: a094 SW drive inverter MIA";
CM_ SG_ 800 BMS_a095_SW_UI_MIA "High-voltage battery management system: a095 SW UI MIA";
CM_ SG_ 800 BMS_a097_SW_BMB_Over_CAN_Communi "High-voltage battery management system: a097 SW BMB over CAN communication";
CM_ SG_ 800 BMS_a098_SW_BMB_Data_Integrity_L "High-voltage battery management system: a098 SW BMB data integrity loss";
CM_ SG_ 800 BMS_a099_SW_BMB_Communication "High-voltage battery management system: a099 SW BMB communication";
CM_ SG_ 800 BMS_a100_ThermalEventSuspected "High-voltage battery management system: a100 thermal event suspected";
CM_ SG_ 800 BMS_a105_SW_One_Module_Tsense "High-voltage battery management system: a105 SW one module tsense";
CM_ SG_ 800 BMS_a106_SW_All_Module_Tsense "High-voltage battery management system: a106 SW all module tsense";
CM_ SG_ 800 BMS_a107_SW_Stack_Voltage_MIA "High-voltage battery management system: a107 SW stack voltage MIA";
CM_ SG_ 800 BMS_a108_SW_BMB_Device_OT "High-voltage battery management system: a108 SW BMB device OT";
CM_ SG_ 800 BMS_a109_HW_BMB_Mute_Status_Mism "High-voltage battery management system: a109 HW BMB mute status mismatch";
CM_ SG_ 800 BMS_a110_LifeModel_AvgOffset_Cha "High-voltage battery management system: a110 life model avg offset change";
CM_ SG_ 800 BMS_a111_LifeModel_Spread_Change "High-voltage battery management system: a111 life model spread change";
CM_ SG_ 800 BMS_a112_LifeModel_Discontinuity "High-voltage battery management system: a112 life model discontinuity";
CM_ SG_ 800 BMS_a115_Energy_Rubberbanding_Re "High-voltage battery management system: a115 energy rubberbanding reset";
CM_ SG_ 800 BMS_a117_SW_Delta_SOC_Weak_Short "High-voltage battery management system: a117 SW delta SOC weak short";
CM_ SG_ 800 BMS_a119_Fast_Open_Vsh_Detected "High-voltage battery management system: a119 fast open vsh detected";
CM_ SG_ 800 BMS_a121_SW_NVRAM_Config_Error "High-voltage battery management system: a121 SW NVRAM config error";
CM_ SG_ 800 BMS_a122_SW_BMS_Therm_Irrational "High-voltage battery management system: a122 SW BMS therm irrational";
CM_ SG_ 800 BMS_a123_SW_Internal_Isolation "High-voltage battery management system: a123 SW internal isolation";
CM_ SG_ 800 BMS_a124_Battery_Coolant_Flood "High-voltage battery management system: a124 battery coolant flood";
CM_ SG_ 800 BMS_a126_SW_Thermistor_Failure "High-voltage battery management system: a126 SW thermistor failure";
CM_ SG_ 800 BMS_a127_SW_shunt_SNA "High-voltage battery management system: a127 SW shunt SNA";
CM_ SG_ 800 BMS_a128_SW_shunt_MIA "High-voltage battery management system: a128 SW shunt MIA";
CM_ SG_ 800 BMS_a129_SW_VSH_Failure "High-voltage battery management system: a129 SW VSH failure";
CM_ SG_ 800 BMS_a130_IO_CAN_Error "High-voltage battery management system: a130 IO CAN error";
CM_ SG_ 800 BMS_a131_Bleed_FET_Failure "High-voltage battery management system: a131 bleed FET failure";
CM_ SG_ 800 BMS_a132_HW_BMB_OTP_Uncorrctbl "High-voltage battery management system: a132 HW BMB OTP uncorrctbl";
CM_ SG_ 800 BMS_a133_IO_CAN_Bus_Off "High-voltage battery management system: a133 IO CAN bus off";
CM_ SG_ 800 BMS_a134_SW_Delayed_Ctr_Off "High-voltage battery management system: a134 SW delayed ctr off";
CM_ SG_ 800 BMS_a135_HW_BMB_Diagnostics_Fail "High-voltage battery management system: a135 HW BMB diagnostics failure";
CM_ SG_ 800 BMS_a136_SW_Module_OT_Warning "High-voltage battery management system: a136 SW module OT warning";
CM_ SG_ 800 BMS_a137_SW_Brick_UV_Warning "High-voltage battery management system: a137 SW brick UV warning";
CM_ SG_ 800 BMS_a138_SW_Brick_OV_Warning "High-voltage battery management system: a138 SW brick OV warning";
CM_ SG_ 800 BMS_a139_SW_DC_Link_V_Irrational "High-voltage battery management system: a139 SW DC link v irrational";
CM_ SG_ 800 BMS_a140_HW_BMB_Status_Fault "High-voltage battery management system: a140 HW BMB status fault";
CM_ SG_ 800 BMS_a141_SW_BMB_Status_Warning "High-voltage battery management system: a141 SW BMB status warning";
CM_ SG_ 800 BMS_a142_SW_Isolation_Degradatio "High-voltage battery management system: a142 SW isolation degradation";
CM_ SG_ 800 BMS_a143_SW_CAC_Change "High-voltage battery management system: a143 SW CAC change";
CM_ SG_ 800 BMS_a144_Hvp_Config_Mismatch "High-voltage battery management system: a144 hvp config mismatch";
CM_ SG_ 800 BMS_a145_SW_SOC_Change "High-voltage battery management system: a145 SW SOC change";
CM_ SG_ 800 BMS_a146_SW_Brick_Overdischarged "High-voltage battery management system: a146 SW brick overdischarged";
CM_ SG_ 800 BMS_a147_SW_SOC_High_Ah_Error "High-voltage battery management system: a147 SW SOC high ah error";
CM_ SG_ 800 BMS_a148_SW_Unsupported_BMB_ASIC "High-voltage battery management system: a148 SW unsupported BMB ASIC type";
CM_ SG_ 800 BMS_a149_SW_Missing_Config_Block "High-voltage battery management system: a149 SW missing config block";
CM_ SG_ 800 BMS_a150_SW_Missing_Part_Number "High-voltage battery management system: a150 SW missing part number";
CM_ SG_ 800 BMS_a151_SW_external_isolation "High-voltage battery management system: a151 SW external isolation";
CM_ SG_ 800 BMS_a152_Isolation_In_Dc_Charge "High-voltage battery management system: a152 isolation in dc charge";
CM_ SG_ 800 BMS_a154_SW_Brick_OV_Warning_Sto "High-voltage battery management system: a154 SW brick OV warning stop charge";
CM_ SG_ 800 BMS_a155_SW_Weak_short_impedence "High-voltage battery management system: a155 SW weak short impedence";
CM_ SG_ 800 BMS_a156_SW_BMB_Vref_bad "High-voltage battery management system: a156 SW BMB vref bad";
CM_ SG_ 800 BMS_a157_SW_Hist_Update_Missed "High-voltage battery management system: a157 SW hist update missed";
CM_ SG_ 800 BMS_a158_SW_HVP_HVI_Comms "High-voltage battery management system: a158 SW HVP HVI comms";
CM_ SG_ 800 BMS_a159_SW_HVP_ECU_Error "High-voltage battery management system: a159 SW HVP ECU error";
CM_ SG_ 800 BMS_a160_SW_FC_Ctr_Clean_Failed "High-voltage battery management system: a160 SW FC ctr clean failed";
CM_ SG_ 800 BMS_a161_SW_BMB_Vref_warning "High-voltage battery management system: a161 SW BMB vref warning";
CM_ SG_ 800 BMS_a162_SW_No_Power_For_Support "High-voltage battery management system: a162 SW no power for support";
CM_ SG_ 800 BMS_a164_SW_Uncontrolled_Regen "High-voltage battery management system: a164 SW uncontrolled regen";
CM_ SG_ 800 BMS_a165_SW_Pack_Partial_Weld "High-voltage battery management system: a165 SW pack partial weld";
CM_ SG_ 800 BMS_a166_SW_Pack_Full_Weld "High-voltage battery management system: a166 SW pack full weld";
CM_ SG_ 800 BMS_a167_SW_FC_Partial_Weld "High-voltage battery management system: a167 SW FC partial weld";
CM_ SG_ 800 BMS_a168_SW_FC_Full_Weld "High-voltage battery management system: a168 SW FC full weld";
CM_ SG_ 800 BMS_a169_SW_FC_Pack_Weld "High-voltage battery management system: a169 SW FC pack weld";
CM_ SG_ 800 BMS_a170_SW_Limp_Mode "High-voltage battery management system: a170 SW limp mode";
CM_ SG_ 800 BMS_a171_SW_Stack_Voltage_Sense "High-voltage battery management system: a171 SW stack voltage sense";
CM_ SG_ 800 BMS_a172_SW_Isolation_Failure_In "High-voltage battery management system: a172 SW isolation failure in drive warning";
CM_ SG_ 800 BMS_a174_SW_Charge_Failure "High-voltage battery management system: a174 SW charge failure";
CM_ SG_ 800 BMS_a175_Charge_Failure_External "High-voltage battery management system: a175 charge failure external";
CM_ SG_ 800 BMS_a176_SW_GracefulPowerOff "High-voltage battery management system: a176 SW graceful power off";
CM_ SG_ 800 BMS_a177_SW_Energy_Buffer_Size "High-voltage battery management system: a177 SW energy buffer size";
CM_ SG_ 800 BMS_a178_SW_Uncontrolled_Regen_P "High-voltage battery management system: a178 SW uncontrolled regen pwr b";
CM_ SG_ 800 BMS_a179_HvpGpoRequestActive "High-voltage battery management system: a179 hvp gpo request active";
CM_ SG_ 800 BMS_a180_SW_ECU_reset_blocked "High-voltage battery management system: a180 SW ECU reset blocked";
CM_ SG_ 800 BMS_a181_SW_Shunt_Over_Temperatu "High-voltage battery management system: a181 SW shunt over temperature";
CM_ SG_ 800 BMS_a182_LifeModel_NoCurrentLoss "High-voltage battery management system: a182 life model no current loss change";
CM_ SG_ 800 BMS_a183_LifeModel_StoDcrGrowth_ "High-voltage battery management system: a183 life model sto dcr growth change";
CM_ SG_ 800 BMS_a184_LifeModel_CyclingLoss_C "High-voltage battery management system: a184 life model cycling loss change";
CM_ SG_ 800 BMS_a185_LifeModel_CyclingDcrGro "High-voltage battery management system: a185 life model cycling dcr growth change";
CM_ SG_ 800 BMS_a186_RippleHeatingChargeFaul "High-voltage battery management system: a186 ripple heating charge fault";
CM_ SG_ 800 BMS_a187_RippleHeatingEmergencyS "High-voltage battery management system: a187 ripple heating emergency shutdown";
CM_ SG_ 800 BMS_a188_DtcConfirmed "High-voltage battery management system: a188 dtc confirmed";
CM_ BO_ 818 "High-voltage battery management system message: bmb min max";
CM_ SG_ 818 BMS_bmbMinMaxMultiplexer "High-voltage battery management system: bmb min max multiplexer";
CM_ SG_ 818 BMS_thermistorNumTMin "BMB module number with minimum temperature.";
CM_ SG_ 818 BMS_thermistorNumTMax "BMB module number with maximum temperature.";
CM_ SG_ 818 BMS_thermistorTMax "Max temperature of all valid filtered thermistors";
CM_ SG_ 818 BMS_thermistorTMin "Min temperature of all valid filtered thermistors";
CM_ SG_ 818 BMS_thermistorTAvg "Average temperature of all valid filtered thermistors";
CM_ SG_ 818 BMS_brickVoltageMax "Brick voltage maximum.";
CM_ SG_ 818 BMS_brickVoltageMin "Brick voltage minimum.";
CM_ SG_ 818 BMS_brickNumVoltageMax "Brick number with maximum voltage (1 indexed)";
CM_ SG_ 818 BMS_brickNumVoltageMin "Brick number with minimum voltage (1 indexed)";
CM_ BO_ 1138 "High-voltage battery management system message: charge info";
CM_ SG_ 1138 BMS_cellChargeDcCurrentLimit "DC current target based on cell voltage & temp tables";
CM_ SG_ 1138 BMS_voltageRegCurrentTarget "DC current target based on voltage regulator";
CM_ SG_ 1138 BMS_vehicleChargeDcCurrentLimit "Charge current target after all aggregating all vehicle-side limits, exclude EVSE limits";
CM_ SG_ 1138 BMS_chargeCurrentLimitMode "BMS charging current limiting factor";
CM_ SG_ 1138 BMS_timeToFinishHeatForCharge "High-voltage battery management system: time to finish heat for charge";
CM_ SG_ 1138 BMS_diNodeModelTemp "High-voltage battery management system: di node model temp";
CM_ BO_ 2029 "High-voltage battery management system message: debug info 10 hz";
CM_ SG_ 2029 BMS_10HzDebug_Id "High-voltage battery management system: 10 hz debug id";
CM_ SG_ 2029 BMS_activeCoolCellTargetT "High-voltage battery management system: active cool cell target t";
CM_ SG_ 2029 BMS_passiveCoolCellTargetT "High-voltage battery management system: passive cool cell target t";
CM_ BO_ 722 "High-voltage battery management system message: drive limits";
CM_ SG_ 722 BMS_minBusVoltage "Calculated min bus voltage limit";
CM_ SG_ 722 BMS_maxBusVoltage "Calculated max bus voltage limit for the pack";
CM_ SG_ 722 BMS_maxChargeCurrent "Calculated max charge current limit for the pack";
CM_ SG_ 722 BMS_maxDischargeCurrent "Calculated max discharge current limit for the pack";
CM_ BO_ 690 "High-voltage battery management system message: energy status";
CM_ SG_ 690 BMS_energyStatusMultiplexer "High-voltage battery management system: energy status multiplexer";
CM_ SG_ 690 BMS_nominalFullPackEnergy "Full pack energy based on calculated pack energy from the full pack discharge energy walk";
CM_ SG_ 690 BMS_nominalEnergyRemaining "Nominal energy remaining based on calculated pack energy from the nominal discharge energy walk";
CM_ SG_ 690 BMS_idealEnergyRemaining "Ideal energy remaining based on calculated pack energy from ideal discharge energy walk";
CM_ SG_ 690 BMS_fullChargeComplete "Indicates BMS is fully charged";
CM_ SG_ 690 BMS_energyBuffer "Rough indication of confidence in the energy estimation";
CM_ SG_ 690 BMS_expectedEnergyRemaining "High-voltage battery management system: expected energy remaining";
CM_ SG_ 690 BMS_energyToChargeComplete "Calculated energy required to reach charge complete";
CM_ SG_ 690 BMS_energyRemainingDisplay "Rubber-banding energy remaining to be used for the UI facing miles remaining display";
CM_ SG_ 690 BMS_energyRemainingTDisplay "Rubber-banding energy remaining to be used for the UI facing miles remaining display";
CM_ SG_ 690 BMS_energyDisplayErrorBlendRate "Rubber-banding blend rate to be used to ensure consistency between the gauge display and UI energy algorithms";
CM_ SG_ 690 BMS_userFacingSoe "User facing state of energy";
CM_ BO_ 306 "High-voltage battery management system message: hv bus status";
CM_ SG_ 306 BMS_packVoltage "Measures voltage on the battery side of the High Voltage (HV) contactors.";
CM_ SG_ 306 BMS_packCurrent "Current measured at the HV contactors of the HV battery.";
CM_ SG_ 306 BMS_currentUnfiltered "Pack current with no filters applied";
CM_ SG_ 306 BMS_chgTimeToFull "Estimated time remaining until charge termination percent will be reached";
CM_ BO_ 768 "High-voltage battery management system message: info";
CM_ SG_ 768 BMS_infoIndex "High-voltage battery management system: info index";
CM_ SG_ 768 BMS_buildType "High-voltage battery management system: build type";
CM_ SG_ 768 BMS_buildConfigId "High-voltage battery management system: build config id";
CM_ SG_ 768 BMS_hardwareId "High-voltage battery management system: hardware id";
CM_ SG_ 768 BMS_componentId "High-voltage battery management system: component id";
CM_ SG_ 768 BMS_pcbaId "BMS' assigned PCBA ID";
CM_ SG_ 768 BMS_assemblyId "BMS' assigned assembly ID";
CM_ SG_ 768 BMS_usageId "BMS' assigned usage ID";
CM_ SG_ 768 BMS_subUsageId "BMS' assigned subusage ID";
CM_ SG_ 768 BMS_platformType "High-voltage battery management system: platform type";
CM_ SG_ 768 BMS_appCrc "High-voltage battery management system: app crc";
CM_ SG_ 768 BMS_appGitHash "High-voltage battery management system: app git hash";
CM_ SG_ 768 BMS_bootGitHash "High-voltage battery management system: boot git hash";
CM_ SG_ 768 BMS_bootUdsProtoVersion "High-voltage battery management system: boot uds proto version";
CM_ SG_ 768 BMS_bootCrc "High-voltage battery management system: boot crc";
CM_ BO_ 978 "High-voltage battery management system message: kwh counter";
CM_ SG_ 978 BMS_kwhDischargeTotal "Total energy-lost kWh count during discharging";
CM_ SG_ 978 BMS_kwhChargeTotal "Total energy-gained kWh count during charging";
CM_ BO_ 1010 "High-voltage battery management system message: kwh counters multiplexed";
CM_ SG_ 1010 BMS_kwhCounter_Id "High-voltage battery management system: kwh counter id";
CM_ SG_ 1010 BMS_acChargerKwhTotal "Total energy-gained kWh count during AC charge";
CM_ SG_ 1010 BMS_dcChargerKwhTotal "Total energy-gained kWh count during DC charging";
CM_ SG_ 1010 BMS_kwhRegenChargeTotal "Total energy-gained kWh count during charging with regen";
CM_ SG_ 1010 BMS_kwhDriveDischargeTotal "Total energy-lost kWh count during discharging while driving";
CM_ SG_ 1010 BMS_kwhDischargeTotalModule1 "Total energy-lost kWh count during discharging for module number (1 indexed)";
CM_ SG_ 1010 BMS_kwhChargeTotalModule1 "Total energy-gained kWh count for module number (1 indexed)";
CM_ SG_ 1010 BMS_kwhAcChargeTotalModule1 "Total energy-gained kWh count during AC charge for module number (1 indexed)";
CM_ SG_ 1010 BMS_kwhDcChargeTotalModule1 "Total energy-gained kWh count during DC charge for module number (1 indexed)";
CM_ SG_ 1010 BMS_kwhDischargeTotalModule2 "Total energy-lost kWh count during discharging for module number (1 indexed)";
CM_ SG_ 1010 BMS_kwhChargeTotalModule2 "Total energy-gained kWh count for module number (1 indexed)";
CM_ SG_ 1010 BMS_kwhAcChargeTotalModule2 "Total energy-gained kWh count during AC charge for module number (1 indexed)";
CM_ SG_ 1010 BMS_kwhDcChargeTotalModule2 "Total energy-gained kWh count during DC charge for module number (1 indexed)";
CM_ SG_ 1010 BMS_kwhDischargeTotalModule3 "Total energy-lost kWh count during discharging for module number (1 indexed)";
CM_ SG_ 1010 BMS_kwhChargeTotalModule3 "Total energy-gained kWh count for module number (1 indexed)";
CM_ SG_ 1010 BMS_kwhAcChargeTotalModule3 "Total energy-gained kWh count during AC charge for module number (1 indexed)";
CM_ SG_ 1010 BMS_kwhDcChargeTotalModule3 "Total energy-gained kWh count during DC charge for module number (1 indexed)";
CM_ SG_ 1010 BMS_kwhDischargeTotalModule4 "Total energy-lost kWh count during discharging for module number (1 indexed)";
CM_ SG_ 1010 BMS_kwhChargeTotalModule4 "Total energy-gained kWh count for module number (1 indexed)";
CM_ SG_ 1010 BMS_kwhAcChargeTotalModule4 "Total energy-gained kWh count during AC charge for module number (1 indexed)";
CM_ SG_ 1010 BMS_kwhDcChargeTotalModule4 "Total energy-gained kWh count during DC charge for module number (1 indexed)";
CM_ BO_ 884 "High-voltage battery management system message: log1";
CM_ SG_ 884 BMS_log1MuxId "High-voltage battery management system: log1 mux id";
CM_ SG_ 884 BMS_hvChargeStatus "High-voltage battery management system: hv charge status";
CM_ SG_ 884 BMS_extDcPrechargeVoltageLimit "High-voltage battery management system: ext dc precharge voltage limit";
CM_ SG_ 884 BMS_dcChargeCurrentRequest "The BMS's instantaneous DC charge current request to the EVSE";
CM_ SG_ 884 BMS_dcChargeCurrentLimit "The vehicle's charge current limit on a DC EVSE's output";
CM_ SG_ 884 BMS_dcDischargeEnabled "High-voltage battery management system: dc discharge enabled";
CM_ SG_ 884 BMS_rippleChargeRetryCount "High-voltage battery management system: ripple charge retry count";
CM_ SG_ 884 BMS_dcChargeVoltageLimit "The vehicle's charge voltage limit on a DC EVSE's output";
CM_ SG_ 884 BMS_dcChargePowerLimit "Max power limit for pack during DC charging";
CM_ SG_ 884 BMS_acChargePowerRequest "High-voltage battery management system: ac charge power request";
CM_ SG_ 884 BMS_maxExtIsoFcLinkV "The max voltage read on the FC link during the external isolation check";
CM_ SG_ 884 BMS_socByDeltaVEnabled "High-voltage battery management system: soc by delta v enabled";
CM_ SG_ 884 BMS_socByDvMaxSocLimit "High-voltage battery management system: soc by dv max soc limit";
CM_ SG_ 884 BMS_socByDvVoltageChangeOverAh "High-voltage battery management system: soc by dv voltage change over ah";
CM_ SG_ 884 BMS_socByDvMaxSocByAhCorrected "High-voltage battery management system: soc by dv max soc by ah corrected";
CM_ SG_ 884 BMS_socByDvMaxBrickVoltage "High-voltage battery management system: soc by dv max brick voltage";
CM_ SG_ 884 BMS_socByDvMaxBrickId "High-voltage battery management system: soc by dv max brick id";
CM_ BO_ 946 "High-voltage battery management system message: log2";
CM_ SG_ 946 BMS_log2MuxId "High-voltage battery management system: log2 mux id";
CM_ SG_ 946 BMS_cacAvg "BMS Calculated Ah Capacity (CAC). This is the average of all the brick CACs";
CM_ SG_ 946 BMS_cacMin "BMS Calculated Ah Capacity (CAC). This is the min of all the brick CACs";
CM_ SG_ 946 BMS_cacMinBrickId "High-voltage battery management system: cac min brick id";
CM_ SG_ 946 BMS_cacMax "BMS Calculated Ah Capacity (CAC). This is the max of all the brick CACs";
CM_ SG_ 946 BMS_cacMaxBrickId "High-voltage battery management system: cac max brick id";
CM_ SG_ 946 BMS_acRippleConfigNvramValid "High-voltage battery management system: ac ripple config nvram valid";
CM_ SG_ 946 BMS_hvChain_useLeakyBucket "Is the leaky bucket being used - an indicator of the HV Chain Model health";
CM_ SG_ 946 BMS_hvChain_iLimit "High-voltage battery management system: hv chain i limit";
CM_ SG_ 946 BMS_hvChain_limitingState "High-voltage battery management system: hv chain limiting state";
CM_ SG_ 946 BMS_hvChain_limitingStateTempera "High-voltage battery management system: hv chain limiting state temperature";
CM_ SG_ 946 BMS_acRippleIsSupported "High-voltage battery management system: ac ripple is supported";
CM_ SG_ 946 BMS_acRippleStartTemperatureMax "High-voltage battery management system: ac ripple start temperature max";
CM_ SG_ 946 BMS_acRippleStartTemperatureMin "High-voltage battery management system: ac ripple start temperature min";
CM_ SG_ 946 BMS_fcLinkTestDecayTime "High-voltage battery management system: fc link test decay time";
CM_ SG_ 946 BMS_fcLinkTestTimeSinceLastRun "High-voltage battery management system: fc link test time since last run";
CM_ SG_ 946 BMS_pcsPrechargeRequestActive "High-voltage battery management system: pcs precharge request active";
CM_ SG_ 946 BMS_pcsPrechargeTargetVoltage "Target voltage for precharging HV bus";
CM_ SG_ 946 BMS_recentOvUvAlert "At least one of the Brick OV or UV alerts has been active recently; consumed by BMS_a049_SW_Thermal_Event set condition";
CM_ SG_ 946 BMS_recentIsoAlert "At least one of the isolation alerts has been active recently; consumed by BMS_a049_SW_Thermal_Event set condition";
CM_ SG_ 946 BMS_recentBmbMiaAlert "At least one of the BMB communication alerts has been active recently; consumed by BMS_a049_SW_Thermal_Event set condition";
CM_ SG_ 946 BMS_cacBlendingConfigNvramValid "High-voltage battery management system: cac blending config nvram valid";
CM_ SG_ 946 BMS_cacBlendingEnabled "High-voltage battery management system: cac blending enabled";
CM_ SG_ 946 BMS_cacBlendPercentPerCycle "High-voltage battery management system: cac blend percent per cycle";
CM_ SG_ 946 BMS_energyVariableChgRequested "High-voltage battery management system: energy variable chg requested";
CM_ SG_ 946 BMS_packRestTime "Minimum resting time of all bricks";
CM_ SG_ 946 BMS_idealEnergyFloor "Ideal energy estimate based on the min bounded SOC that accounts for accumulated shunt error";
CM_ SG_ 946 BMS_thmGradientSlopeCondition "High-voltage battery management system: thm gradient slope condition";
CM_ SG_ 946 BMS_recentSlopeConditon "High-voltage battery management system: recent slope conditon";
CM_ SG_ 946 BMS_dynamicEnergyBuffer "BMS estimate of energy error based on SOC measurement inaccuracy";
CM_ SG_ 946 BMS_temperatureCondition "High-voltage battery management system: temperature condition";
CM_ SG_ 946 BMS_thmGradientSlope "High-voltage battery management system: thm gradient slope";
CM_ SG_ 946 BMS_thmGradient "High-voltage battery management system: thm gradient";
CM_ SG_ 946 BMS_dSocNormalizedMin "High-voltage battery management system: d soc normalized min";
CM_ SG_ 946 BMS_dSocNormalizedFiltMin "High-voltage battery management system: d soc normalized filt min";
CM_ SG_ 946 BMS_dSocMinAlpha "minimum calculated alpha value across all bricks and all dSOC calculations";
CM_ SG_ 946 BMS_dSocMaxLowAlphaCounter "High-voltage battery management system: d soc max low alpha counter";
CM_ SG_ 946 BMS_dSocMinAlphaBrickID "High-voltage battery management system: d soc min alpha brick ID";
CM_ SG_ 946 BMS_dSocCacMargin "High-voltage battery management system: d soc cac margin";
CM_ SG_ 946 BMS_lifeModelAvgTempSeverity "High-voltage battery management system: life model avg temp severity";
CM_ SG_ 946 BMS_lifeModelDepthOfDischargeSev "High-voltage battery management system: life model depth of discharge severity";
CM_ SG_ 946 BMS_lifeModelHistogramCapacityLo "High-voltage battery management system: life model histogram capacity loss";
CM_ SG_ 946 BMS_lifeModelHistogramBrickCapac "High-voltage battery management system: life model histogram brick capacity";
CM_ SG_ 946 BMS_lifeModelDcrGrowthPercent "High-voltage battery management system: life model dcr growth percent";
CM_ SG_ 946 BMS_nominalFullPackEnergyRaw "Non-latched version of BMS_nominalEnergyRemaining";
CM_ SG_ 946 BMS_userChargeCalibratingReason "High-voltage battery management system: user charge calibrating reason";
CM_ SG_ 946 BMS_nominalEnergyRemainingBuffer "Buffered version of BMS_nominalEnergyRemaining";
CM_ SG_ 946 BMS_idealEnergyRemainingBuffered "Buffered version of BMS_idealEnergyRemaining";
CM_ SG_ 946 BMS_largestCacSpreadErrorLower "High-voltage battery management system: largest cac spread error lower";
CM_ SG_ 946 BMS_lifeModelAverageCac "High-voltage battery management system: life model average cac";
CM_ SG_ 946 BMS_lifeModelCacBrick1 "High-voltage battery management system: life model cac brick1";
CM_ SG_ 946 BMS_lifeModelAverageOffset "High-voltage battery management system: life model average offset";
CM_ SG_ 946 BMS_percentCacUpdatesInTimeWindo "High-voltage battery management system: percent cac updates in time window";
CM_ SG_ 946 BMS_lifeModelMaxCacBrickId "High-voltage battery management system: life model max cac brick id";
CM_ SG_ 946 BMS_lifeModelMaxCac "High-voltage battery management system: life model max cac";
CM_ SG_ 946 BMS_lifeModelMinCacBrickId "High-voltage battery management system: life model min cac brick id";
CM_ SG_ 946 BMS_lifeModelMinCac "High-voltage battery management system: life model min cac";
CM_ SG_ 946 BMS_restingPointCacAvg "High-voltage battery management system: resting point cac avg";
CM_ SG_ 946 BMS_cacEstimationSource "High-voltage battery management system: cac estimation source";
CM_ SG_ 946 BMS_synchronizedCacMaxRaw "High-voltage battery management system: synchronized cac max raw";
CM_ SG_ 946 BMS_synchronizedCacMinRaw "High-voltage battery management system: synchronized cac min raw";
CM_ SG_ 946 BMS_largestSyncCacErrorStartSoc "Start SOC for CAC update from the brick with the highest synchronized CAC error";
CM_ SG_ 946 BMS_largestSyncCacErrorEndSoc "Start SOC for CAC update from the brick with the highest synchronized CAC error";
CM_ SG_ 946 BMS_runtimeSocConfigNvramValid "High-voltage battery management system: runtime soc config nvram valid";
CM_ SG_ 946 BMS_runtimeSocCorrectionsEnabled "High-voltage battery management system: runtime soc corrections enabled";
CM_ SG_ 946 BMS_rubberBandingEnabled "Reports whether rubber banding of output energy corrections is enabled.";
CM_ SG_ 946 BMS_rubberBandingConfigNvramVali "High-voltage battery management system: rubber banding config nvram valid";
CM_ SG_ 946 BMS_runtimeSocMinTempForModel "High-voltage battery management system: runtime soc min temp for model";
CM_ SG_ 946 BMS_energyBufferConfigNvramValid "High-voltage battery management system: energy buffer config nvram valid";
CM_ SG_ 946 BMS_thermalEvent1pDetectConfigDi "High-voltage battery management system: thermal event1p detect config disabled";
CM_ SG_ 946 BMS_sohEnergy "Battery SOH energy estimate. If calibrated SOH capacity is unavailable, this value is a filtered result from brick CACs.";
CM_ SG_ 946 BMS_fullCapacitySohEnergy "Energy estimate using nominal brick capacity at maximum SOC using SOH retention test conditions";
CM_ SG_ 946 BMS_calibratedCapacitySohEnergy "Energy estimate using CAC from the most recent valid SOH test at maximum SOC using SOH retention test conditions";
CM_ SG_ 946 BMS_estimatedCapacitySohEnergy "Energy estimate using filtered brick capacities at maximum SOC using SOH retention test conditions";
CM_ SG_ 946 BMS_prevUserFacingSohEnergy "The last soh energy stored in NVM for rate limiting purposes";
CM_ SG_ 946 BMS_stateOfHealthMinCac "Reports the minimum Calculated Amp-hour Capacity (CAC) by aged Open Circuit Voltage (OCV) raw values across bricks that could be used in State of Health (SOH) calculations.";
CM_ SG_ 946 BMS_lifeModelStorageLossPackAge "High-voltage battery management system: life model storage loss pack age";
CM_ SG_ 946 BMS_lifeModelThroughputCycleCoun "High-voltage battery management system: life model throughput cycle count";
CM_ SG_ 946 BMS_lifeModelThroughputDcrCycleC "High-voltage battery management system: life model throughput dcr cycle count";
CM_ SG_ 946 BMS_energyWalkCounter "High-voltage battery management system: energy walk counter";
CM_ SG_ 946 BMS_energyWalkTimeoutCounter "High-voltage battery management system: energy walk timeout counter";
CM_ SG_ 946 BMS_dynamicCcvEnabled "High-voltage battery management system: dynamic ccv enabled";
CM_ SG_ 946 BMS_chargeTargetLookupSoc "High-voltage battery management system: charge target lookup soc";
CM_ SG_ 946 BMS_stateOfHealth "Most recent battery capacity estimate, from a successful SOH test in %";
CM_ BO_ 914 "High-voltage battery management system message: pack config";
CM_ SG_ 914 BMS_packConfigMultiplexer "High-voltage battery management system: pack config multiplexer";
CM_ SG_ 914 BMS_reservedConfig_0 "High-voltage battery management system: reserved config 0";
CM_ SG_ 914 BMS_moduleType "High-voltage battery management system: module type";
CM_ SG_ 914 BMS_thermalPackType "High-voltage battery management system: thermal pack type";
CM_ SG_ 914 BMS_packMass "High-voltage battery management system: pack mass";
CM_ SG_ 914 BMS_platformMaxBusVoltage "High-voltage battery management system: platform max bus voltage";
CM_ SG_ 914 BMS_standbySupplyContinuousPower "High-voltage battery management system: standby supply continuous power limit";
CM_ BO_ 594 "High-voltage battery management system message: power available";
CM_ SG_ 594 BMS_maxRegenPower "Calculated max regen power";
CM_ SG_ 594 BMS_maxDischargePower "Calculated max discharge power possible based on max discharge current and sum of loaded voltages";
CM_ SG_ 594 BMS_maxStationaryHeatPower "Maximum heating power the DI can produce when in stationary heating mode";
CM_ SG_ 594 BMS_powerLimitsState "High-voltage battery management system: power limits state";
CM_ SG_ 594 BMS_notEnoughPowerForHeatPump "Flag indicating the min pack power is lower than specified threshold to support heating with the heat pump";
CM_ SG_ 594 BMS_instantChargePowerCapability "Indicates the instantaneous charge power capability of the high voltage battery.";
CM_ BO_ 674 "High-voltage battery management system message: ripple request";
CM_ SG_ 674 BMS_acRippleCurrentAmplitudeLimi "Transmits the Battery Management System (BMS) AC ripple current amplitude limit to the Electric Vehicle Supply Equipment (EVSE).";
CM_ SG_ 674 BMS_acRippleMaxVoltageLimit "Reports the maximum voltage limit when the Electric Vehicle Supply Equipment (EVSE) is performing the AC ripple.";
CM_ SG_ 674 BMS_acRippleMinVoltageLimit "Reports the minimum voltage limit when the Electric Vehicle Supply Equipment (EVSE) is performing the AC ripple.";
CM_ SG_ 674 BMS_acRippleFrequencyRequest "Transmits the Battery Management System (BMS) AC ripple frequency request to the Electric Vehicle Supply Equipment (EVSE).";
CM_ SG_ 674 BMS_acRippleCurrentAmplitudeRequ "Transmits the Battery Management System (BMS) AC ripple current amplitude request to the Electric Vehicle Supply Equipment (EVSE).";
CM_ SG_ 674 BMS_acRippleRequest "High-voltage battery management system: ac ripple request";
CM_ BO_ 658 "High-voltage battery management system message: soc status";
CM_ SG_ 658 BMS_socMin "BMS State Of Charge (SOC). This is the minimum brick SOC.";
CM_ SG_ 658 BMS_socUI "BMS State Of Energy (SOE) for the UI. This is ideal discharge energy from present state / ideal discharge energy from full.";
CM_ SG_ 658 BMS_socMax "BMS State Of Charge (SOC). This is the maximum brick SOC.";
CM_ SG_ 658 BMS_socAvg "BMS State Of Charge (SOC). This is the average of all the brick SOCs";
CM_ SG_ 658 BMS_beginningOfLifePackEnergy "High-voltage battery management system: beginning of life pack energy";
CM_ SG_ 658 BMS_battTempPct "High-voltage battery management system: batt temp pct";
CM_ SG_ 658 BMS_userChargeCurrentLimitMode "BMS' user-facing reason for charge being either limited or not limited";
CM_ BO_ 1170 "High-voltage battery management system message: state of health";
CM_ SG_ 1170 BMS_sohEnergyPercent "Estimate of battery SOH Energy % based on the most accurate capacity estimates the BMS has available";
CM_ SG_ 1170 BMS_userFacingSohTestState "High-voltage battery management system: user facing soh test state";
CM_ SG_ 1170 BMS_userFacingSohTestEndMode "High-voltage battery management system: user facing soh test end mode";
CM_ SG_ 1170 BMS_timeSinceSohUpdate "Days since last successful SOH test";
CM_ SG_ 1170 BMS_sohTestCycleFlag "Flag that is True from the start of an SOH test until it ends and all relevant signals have been logged";
CM_ SG_ 1170 BMS_sohTestIsBlocked "High-voltage battery management system: soh test is blocked";
CM_ SG_ 1170 BMS_calibratedSohAvailable "SOH Energy is based on valid results from the SOH capacity test";
CM_ SG_ 1170 BMS_requiredEvsePowerForSoh "High-voltage battery management system: required evse power for soh";
CM_ SG_ 1170 BMS_distanceSinceSohUpdate "Distance since the last State of Health update in km";
CM_ BO_ 530 "High-voltage battery management system message: status";
CM_ SG_ 530 BMS_hvacPowerRequest "High-voltage battery management system: hvac power request";
CM_ SG_ 530 BMS_notEnoughPowerForDrive "Flag indicating the min pack power is lower than specified threshold to support drive";
CM_ SG_ 530 BMS_notEnoughPowerForSupport "Flag indicating if the system can support a new request for 12V battery support";
CM_ SG_ 530 BMS_preconditionAllowed "High-voltage battery management system: precondition allowed";
CM_ SG_ 530 BMS_updateAllowed "High-voltage battery management system: update allowed";
CM_ SG_ 530 BMS_activeHeatingWorthwhile "Determination by the Battery Management System (BMS) if active heating is worthwhile";
CM_ SG_ 530 BMS_cpMiaOnHvs "Flag indicating that BMS is no longer receiving comms from CP on HVS bus";
CM_ SG_ 530 BMS_pcsPwmEnabled "Reports the state of the PCS_PWM_ENABLE input on the HVBMS, which is derived from the P1-12-DCDC-ENABLE input, which comes from VCFRONT";
CM_ SG_ 530 BMS_contactorState "BMS Contactor Status";
CM_ SG_ 530 BMS_userChargeStatus "BMS charge status for UI display. Renamed from BMS_uiChargeStatus";
CM_ SG_ 530 BMS_totalBatteryPower "High-voltage battery management system: total battery power";
CM_ SG_ 530 BMS_chargeRequest "Indicates charge is available and charge is desired";
CM_ SG_ 530 BMS_state "BMS operating state.";
CM_ SG_ 530 BMS_diLimpRequest "BMS request to DI to enter limp mode";
CM_ SG_ 530 BMS_okToShipByAir "High-voltage battery management system: ok to ship by air";
CM_ SG_ 530 BMS_okToShipByLand "High-voltage battery management system: ok to ship by land";
CM_ SG_ 530 BMS_chgPowerAvailable "BMS available charge power";
CM_ SG_ 530 BMS_chargeRetryCount "Number of retries remaining to enable charge";
CM_ SG_ 530 BMS_conditioningRequest "BMS request to enable conditioning so it can attempt FEIM recovery";
CM_ SG_ 530 BMS_smStateRequest "BMS high level state request";
CM_ SG_ 530 BMS_hvState "BMS high voltage state";
CM_ BO_ 786 "High-voltage battery management system message: thermal status";
CM_ SG_ 786 BMS_powerDissipation "High-voltage battery management system: power dissipation";
CM_ SG_ 786 BMS_flowRequest "Requested coolant flow rate in liters per minute (LPM) from the Battery Management System (BMS) to the thermal module";
CM_ SG_ 786 BMS_inletActiveCoolTargetT "Calculated active cooling temperature target at the inlet";
CM_ SG_ 786 BMS_inletPassiveTargetT "Calculated passive temperature target at the inlet";
CM_ SG_ 786 BMS_inletActiveHeatTargetT "Calculated active heating temperature target at the inlet";
CM_ SG_ 786 BMS_minPackTemperature "Minimum pack temperature for consumption by external entities";
CM_ SG_ 786 BMS_maxPackTemperature "Maximum pack temperature for consumption by external entities";
CM_ SG_ 786 BMS_pcsNoFlowRequest "High-voltage battery management system: pcs no flow request";
CM_ SG_ 786 BMS_noFlowRequest "High-voltage battery management system: no flow request";
CM_ BO_ 2028 "High-voltage battery management system message: thermal status2";
CM_ SG_ 2028 BMS_coldStagnationLimit "Minimum temperature at which the pack is allowed to be used as a heat-energy source";
CM_ SG_ 2028 BMS_hotStagnationLimit "Maximum temperature at which we allow the pack to be used for heat-energy storage";
CM_ SG_ 2028 BMS_hotCellTempLimit "Maximum temperature at which the pack will allow limp mode levels of current";
CM_ SG_ 2028 BMS_activeCoolCellReferenceT "Desired cell temperature reference which composes the temperature trajectory portion of the active cooling target temperature controls";
CM_ SG_ 2028 BMS_activeHeatCellTargetT "Desired cell temperature which feeds as an input to the active heating target temperature, before any additional controls calculations";
CM_ SG_ 2028 BMS_cellTempTargetMode "Operating mode of the thermal controls for the Battery Management System (BMS)";
CM_ SG_ 2028 BMS_requestDischarge "Flag identifying when the Battery Management System (BMS) is requesting the battery pack to be discharged";
CM_ BO_ 754 "High-voltage battery management system message: veh nm";
CM_ SG_ 754 BMS_nmGoingToSleep "High-voltage battery management system: nm going to sleep";
CM_ SG_ 754 BMS_nmWakeUpBus "High-voltage battery management system: nm wake up bus";
CM_ SG_ 754 BMS_hvsBusAsleep "HVS bus reported as off";
CM_ SG_ 754 BMS_nmKeepAwakeReason "BMS' determined reason to keep CAN awake";
CM_ SG_ 754 BMS_nmWakeUpReason "BMS' determined reason to wake up CAN";
CM_ BO_ 810 "High-voltage battery management system message: vehicle notifications";
CM_ SG_ 810 BMS_thermalEventSuspected "Indicates the Battery Management System (BMS) has detected conditions that reflect a possible battery thermal event";
CM_ SG_ 810 BMS_vehicleNotificationsCounter "High-voltage battery management system: vehicle notifications counter";
CM_ SG_ 810 BMS_isolationResistance "Resistance between HV bus and chassis.";
CM_ SG_ 810 BMS_vehicleNotificationsChecksum "High-voltage battery management system: vehicle notifications checksum";
CM_ BO_ 1116 "Charge cable controller message: alert log";
CM_ SG_ 1116 CC_alertID "Charge cable controller: alert ID";
CM_ SG_ 1116 CC_alertType "Charge cable controller: alert type";
CM_ SG_ 1116 CC_a001_groundResistance "Charge cable controller: a001 ground resistance";
CM_ SG_ 1116 CC_a003_gfciRmsCurrent "Charge cable controller: a003 gfci rms current";
CM_ SG_ 1116 CC_a003_gfciRmsCurrentAvg "Charge cable controller: a003 gfci rms current avg";
CM_ SG_ 1116 CC_a003_dcGfciCurrent "Charge cable controller: a003 dc gfci current";
CM_ SG_ 1116 CC_a003_gfciFaultReason "Charge cable controller: a003 gfci fault reason";
CM_ SG_ 1116 CC_a003_gfciFaultBucket "Charge cable controller: a003 gfci fault bucket";
CM_ SG_ 1116 CC_a004_gfciErrorReason "Charge cable controller: a004 gfci error reason";
CM_ SG_ 1116 CC_a004_gfciAsicErrorBitfield "Charge cable controller: a004 gfci asic error bitfield";
CM_ SG_ 1116 CC_a004_gfciSelfTestDuty "Charge cable controller: a004 gfci self test duty";
CM_ SG_ 1116 CC_a004_gfciSelfTestCurrent "Charge cable controller: a004 gfci self test current";
CM_ SG_ 1116 CC_a006_line1Current "Charge cable controller: a006 line1 current";
CM_ SG_ 1116 CC_a006_line2Current "Charge cable controller: a006 line2 current";
CM_ SG_ 1116 CC_a006_line3Current "Charge cable controller: a006 line3 current";
CM_ SG_ 1116 CC_a007_inputVoltage "Charge cable controller: a007 input voltage";
CM_ SG_ 1116 CC_a007_inputLineVoltage "Charge cable controller: a007 input line voltage";
CM_ SG_ 1116 CC_a007_inputNeutralVoltage "Charge cable controller: a007 input neutral voltage";
CM_ SG_ 1116 CC_a008_inputVoltage "Charge cable controller: a008 input voltage";
CM_ SG_ 1116 CC_a008_inputLineVoltage "Charge cable controller: a008 input line voltage";
CM_ SG_ 1116 CC_a008_inputNeutralVoltage "Charge cable controller: a008 input neutral voltage";
CM_ SG_ 1116 CC_a010_line1Voltage "Charge cable controller: a010 line1 voltage";
CM_ SG_ 1116 CC_a010_line2Voltage "Charge cable controller: a010 line2 voltage";
CM_ SG_ 1116 CC_a010_line3Voltage "Charge cable controller: a010 line3 voltage";
CM_ SG_ 1116 CC_a010_line1StuckClosed "Charge cable controller: a010 line1 stuck closed";
CM_ SG_ 1116 CC_a010_line2StuckClosed "Charge cable controller: a010 line2 stuck closed";
CM_ SG_ 1116 CC_a010_line3StuckClosed "Charge cable controller: a010 line3 stuck closed";
CM_ SG_ 1116 CC_a011_pcbaTemp "Charge cable controller: a011 pcba temp";
CM_ SG_ 1116 CC_a012_inputThermopile "Charge cable controller: a012 input thermopile";
CM_ SG_ 1116 CC_a012_inputThermopileDvdt "Charge cable controller: a012 input thermopile dvdt";
CM_ SG_ 1116 CC_a013_handleTemp "Charge cable controller: a013 handle temp";
CM_ SG_ 1116 CC_a014_failureCause "Charge cable controller: a014 failure cause";
CM_ SG_ 1116 CC_a014_meterFaultAddress "Charge cable controller: a014 meter fault address";
CM_ SG_ 1116 CC_a014_meterFaultData "Charge cable controller: a014 meter fault data";
CM_ SG_ 1116 CC_a014_meterRetryCount "Charge cable controller: a014 meter retry count";
CM_ SG_ 1116 CC_a015_pilotHighVolage "Charge cable controller: a015 pilot high volage";
CM_ SG_ 1116 CC_a015_smState "Charge cable controller: a015 sm state";
CM_ SG_ 1116 CC_a027_handleTemperature "Charge cable controller: a027 handle temperature";
CM_ SG_ 1116 CC_a027_handleTempFaultReason "Charge cable controller: a027 handle temp fault reason";
CM_ SG_ 1116 CC_a032_meteringSpiCommsFailure "Charge cable controller: a032 metering spi comms failure";
CM_ SG_ 1116 CC_a032_meteringConfigMismatch "Charge cable controller: a032 metering config mismatch";
CM_ SG_ 1116 CC_a033_nominalVoltage "Charge cable controller: a033 nominal voltage";
CM_ SG_ 1116 CC_a033_measuredVoltage "Charge cable controller: a033 measured voltage";
CM_ SG_ 1116 CC_a036_line1Voltage "Charge cable controller: a036 line1 voltage";
CM_ SG_ 1116 CC_a036_line2Voltage "Charge cable controller: a036 line2 voltage";
CM_ SG_ 1116 CC_a036_line3Voltage "Charge cable controller: a036 line3 voltage";
CM_ SG_ 1116 CC_a036_line1StuckOpen "Charge cable controller: a036 line1 stuck open";
CM_ SG_ 1116 CC_a036_line2StuckOpen "Charge cable controller: a036 line2 stuck open";
CM_ SG_ 1116 CC_a036_line3StuckOpen "Charge cable controller: a036 line3 stuck open";
CM_ SG_ 1116 CC_a037_expiredWatchdogModuleId "Charge cable controller: a037 expired watchdog module id";
CM_ SG_ 1116 CC_a037_expiredWatchdogTaskId "Charge cable controller: a037 expired watchdog task id";
CM_ SG_ 1116 CC_a037_expiredWatchdogAppCRC "Charge cable controller: a037 expired watchdog app CRC";
CM_ SG_ 1116 CC_a038_moduleMiaModuleId "Charge cable controller: a038 module mia module id";
CM_ SG_ 1116 CC_a038_moduleMiaTaskId "Charge cable controller: a038 module mia task id";
CM_ SG_ 1116 CC_a038_moduleMiaAppCRC "Charge cable controller: a038 module mia app CRC";
CM_ SG_ 1116 CC_a039_intModuleTemperature "Charge cable controller: a039 int module temperature";
CM_ SG_ 1116 CC_a040_handleTemperature "Charge cable controller: a040 handle temperature";
CM_ SG_ 1116 CC_a041_inputThermopile "Charge cable controller: a041 input thermopile";
CM_ SG_ 1116 CC_a041_inputThermopileDvdt "Charge cable controller: a041 input thermopile dvdt";
CM_ SG_ 1116 CC_a042_pcbaTemperature "Charge cable controller: a042 pcba temperature";
CM_ SG_ 1116 CC_a044_relayCoilVoltage "Charge cable controller: a044 relay coil voltage";
CM_ SG_ 1116 CC_a044_pcbaTemperature "Charge cable controller: a044 pcba temperature";
CM_ BO_ 1132 "Charge cable controller message: alert matrix1";
CM_ SG_ 1132 CC_a001_gndMonIntrptLineSide "Charge cable controller: a001 gnd mon intrpt line side";
CM_ SG_ 1132 CC_a002_gndMonIntrptLoadSide "Charge cable controller: a002 gnd mon intrpt load side";
CM_ SG_ 1132 CC_a003_CCIDTripped "Charge cable controller: a003 CCID tripped";
CM_ SG_ 1132 CC_a004_CCIDSelfTestFault "Charge cable controller: a004 CCID self test fault";
CM_ SG_ 1132 CC_a005_groundedNeutral "Charge cable controller: a005 grounded neutral";
CM_ SG_ 1132 CC_a006_inputOverCurrent "Charge cable controller: a006 input over current";
CM_ SG_ 1132 CC_a007_inputOverVoltage "Charge cable controller: a007 input over voltage";
CM_ SG_ 1132 CC_a008_inputUnderVoltage "Charge cable controller: a008 input under voltage";
CM_ SG_ 1132 CC_a009_inputMiswired "Charge cable controller: a009 input miswired";
CM_ SG_ 1132 CC_a010_contactorWelded "Charge cable controller: a010 contactor welded";
CM_ SG_ 1132 CC_a011_ambientOT "Charge cable controller: a011 ambient OT";
CM_ SG_ 1132 CC_a012_wallPlugOT "Charge cable controller: a012 wall plug OT";
CM_ SG_ 1132 CC_a013_vehConnOT "Charge cable controller: a013 veh conn OT";
CM_ SG_ 1132 CC_a014_mcuSelfTestFault "Charge cable controller: a014 mcu self test fault";
CM_ SG_ 1132 CC_a015_PilotAFault "Charge cable controller: a015 pilot a fault";
CM_ SG_ 1132 CC_a016_PilotBFault "Charge cable controller: a016 pilot b fault";
CM_ SG_ 1132 CC_a017_PilotCFault "Charge cable controller: a017 pilot c fault";
CM_ SG_ 1132 CC_a018_PilotDFault "Charge cable controller: a018 pilot d fault";
CM_ SG_ 1132 CC_a019_proxDisconnected "Charge cable controller: a019 prox disconnected";
CM_ SG_ 1132 CC_a020_3vRailIncorrect "Charge cable controller: a020 3v rail incorrect";
CM_ SG_ 1132 CC_a021_CB_noMaster "Charge cable controller: a021 CB no master";
CM_ SG_ 1132 CC_a022_CB_tooManyMasters "Charge cable controller: a022 CB too many masters";
CM_ SG_ 1132 CC_a023_CB_tooManySlaves "Charge cable controller: a023 CB too many slaves";
CM_ SG_ 1132 CC_a024_CB_masterISetTooLow "Charge cable controller: a024 CB master i set too low";
CM_ SG_ 1132 CC_a025_evseTemp "Charge cable controller: a025 evse temp";
CM_ SG_ 1132 CC_a026_wallPlugTemp "Charge cable controller: a026 wall plug temp";
CM_ SG_ 1132 CC_a027_vehicleHandleTemp "Charge cable controller: a027 vehicle handle temp";
CM_ SG_ 1132 CC_a028_CB_rotarySelect "Charge cable controller: a028 CB rotary select";
CM_ SG_ 1132 CC_a029_PilotFFault "Charge cable controller: a029 pilot f fault";
CM_ SG_ 1132 CC_a030_masterSlaveMismatch "Charge cable controller: a030 master slave mismatch";
CM_ SG_ 1132 CC_a031_pllLockLost "Charge cable controller: a031 pll lock lost";
CM_ SG_ 1132 CC_a032_meteringFailure "Charge cable controller: a032 metering failure";
CM_ SG_ 1132 CC_a033_vRefOutOfRange "Charge cable controller: a033 v ref out of range";
CM_ SG_ 1132 CC_a034_bootAlert "Charge cable controller: a034 boot alert";
CM_ SG_ 1132 CC_a035_CCIDCalibration "Charge cable controller: a035 CCID calibration";
CM_ SG_ 1132 CC_a036_contactorStuckOpen "Charge cable controller: a036 contactor stuck open";
CM_ SG_ 1132 CC_a037_internalModuleWatchdogEx "Charge cable controller: a037 internal module watchdog expired";
CM_ SG_ 1132 CC_a038_internalModuleMia "Charge cable controller: a038 internal module mia";
CM_ SG_ 1132 CC_a039_internalModuleOverTemp "Charge cable controller: a039 internal module over temp";
CM_ SG_ 1132 CC_a040_handleTempFoldback "Charge cable controller: a040 handle temp foldback";
CM_ SG_ 1132 CC_a041_inputWiringFoldback "Charge cable controller: a041 input wiring foldback";
CM_ SG_ 1132 CC_a042_pcbaTempFoldback "Charge cable controller: a042 pcba temp foldback";
CM_ SG_ 1132 CC_a043_configurationRequired "Charge cable controller: a043 configuration required";
CM_ SG_ 1132 CC_a044_relayCoilVoltageRational "Charge cable controller: a044 relay coil voltage rationality";
CM_ SG_ 1132 CC_a045_ACPowerLoss "Charge cable controller: a045 AC power loss";
CM_ SG_ 1132 CC_a046_GFCIConfigInvalid "Charge cable controller: a046 GFCI config invalid";
CM_ SG_ 1132 CC_a047_MDMotorContFault "Charge cable controller: a047 MD motor cont fault";
CM_ SG_ 1132 CC_a048_ACMDAdapterFault "Charge cable controller: a048 ACMD adapter fault";
CM_ SG_ 1132 CC_a049_rs485Fault "Charge cable controller: a049 rs485 fault";
CM_ SG_ 1132 CC_a050_eFuseFault "Charge cable controller: a050 e fuse fault";
CM_ SG_ 1132 CC_a051_chcCriticalFault "Charge cable controller: a051 chc critical fault";
CM_ SG_ 1132 CC_a052_vRefOutOfRangePWM "Charge cable controller: a052 v ref out of range PWM";
CM_ SG_ 1132 CC_a057_chcVitalsRequestFailure "Charge cable controller: a057 chc vitals request failure";
CM_ SG_ 1132 CC_a060_persistenceFault "Charge cable controller: a060 persistence fault";
CM_ SG_ 1132 CC_a061_unfinishedCommissioning "Charge cable controller: a061 unfinished commissioning";
CM_ BO_ 796 "Charge cable controller message: chg status";
CM_ SG_ 796 CC_currentLimit "Maximum allowable AC current the wall connector is willing to provide";
CM_ SG_ 796 CC_pilotState "State of pilot signal reported by the wall connector";
CM_ SG_ 796 CC_numPhases "Number of AC phases expected by wall connector";
CM_ SG_ 796 CC_line1Voltage "RMS voltage on L1 terminal of wall connector";
CM_ SG_ 796 CC_gridGrounding "Grouding scheme expected by the wall connector";
CM_ SG_ 796 CC_deltaTransformer "Grid configuration expected by the wall connector";
CM_ SG_ 796 CC_numVehCharging "Number of vehicles charging in wall connector load sharing group";
CM_ SG_ 796 CC_line2Voltage "RMS voltage on L2 terminal of wall connector";
CM_ SG_ 796 CC_line3Voltage "RMS voltage on L3 terminal of wall connector";
CM_ SG_ 796 CC_groundResistance "Charge cable controller: ground resistance";
CM_ BO_ 797 "Charge cable controller message: chg status2";
CM_ SG_ 797 CC_chgStatus2Index "Charge cable controller: chg status2 index";
CM_ SG_ 797 CC_buttonState "Charge cable controller: button state";
CM_ BO_ 812 "Charge cable controller message: log data";
CM_ SG_ 812 CC_logIndex "Charge cable controller: log index";
CM_ SG_ 812 CC_activeConnectorID "Site identifier of active charge connector";
CM_ SG_ 812 CC_temperature1 "Charge cable vehicle connector temperature";
CM_ SG_ 812 CC_temperature2 "Charge cable vehicle connector temperature";
CM_ SG_ 812 CC_temperature3 "Charge cable vehicle connector temperature";
CM_ SG_ 812 CC_contactor1Closed "State of contactor 1 in wall connector";
CM_ SG_ 812 CC_contactor2Closed "State of contactor 1 in wall connector";
CM_ SG_ 812 CC_temperature4 "Charge cable vehicle connector temperature";
CM_ SG_ 812 CC_conn1Current "AC current on connector 1 in wall charger load sharing group";
CM_ SG_ 812 CC_conn2Current "AC current on connector 2 in wall charger load sharing group";
CM_ SG_ 812 CC_conn3Current "AC current on connector 3 in wall charger load sharing group";
CM_ SG_ 812 CC_conn4Current "AC current on connector 4 in wall charger load sharing group";
CM_ SG_ 812 CC_lifetimei2t "Charge cable controller: lifetimei2t";
CM_ SG_ 812 CC_lifetimeCtrCycles "Charge cable controller: lifetime ctr cycles";
CM_ SG_ 812 CC_lifetimeCtrCyclesLoaded "Charge cable controller: lifetime ctr cycles loaded";
CM_ SG_ 812 CC_lifetimeAlertCount "Charge cable controller: lifetime alert count";
CM_ SG_ 812 CC_lifetimeThermalFoldbacks "Charge cable controller: lifetime thermal foldbacks";
CM_ SG_ 812 CC_lifetimeAvgStartupTemp "Charge cable controller: lifetime avg startup temp";
CM_ BO_ 870 "CMPD ECU message: info";
CM_ SG_ 870 CMPD_infoIndex "CMPD ECU: info index";
CM_ SG_ 870 CMPD_infoBuildType "CMPD ECU: info build type";
CM_ SG_ 870 CMPD_infoBuildConfigId "CMPD ECU: info build config id";
CM_ SG_ 870 CMPD_infoHardwareId "CMPD ECU: info hardware id";
CM_ SG_ 870 CMPD_infoComponentId "CMPD ECU: info component id";
CM_ SG_ 870 CMPD_infoPcbaId "CMPD ECU: info pcba id";
CM_ SG_ 870 CMPD_infoAssemblyId "CMPD ECU: info assembly id";
CM_ SG_ 870 CMPD_infoUsageId "CMPD ECU: info usage id";
CM_ SG_ 870 CMPD_infoSubUsageId "CMPD ECU: info sub usage id";
CM_ BO_ 680 "CMPD ECU message: state";
CM_ SG_ 680 CMPD_speedRPM "Reports compressor speed.";
CM_ SG_ 680 CMPD_speedDuty "Reports compressor speed duty cycle percentage.";
CM_ SG_ 680 CMPD_inputHVPower "Measures compressor input high voltage (HV) power consumption.";
CM_ SG_ 680 CMPD_inputHVCurrent "Measures compressor input high voltage (HV) current draw.";
CM_ SG_ 680 CMPD_inputHVVoltage "Measures compressor input high voltage (HV) level.";
CM_ SG_ 680 CMPD_2ShuntModeActive "Indicates the compressor motor control is running using only two current shunt resistors instead of three.";
CM_ SG_ 680 CMPD_powerLimitActive "Indicates the compressor power limit is active.";
CM_ SG_ 680 CMPD_state "Reports compressor operational state.";
CM_ SG_ 680 CMPD_wasteHeatState "Reports compressor waste heat recovery state.";
CM_ SG_ 680 CMPD_powerLimitTooLowToStart "Indicates the compressor power limit is too low to start the compressor.";
CM_ SG_ 680 CMPD_ready "Indicates the compressor is ready to start.";
CM_ BO_ 551 "A/C compressor message: HV status";
CM_ SG_ 551 CMP_inputHVVoltage "Compressor high voltage input voltage";
CM_ SG_ 551 CMP_inputLVVoltage "A/C compressor: input LV voltage";
CM_ SG_ 551 CMP_inputHVCurrent "A/C compressor: input HV current";
CM_ SG_ 551 CMP_inputHVPower "Compressor high voltage input power";
CM_ BO_ 867 "A/C compressor message: info";
CM_ SG_ 867 CMP_infoIndex "A/C compressor: info index";
CM_ SG_ 867 CMP_infoBuildType "A/C compressor: info build type";
CM_ SG_ 867 CMP_infoBuildConfigId "A/C compressor: info build config id";
CM_ SG_ 867 CMP_infoHardwareId "A/C compressor: info hardware id";
CM_ SG_ 867 CMP_infoComponentId "A/C compressor: info component id";
CM_ SG_ 867 CMP_infoPcbaId "A/C compressor: info pcba id";
CM_ SG_ 867 CMP_infoAssemblyId "A/C compressor: info assembly id";
CM_ SG_ 867 CMP_infoUsageId "A/C compressor: info usage id";
CM_ SG_ 867 CMP_infoSubUsageId "A/C compressor: info sub usage id";
CM_ SG_ 867 CMP_infoPlatformType "A/C compressor: info platform type";
CM_ SG_ 867 CMP_infoAppCrc "A/C compressor: info app crc";
CM_ SG_ 867 CMP_infoBootUdsProtoVersion "A/C compressor: info boot uds proto version";
CM_ SG_ 867 CMP_infoBootCrc "A/C compressor: info boot crc";
CM_ BO_ 1767 "Charge port controller message: iso tp pipe to pncd";
CM_ SG_ 1767 CP_isoTpToPncdData "Charge port controller: iso tp to pncd data";
BA_DEF_ BO_ "GenMsgCycleTime" INT 0 3600000;
BA_DEF_ BO_ "GenMsgSendType" ENUM "Cyclic","NotUsed","NotUsed","NotUsed","NotUsed","NotUsed","NotUsed","IfActive","NoMsgSendType","NotUsed";
BA_DEF_ BO_ "VFrameFormat" ENUM "StandardCAN","ExtendedCAN","reserved","J1939PG","reserved","reserved","reserved","reserved","reserved","reserved","reserved","reserved","reserved","reserved","StandardCAN_FD","ExtendedCAN_FD";
BA_DEF_ BO_ "CANFD_BRS" ENUM "0","1";
BA_DEF_ SG_ "SystemSignalLongSymbol" STRING;
BA_DEF_ SG_ "Confidence" ENUM "layout-only","plausible","validated";
BA_DEF_DEF_ "GenMsgCycleTime" 0;
BA_DEF_DEF_ "GenMsgSendType" "NoMsgSendType";
BA_DEF_DEF_ "VFrameFormat" "StandardCAN";
BA_DEF_DEF_ "CANFD_BRS" "1";
BA_DEF_DEF_ "SystemSignalLongSymbol" "";
BA_DEF_DEF_ "Confidence" "layout-only";
BA_ "SystemSignalLongSymbol" SG_ 1343 BMS_a002_gatewayPackPerformanceD "BMS_a002_gatewayPackPerformanceDeviation";
BA_ "SystemSignalLongSymbol" SG_ 1343 BMS_a002_expectedPackPerformance "BMS_a002_expectedPackPerformanceDeviation";
BA_ "SystemSignalLongSymbol" SG_ 1343 BMS_a022_chargeAccumulatorViolat "BMS_a022_chargeAccumulatorViolation";
BA_ "SystemSignalLongSymbol" SG_ 1343 BMS_a030_maxNormalizedImpedanceD "BMS_a030_maxNormalizedImpedanceDev";
BA_ "SystemSignalLongSymbol" SG_ 1343 BMS_a069_dischargePowerPackVolta "BMS_a069_dischargePowerPackVoltageFloor";
BA_ "SystemSignalLongSymbol" SG_ 1343 BMS_a069_dischargePowerBrickVolt "BMS_a069_dischargePowerBrickVoltageFloor";
BA_ "SystemSignalLongSymbol" SG_ 1343 BMS_a085_packContactorSetStatePr "BMS_a085_packContactorSetStatePrev";
BA_ "SystemSignalLongSymbol" SG_ 1343 BMS_a085_packContactorSetRe_0001 "BMS_a085_packContactorSetRequestPrev";
BA_ "SystemSignalLongSymbol" SG_ 1343 BMS_a086_fcContactorSetRequestPr "BMS_a086_fcContactorSetRequestPrev";
BA_ "SystemSignalLongSymbol" SG_ 1343 BMS_a122_irrationalThermistorTem "BMS_a122_irrationalThermistorTemp";
BA_ "SystemSignalLongSymbol" SG_ 1343 BMS_a122_averageRawThermistorTem "BMS_a122_averageRawThermistorTemp";
BA_ "SystemSignalLongSymbol" SG_ 800 BMS_a002_Pack_Performance_Config "BMS_a002_Pack_Performance_Config_Mismatch";
BA_ "SystemSignalLongSymbol" SG_ 800 BMS_a003_SW_Pack_Birth_Date_Miss "BMS_a003_SW_Pack_Birth_Date_Missing";
BA_ "SystemSignalLongSymbol" SG_ 800 BMS_a004_Cal_Vs_Serial_Birth_Dat "BMS_a004_Cal_Vs_Serial_Birth_Date_Mismatch";
BA_ "SystemSignalLongSymbol" SG_ 800 BMS_a027_SW_Repeated_Isolation_F "BMS_a027_SW_Repeated_Isolation_Failure_In_Drive";
BA_ "SystemSignalLongSymbol" SG_ 800 BMS_a028_ShuntAsicCurrentOffsetD "BMS_a028_ShuntAsicCurrentOffsetDeviation";
BA_ "SystemSignalLongSymbol" SG_ 800 BMS_a040_SW_Watch_Dog_HW_Trigger "BMS_a040_SW_Watch_Dog_HW_Triggered";
BA_ "SystemSignalLongSymbol" SG_ 800 BMS_a041_SW_Destructive_Reset_So "BMS_a041_SW_Destructive_Reset_Source";
BA_ "SystemSignalLongSymbol" SG_ 800 BMS_a057_SW_Bandolier_Model_Warn "BMS_a057_SW_Bandolier_Model_Warning";
BA_ "SystemSignalLongSymbol" SG_ 800 BMS_a058_SW_Bandolier_Model_Rese "BMS_a058_SW_Bandolier_Model_Reset";
BA_ "SystemSignalLongSymbol" SG_ 800 BMS_a070_BrickV_Imbalance_Limiti "BMS_a070_BrickV_Imbalance_Limiting";
BA_ "SystemSignalLongSymbol" SG_ 800 BMS_a074_Max_Charge_Level_Reduce "BMS_a074_Max_Charge_Level_Reduced";
BA_ "SystemSignalLongSymbol" SG_ 800 BMS_a078_Rapid_Dch_While_Chargin "BMS_a078_Rapid_Dch_While_Charging";
BA_ "SystemSignalLongSymbol" SG_ 800 BMS_a079_Max_Charge_Level_Exceed "BMS_a079_Max_Charge_Level_Exceeded";
BA_ "SystemSignalLongSymbol" SG_ 800 BMS_a085_SW_Pack_Contactor_Misma "BMS_a085_SW_Pack_Contactor_Mismatch";
BA_ "SystemSignalLongSymbol" SG_ 800 BMS_a086_SW_FC_Contactor_Mismatc "BMS_a086_SW_FC_Contactor_Mismatch";
BA_ "SystemSignalLongSymbol" SG_ 800 BMS_a092_SW_ChargePort_Mia_On_Hv "BMS_a092_SW_ChargePort_Mia_On_Hvs";
BA_ "SystemSignalLongSymbol" SG_ 800 BMS_a097_SW_BMB_Over_CAN_Communi "BMS_a097_SW_BMB_Over_CAN_Communication";
BA_ "SystemSignalLongSymbol" SG_ 800 BMS_a098_SW_BMB_Data_Integrity_L "BMS_a098_SW_BMB_Data_Integrity_Loss";
BA_ "SystemSignalLongSymbol" SG_ 800 BMS_a109_HW_BMB_Mute_Status_Mism "BMS_a109_HW_BMB_Mute_Status_Mismatch";
BA_ "SystemSignalLongSymbol" SG_ 800 BMS_a110_LifeModel_AvgOffset_Cha "BMS_a110_LifeModel_AvgOffset_Change";
BA_ "SystemSignalLongSymbol" SG_ 800 BMS_a115_Energy_Rubberbanding_Re "BMS_a115_Energy_Rubberbanding_Reset";
BA_ "SystemSignalLongSymbol" SG_ 800 BMS_a135_HW_BMB_Diagnostics_Fail "BMS_a135_HW_BMB_Diagnostics_Failure";
BA_ "SystemSignalLongSymbol" SG_ 800 BMS_a142_SW_Isolation_Degradatio "BMS_a142_SW_Isolation_Degradation";
BA_ "SystemSignalLongSymbol" SG_ 800 BMS_a148_SW_Unsupported_BMB_ASIC "BMS_a148_SW_Unsupported_BMB_ASIC_Type";
BA_ "SystemSignalLongSymbol" SG_ 800 BMS_a154_SW_Brick_OV_Warning_Sto "BMS_a154_SW_Brick_OV_Warning_Stop_Charge";
BA_ "SystemSignalLongSymbol" SG_ 800 BMS_a172_SW_Isolation_Failure_In "BMS_a172_SW_Isolation_Failure_In_Drive_Warning";
BA_ "SystemSignalLongSymbol" SG_ 800 BMS_a178_SW_Uncontrolled_Regen_P "BMS_a178_SW_Uncontrolled_Regen_PwrB";
BA_ "SystemSignalLongSymbol" SG_ 800 BMS_a181_SW_Shunt_Over_Temperatu "BMS_a181_SW_Shunt_Over_Temperature";
BA_ "SystemSignalLongSymbol" SG_ 800 BMS_a182_LifeModel_NoCurrentLoss "BMS_a182_LifeModel_NoCurrentLoss_Change";
BA_ "SystemSignalLongSymbol" SG_ 800 BMS_a183_LifeModel_StoDcrGrowth_ "BMS_a183_LifeModel_StoDcrGrowth_Change";
BA_ "SystemSignalLongSymbol" SG_ 800 BMS_a184_LifeModel_CyclingLoss_C "BMS_a184_LifeModel_CyclingLoss_Change";
BA_ "SystemSignalLongSymbol" SG_ 800 BMS_a185_LifeModel_CyclingDcrGro "BMS_a185_LifeModel_CyclingDcrGrowth_Change";
BA_ "SystemSignalLongSymbol" SG_ 800 BMS_a186_RippleHeatingChargeFaul "BMS_a186_RippleHeatingChargeFault";
BA_ "SystemSignalLongSymbol" SG_ 800 BMS_a187_RippleHeatingEmergencyS "BMS_a187_RippleHeatingEmergencyShutdown";
BA_ "Confidence" SG_ 818 BMS_thermistorNumTMin 1;
BA_ "Confidence" SG_ 818 BMS_thermistorNumTMax 1;
BA_ "Confidence" SG_ 818 BMS_thermistorTMax 1;
BA_ "Confidence" SG_ 818 BMS_thermistorTMin 1;
BA_ "Confidence" SG_ 818 BMS_thermistorTAvg 1;
BA_ "Confidence" SG_ 818 BMS_brickVoltageMax 1;
BA_ "Confidence" SG_ 818 BMS_brickVoltageMin 1;
BA_ "Confidence" SG_ 818 BMS_brickNumVoltageMax 1;
BA_ "Confidence" SG_ 818 BMS_brickNumVoltageMin 1;
BA_ "Confidence" SG_ 1138 BMS_cellChargeDcCurrentLimit 1;
BA_ "Confidence" SG_ 1138 BMS_voltageRegCurrentTarget 1;
BA_ "Confidence" SG_ 1138 BMS_vehicleChargeDcCurrentLimit 1;
BA_ "Confidence" SG_ 1138 BMS_chargeCurrentLimitMode 1;
BA_ "Confidence" SG_ 1138 BMS_timeToFinishHeatForCharge 1;
BA_ "Confidence" SG_ 1138 BMS_diNodeModelTemp 1;
BA_ "Confidence" SG_ 2029 BMS_activeCoolCellTargetT 1;
BA_ "Confidence" SG_ 2029 BMS_passiveCoolCellTargetT 1;
BA_ "Confidence" SG_ 722 BMS_minBusVoltage 1;
BA_ "Confidence" SG_ 722 BMS_maxBusVoltage 1;
BA_ "Confidence" SG_ 722 BMS_maxChargeCurrent 1;
BA_ "Confidence" SG_ 722 BMS_maxDischargeCurrent 1;
BA_ "Confidence" SG_ 690 BMS_nominalFullPackEnergy 1;
BA_ "Confidence" SG_ 690 BMS_nominalEnergyRemaining 1;
BA_ "Confidence" SG_ 690 BMS_idealEnergyRemaining 1;
BA_ "Confidence" SG_ 690 BMS_fullChargeComplete 1;
BA_ "Confidence" SG_ 690 BMS_energyBuffer 1;
BA_ "Confidence" SG_ 690 BMS_expectedEnergyRemaining 1;
BA_ "Confidence" SG_ 690 BMS_energyToChargeComplete 1;
BA_ "Confidence" SG_ 690 BMS_energyRemainingDisplay 1;
BA_ "Confidence" SG_ 690 BMS_energyRemainingTDisplay 1;
BA_ "Confidence" SG_ 690 BMS_energyDisplayErrorBlendRate 1;
BA_ "Confidence" SG_ 690 BMS_userFacingSoe 1;
BA_ "Confidence" SG_ 306 BMS_packVoltage 1;
BA_ "Confidence" SG_ 306 BMS_packCurrent 1;
BA_ "Confidence" SG_ 306 BMS_currentUnfiltered 1;
BA_ "Confidence" SG_ 306 BMS_chgTimeToFull 1;
BA_ "Confidence" SG_ 768 BMS_buildType 1;
BA_ "Confidence" SG_ 768 BMS_pcbaId 1;
BA_ "Confidence" SG_ 768 BMS_assemblyId 1;
BA_ "Confidence" SG_ 768 BMS_usageId 1;
BA_ "Confidence" SG_ 768 BMS_subUsageId 1;
BA_ "Confidence" SG_ 978 BMS_kwhDischargeTotal 1;
BA_ "Confidence" SG_ 978 BMS_kwhChargeTotal 1;
BA_ "Confidence" SG_ 1010 BMS_acChargerKwhTotal 1;
BA_ "Confidence" SG_ 1010 BMS_dcChargerKwhTotal 1;
BA_ "Confidence" SG_ 1010 BMS_kwhRegenChargeTotal 1;
BA_ "Confidence" SG_ 1010 BMS_kwhDriveDischargeTotal 1;
BA_ "Confidence" SG_ 1010 BMS_kwhDischargeTotalModule1 1;
BA_ "Confidence" SG_ 1010 BMS_kwhChargeTotalModule1 1;
BA_ "Confidence" SG_ 1010 BMS_kwhAcChargeTotalModule1 1;
BA_ "Confidence" SG_ 1010 BMS_kwhDcChargeTotalModule1 1;
BA_ "Confidence" SG_ 1010 BMS_kwhDischargeTotalModule2 1;
BA_ "Confidence" SG_ 1010 BMS_kwhChargeTotalModule2 1;
BA_ "Confidence" SG_ 1010 BMS_kwhAcChargeTotalModule2 1;
BA_ "Confidence" SG_ 1010 BMS_kwhDcChargeTotalModule2 1;
BA_ "Confidence" SG_ 1010 BMS_kwhDischargeTotalModule3 1;
BA_ "Confidence" SG_ 1010 BMS_kwhChargeTotalModule3 1;
BA_ "Confidence" SG_ 1010 BMS_kwhAcChargeTotalModule3 1;
BA_ "Confidence" SG_ 1010 BMS_kwhDcChargeTotalModule3 1;
BA_ "Confidence" SG_ 1010 BMS_kwhDischargeTotalModule4 1;
BA_ "Confidence" SG_ 1010 BMS_kwhChargeTotalModule4 1;
BA_ "Confidence" SG_ 1010 BMS_kwhAcChargeTotalModule4 1;
BA_ "Confidence" SG_ 1010 BMS_kwhDcChargeTotalModule4 1;
BA_ "Confidence" SG_ 884 BMS_extDcPrechargeVoltageLimit 1;
BA_ "Confidence" SG_ 884 BMS_dcChargeCurrentRequest 1;
BA_ "Confidence" SG_ 884 BMS_dcChargeCurrentLimit 1;
BA_ "Confidence" SG_ 884 BMS_dcChargeVoltageLimit 1;
BA_ "Confidence" SG_ 884 BMS_dcChargePowerLimit 1;
BA_ "Confidence" SG_ 884 BMS_maxExtIsoFcLinkV 1;
BA_ "Confidence" SG_ 884 BMS_socByDvMaxSocLimit 1;
BA_ "Confidence" SG_ 884 BMS_socByDvVoltageChangeOverAh 1;
BA_ "Confidence" SG_ 884 BMS_socByDvMaxSocByAhCorrected 1;
BA_ "Confidence" SG_ 884 BMS_socByDvMaxBrickVoltage 1;
BA_ "Confidence" SG_ 946 BMS_cacAvg 1;
BA_ "Confidence" SG_ 946 BMS_cacMin 1;
BA_ "Confidence" SG_ 946 BMS_cacMax 1;
BA_ "Confidence" SG_ 946 BMS_hvChain_useLeakyBucket 1;
BA_ "Confidence" SG_ 946 BMS_hvChain_iLimit 1;
BA_ "Confidence" SG_ 946 BMS_hvChain_limitingStateTempera 1;
BA_ "SystemSignalLongSymbol" SG_ 946 BMS_hvChain_limitingStateTempera "BMS_hvChain_limitingStateTemperature";
BA_ "Confidence" SG_ 946 BMS_acRippleStartTemperatureMax 1;
BA_ "Confidence" SG_ 946 BMS_acRippleStartTemperatureMin 1;
BA_ "Confidence" SG_ 946 BMS_fcLinkTestDecayTime 1;
BA_ "Confidence" SG_ 946 BMS_fcLinkTestTimeSinceLastRun 1;
BA_ "Confidence" SG_ 946 BMS_pcsPrechargeTargetVoltage 1;
BA_ "Confidence" SG_ 946 BMS_recentOvUvAlert 1;
BA_ "Confidence" SG_ 946 BMS_recentIsoAlert 1;
BA_ "Confidence" SG_ 946 BMS_recentBmbMiaAlert 1;
BA_ "Confidence" SG_ 946 BMS_cacBlendPercentPerCycle 1;
BA_ "Confidence" SG_ 946 BMS_packRestTime 1;
BA_ "Confidence" SG_ 946 BMS_idealEnergyFloor 1;
BA_ "Confidence" SG_ 946 BMS_dynamicEnergyBuffer 1;
BA_ "Confidence" SG_ 946 BMS_thmGradientSlope 1;
BA_ "Confidence" SG_ 946 BMS_thmGradient 1;
BA_ "Confidence" SG_ 946 BMS_dSocNormalizedMin 1;
BA_ "Confidence" SG_ 946 BMS_dSocNormalizedFiltMin 1;
BA_ "Confidence" SG_ 946 BMS_dSocMinAlpha 1;
BA_ "Confidence" SG_ 946 BMS_dSocCacMargin 1;
BA_ "Confidence" SG_ 946 BMS_lifeModelAvgTempSeverity 1;
BA_ "Confidence" SG_ 946 BMS_lifeModelDepthOfDischargeSev 1;
BA_ "SystemSignalLongSymbol" SG_ 946 BMS_lifeModelDepthOfDischargeSev "BMS_lifeModelDepthOfDischargeSeverity";
BA_ "Confidence" SG_ 946 BMS_lifeModelHistogramCapacityLo 1;
BA_ "SystemSignalLongSymbol" SG_ 946 BMS_lifeModelHistogramCapacityLo "BMS_lifeModelHistogramCapacityLoss";
BA_ "Confidence" SG_ 946 BMS_lifeModelHistogramBrickCapac 1;
BA_ "SystemSignalLongSymbol" SG_ 946 BMS_lifeModelHistogramBrickCapac "BMS_lifeModelHistogramBrickCapacity";
BA_ "Confidence" SG_ 946 BMS_lifeModelDcrGrowthPercent 1;
BA_ "Confidence" SG_ 946 BMS_nominalFullPackEnergyRaw 1;
BA_ "Confidence" SG_ 946 BMS_userChargeCalibratingReason 1;
BA_ "Confidence" SG_ 946 BMS_nominalEnergyRemainingBuffer 1;
BA_ "SystemSignalLongSymbol" SG_ 946 BMS_nominalEnergyRemainingBuffer "BMS_nominalEnergyRemainingBuffered";
BA_ "Confidence" SG_ 946 BMS_idealEnergyRemainingBuffered 1;
BA_ "Confidence" SG_ 946 BMS_largestCacSpreadErrorLower 1;
BA_ "Confidence" SG_ 946 BMS_lifeModelAverageCac 1;
BA_ "Confidence" SG_ 946 BMS_lifeModelCacBrick1 1;
BA_ "Confidence" SG_ 946 BMS_lifeModelAverageOffset 1;
BA_ "Confidence" SG_ 946 BMS_percentCacUpdatesInTimeWindo 1;
BA_ "SystemSignalLongSymbol" SG_ 946 BMS_percentCacUpdatesInTimeWindo "BMS_percentCacUpdatesInTimeWindow";
BA_ "Confidence" SG_ 946 BMS_lifeModelMaxCac 1;
BA_ "Confidence" SG_ 946 BMS_lifeModelMinCac 1;
BA_ "Confidence" SG_ 946 BMS_restingPointCacAvg 1;
BA_ "Confidence" SG_ 946 BMS_cacEstimationSource 1;
BA_ "Confidence" SG_ 946 BMS_synchronizedCacMaxRaw 1;
BA_ "Confidence" SG_ 946 BMS_synchronizedCacMinRaw 1;
BA_ "Confidence" SG_ 946 BMS_largestSyncCacErrorStartSoc 1;
BA_ "Confidence" SG_ 946 BMS_largestSyncCacErrorEndSoc 1;
BA_ "Confidence" SG_ 946 BMS_rubberBandingEnabled 1;
BA_ "SystemSignalLongSymbol" SG_ 946 BMS_rubberBandingConfigNvramVali "BMS_rubberBandingConfigNvramValid";
BA_ "Confidence" SG_ 946 BMS_runtimeSocMinTempForModel 1;
BA_ "SystemSignalLongSymbol" SG_ 946 BMS_thermalEvent1pDetectConfigDi "BMS_thermalEvent1pDetectConfigDisabled";
BA_ "Confidence" SG_ 946 BMS_sohEnergy 1;
BA_ "Confidence" SG_ 946 BMS_fullCapacitySohEnergy 1;
BA_ "Confidence" SG_ 946 BMS_calibratedCapacitySohEnergy 1;
BA_ "Confidence" SG_ 946 BMS_estimatedCapacitySohEnergy 1;
BA_ "Confidence" SG_ 946 BMS_prevUserFacingSohEnergy 1;
BA_ "Confidence" SG_ 946 BMS_stateOfHealthMinCac 1;
BA_ "Confidence" SG_ 946 BMS_lifeModelStorageLossPackAge 1;
BA_ "Confidence" SG_ 946 BMS_lifeModelThroughputCycleCoun 1;
BA_ "SystemSignalLongSymbol" SG_ 946 BMS_lifeModelThroughputCycleCoun "BMS_lifeModelThroughputCycleCount";
BA_ "Confidence" SG_ 946 BMS_lifeModelThroughputDcrCycleC 1;
BA_ "SystemSignalLongSymbol" SG_ 946 BMS_lifeModelThroughputDcrCycleC "BMS_lifeModelThroughputDcrCycleCount";
BA_ "Confidence" SG_ 946 BMS_chargeTargetLookupSoc 1;
BA_ "Confidence" SG_ 946 BMS_stateOfHealth 1;
BA_ "Confidence" SG_ 914 BMS_reservedConfig_0 1;
BA_ "Confidence" SG_ 914 BMS_moduleType 1;
BA_ "Confidence" SG_ 914 BMS_thermalPackType 1;
BA_ "Confidence" SG_ 914 BMS_packMass 1;
BA_ "Confidence" SG_ 914 BMS_platformMaxBusVoltage 1;
BA_ "Confidence" SG_ 914 BMS_standbySupplyContinuousPower 1;
BA_ "SystemSignalLongSymbol" SG_ 914 BMS_standbySupplyContinuousPower "BMS_standbySupplyContinuousPowerLimit";
BA_ "Confidence" SG_ 594 BMS_maxRegenPower 1;
BA_ "Confidence" SG_ 594 BMS_maxDischargePower 1;
BA_ "Confidence" SG_ 594 BMS_maxStationaryHeatPower 1;
BA_ "Confidence" SG_ 594 BMS_powerLimitsState 1;
BA_ "Confidence" SG_ 594 BMS_notEnoughPowerForHeatPump 1;
BA_ "Confidence" SG_ 594 BMS_instantChargePowerCapability 1;
BA_ "Confidence" SG_ 674 BMS_acRippleCurrentAmplitudeLimi 1;
BA_ "SystemSignalLongSymbol" SG_ 674 BMS_acRippleCurrentAmplitudeLimi "BMS_acRippleCurrentAmplitudeLimit";
BA_ "Confidence" SG_ 674 BMS_acRippleMaxVoltageLimit 1;
BA_ "Confidence" SG_ 674 BMS_acRippleMinVoltageLimit 1;
BA_ "Confidence" SG_ 674 BMS_acRippleFrequencyRequest 1;
BA_ "Confidence" SG_ 674 BMS_acRippleCurrentAmplitudeRequ 1;
BA_ "SystemSignalLongSymbol" SG_ 674 BMS_acRippleCurrentAmplitudeRequ "BMS_acRippleCurrentAmplitudeRequest";
BA_ "Confidence" SG_ 674 BMS_acRippleRequest 1;
BA_ "Confidence" SG_ 658 BMS_socMin 1;
BA_ "Confidence" SG_ 658 BMS_socUI 1;
BA_ "Confidence" SG_ 658 BMS_socMax 1;
BA_ "Confidence" SG_ 658 BMS_socAvg 1;
BA_ "Confidence" SG_ 658 BMS_beginningOfLifePackEnergy 1;
BA_ "Confidence" SG_ 658 BMS_battTempPct 1;
BA_ "Confidence" SG_ 658 BMS_userChargeCurrentLimitMode 1;
BA_ "Confidence" SG_ 1170 BMS_sohEnergyPercent 1;
BA_ "Confidence" SG_ 1170 BMS_userFacingSohTestState 1;
BA_ "Confidence" SG_ 1170 BMS_userFacingSohTestEndMode 1;
BA_ "Confidence" SG_ 1170 BMS_timeSinceSohUpdate 1;
BA_ "Confidence" SG_ 1170 BMS_sohTestCycleFlag 1;
BA_ "Confidence" SG_ 1170 BMS_calibratedSohAvailable 1;
BA_ "Confidence" SG_ 1170 BMS_requiredEvsePowerForSoh 1;
BA_ "Confidence" SG_ 1170 BMS_distanceSinceSohUpdate 1;
BA_ "Confidence" SG_ 530 BMS_notEnoughPowerForDrive 1;
BA_ "Confidence" SG_ 530 BMS_notEnoughPowerForSupport 1;
BA_ "Confidence" SG_ 530 BMS_activeHeatingWorthwhile 1;
BA_ "Confidence" SG_ 530 BMS_cpMiaOnHvs 1;
BA_ "Confidence" SG_ 530 BMS_pcsPwmEnabled 1;
BA_ "Confidence" SG_ 530 BMS_contactorState 1;
BA_ "Confidence" SG_ 530 BMS_userChargeStatus 1;
BA_ "Confidence" SG_ 530 BMS_chargeRequest 1;
BA_ "Confidence" SG_ 530 BMS_state 1;
BA_ "Confidence" SG_ 530 BMS_diLimpRequest 1;
BA_ "Confidence" SG_ 530 BMS_chgPowerAvailable 1;
BA_ "Confidence" SG_ 530 BMS_chargeRetryCount 1;
BA_ "Confidence" SG_ 530 BMS_conditioningRequest 1;
BA_ "Confidence" SG_ 530 BMS_smStateRequest 1;
BA_ "Confidence" SG_ 530 BMS_hvState 1;
BA_ "Confidence" SG_ 786 BMS_powerDissipation 1;
BA_ "Confidence" SG_ 786 BMS_flowRequest 1;
BA_ "Confidence" SG_ 786 BMS_inletActiveCoolTargetT 1;
BA_ "Confidence" SG_ 786 BMS_inletPassiveTargetT 1;
BA_ "Confidence" SG_ 786 BMS_inletActiveHeatTargetT 1;
BA_ "Confidence" SG_ 786 BMS_minPackTemperature 1;
BA_ "Confidence" SG_ 786 BMS_maxPackTemperature 1;
BA_ "Confidence" SG_ 2028 BMS_coldStagnationLimit 1;
BA_ "Confidence" SG_ 2028 BMS_hotStagnationLimit 1;
BA_ "Confidence" SG_ 2028 BMS_hotCellTempLimit 1;
BA_ "Confidence" SG_ 2028 BMS_activeCoolCellReferenceT 1;
BA_ "Confidence" SG_ 2028 BMS_activeHeatCellTargetT 1;
BA_ "Confidence" SG_ 2028 BMS_cellTempTargetMode 1;
BA_ "Confidence" SG_ 2028 BMS_requestDischarge 1;
BA_ "Confidence" SG_ 754 BMS_hvsBusAsleep 1;
BA_ "Confidence" SG_ 754 BMS_nmKeepAwakeReason 1;
BA_ "Confidence" SG_ 754 BMS_nmWakeUpReason 1;
BA_ "Confidence" SG_ 810 BMS_thermalEventSuspected 1;
BA_ "Confidence" SG_ 810 BMS_isolationResistance 1;
BA_ "SystemSignalLongSymbol" SG_ 1132 CC_a037_internalModuleWatchdogEx "CC_a037_internalModuleWatchdogExpired";
BA_ "SystemSignalLongSymbol" SG_ 1132 CC_a044_relayCoilVoltageRational "CC_a044_relayCoilVoltageRationality";
BA_ "Confidence" SG_ 796 CC_currentLimit 1;
BA_ "Confidence" SG_ 796 CC_pilotState 1;
BA_ "Confidence" SG_ 796 CC_numPhases 1;
BA_ "Confidence" SG_ 796 CC_line1Voltage 1;
BA_ "Confidence" SG_ 796 CC_gridGrounding 1;
BA_ "Confidence" SG_ 796 CC_deltaTransformer 1;
BA_ "Confidence" SG_ 796 CC_numVehCharging 1;
BA_ "Confidence" SG_ 796 CC_line2Voltage 1;
BA_ "Confidence" SG_ 796 CC_line3Voltage 1;
BA_ "Confidence" SG_ 796 CC_groundResistance 1;
BA_ "Confidence" SG_ 797 CC_buttonState 1;
BA_ "Confidence" SG_ 812 CC_activeConnectorID 1;
BA_ "Confidence" SG_ 812 CC_temperature1 1;
BA_ "Confidence" SG_ 812 CC_temperature2 1;
BA_ "Confidence" SG_ 812 CC_temperature3 1;
BA_ "Confidence" SG_ 812 CC_contactor1Closed 1;
BA_ "Confidence" SG_ 812 CC_contactor2Closed 1;
BA_ "Confidence" SG_ 812 CC_temperature4 1;
BA_ "Confidence" SG_ 812 CC_conn1Current 1;
BA_ "Confidence" SG_ 812 CC_conn2Current 1;
BA_ "Confidence" SG_ 812 CC_conn3Current 1;
BA_ "Confidence" SG_ 812 CC_conn4Current 1;
BA_ "Confidence" SG_ 812 CC_lifetimei2t 1;
BA_ "Confidence" SG_ 812 CC_lifetimeAvgStartupTemp 1;
BA_ "Confidence" SG_ 870 CMPD_infoBuildType 1;
BA_ "Confidence" SG_ 680 CMPD_speedRPM 1;
BA_ "Confidence" SG_ 680 CMPD_speedDuty 1;
BA_ "Confidence" SG_ 680 CMPD_inputHVPower 1;
BA_ "Confidence" SG_ 680 CMPD_inputHVCurrent 1;
BA_ "Confidence" SG_ 680 CMPD_inputHVVoltage 1;
BA_ "Confidence" SG_ 680 CMPD_2ShuntModeActive 1;
BA_ "Confidence" SG_ 680 CMPD_powerLimitActive 1;
BA_ "Confidence" SG_ 680 CMPD_state 1;
BA_ "Confidence" SG_ 680 CMPD_wasteHeatState 1;
BA_ "Confidence" SG_ 680 CMPD_powerLimitTooLowToStart 1;
BA_ "Confidence" SG_ 680 CMPD_ready 1;
BA_ "Confidence" SG_ 551 CMP_inputHVVoltage 1;
BA_ "Confidence" SG_ 551 CMP_inputLVVoltage 1;
BA_ "Confidence" SG_ 551 CMP_inputHVCurrent 1;
BA_ "Confidence" SG_ 551 CMP_inputHVPower 1;
BA_ "Confidence" SG_ 867 CMP_infoBuildType 1;
VAL_ 1138 BMS_chargeCurrentLimitMode 20 "CHG_LIMIT_RIPPLE_HEAT_ACTIVE" 19 "CHG_LIMIT_NEAR_HWOT_LIMIT" 18 "CHG_LIMIT_LIMP_MODE" 17 "CHG_LIMIT_MISSING_CELL" 16 "CHG_LIMIT_CAC_IMBALANCE" 15 "CHG_LIMIT_PCS_IMPLICIT" 14 "CHG_LIMIT_EVSE_IMPLICIT" 13 "CHG_LIMIT_RAMP_UP_PHASE" 12 "CHG_LIMIT_HVAC_COOLING" 11 "CHG_LIMIT_HV_CHAIN" 10 "CHG_LIMIT_CONFIG" 9 "CHG_LIMIT_TETHERING" 8 "CHG_LIMIT_LEAKY_BUCKET" 7 "CHG_LIMIT_BRICK_VOLTAGE_REG" 6 "CHG_LIMIT_BRICK_TEMP_TOO_COLD" 5 "CHG_LIMIT_BRICK_TEMP_TOO_HOT" 4 "CHG_LIMIT_BRICK_TEMP_OPTIMAL_CELL_PROFILE" 3 "CHG_LIMIT_CP" 2 "CHG_LIMIT_PCS" 1 "CHG_LIMIT_EVSE" 0 "CHG_LIMIT_NONE" ;
VAL_ 768 BMS_buildType 4 "INFO_MFG_BUILD" 3 "INFO_TRACEABLE_CI_BUILD" 2 "INFO_LOCAL_BUILD" 1 "INFO_PLATFORM_BUILD" 0 "INFO_UNKNOWN_BUILD" ;
VAL_ 946 BMS_userChargeCalibratingReason 2 "USR_CHG_CALIBRATING_RUBBER_BANDING_HOLD" 1 "USR_CHG_CALIBRATING_FULL_CHARGE" 0 "USR_CHG_CALIBRATING_INACTIVE" ;
VAL_ 946 BMS_cacEstimationSource 2 "CAC_SOURCE_LIFE_MODEL" 1 "CAC_SOURCE_RESTING_POINT_CAC" 0 "CAC_SOURCE_UNKNOWN" ;
VAL_ 914 BMS_reservedConfig_0 31 "BMS_CONFIG_31" 30 "BMS_CONFIG_30" 29 "BMS_CONFIG_29" 28 "BMS_CONFIG_28" 27 "BMS_CONFIG_27" 26 "BMS_CONFIG_26" 25 "BMS_CONFIG_25" 24 "BMS_CONFIG_24" 23 "BMS_CONFIG_23" 22 "BMS_CONFIG_22" 21 "BMS_CONFIG_21" 20 "BMS_CONFIG_20" 19 "BMS_CONFIG_19" 18 "BMS_CONFIG_18" 17 "BMS_CONFIG_17" 16 "BMS_CONFIG_16" 15 "BMS_CONFIG_15" 14 "BMS_CONFIG_14" 13 "BMS_CONFIG_13" 12 "BMS_CONFIG_12" 11 "BMS_CONFIG_11" 10 "BMS_CONFIG_10" 9 "BMS_CONFIG_9" 8 "BMS_CONFIG_8" 7 "BMS_CONFIG_7" 6 "BMS_CONFIG_6" 5 "BMS_CONFIG_5" 4 "BMS_CONFIG_4" 3 "BMS_CONFIG_3" 2 "BMS_CONFIG_2" 1 "BMS_CONFIG_1" 0 "BMS_CONFIG_0" ;
VAL_ 914 BMS_moduleType 5 "BMS_MOD_TYPE_5" 4 "BMS_MOD_TYPE_4" 3 "BMS_MOD_TYPE_3" 2 "BMS_MOD_TYPE_2" 1 "BMS_MOD_TYPE_1" 0 "BMS_MOD_TYPE_UNKNOWN" ;
VAL_ 914 BMS_thermalPackType 9 "E3D_40P" 8 "E3D" 7 "BLADERUNNER_E1" 6 "BFF00S" 5 "P2" 4 "BFF00_E1" 3 "CATL_E1" 2 "E3" 1 "E1" 0 "UNKNOWN" ;
VAL_ 914 BMS_standbySupplyContinuousPower 3 "17W" 2 "16W" 1 "4W" 0 "0W" ;
VAL_ 594 BMS_powerLimitsState 1 "POWER_CALCULATED_FOR_DRIVE" 0 "POWER_NOT_CALCULATED_FOR_DRIVE" ;
VAL_ 674 BMS_acRippleRequest 4 "RIPPLE_FAULTED" 3 "RIPPLE_ON" 2 "RIPPLE_STANDBY" 1 "RIPPLE_OFF" 0 "RIPPLE_NOT_SUPPORTED" ;
VAL_ 658 BMS_userChargeCurrentLimitMode 4 "USR_CHG_LIMIT_EVSE_RELOCATION_RECOMMENDED" 3 "USR_CHG_LIMIT_HIGH_SOC" 2 "USR_CHG_LIMIT_BATT_TEMP_LOW" 1 "USR_CHG_LIMIT_EVSE" 0 "USR_CHG_LIMIT_NONE" ;
VAL_ 1170 BMS_userFacingSohTestState 5 "CHARGE_REST" 4 "CHARGE" 3 "DISCHARGE_REST" 2 "DISCHARGE" 1 "HEAT_PACK" 0 "NOT_RUNNING" ;
VAL_ 1170 BMS_userFacingSohTestEndMode 5 "TEST_COMPLETE_WITH_SOC_IMBALANCE" 4 "TEST_COMPLETE" 3 "FAILED" 2 "REQUEST_DROPPED" 1 "RUNNING" 0 "NONE" ;
VAL_ 530 BMS_contactorState 6 "BMS_CTRSET_BLOCKED" 5 "BMS_CTRSET_WELDED" 4 "BMS_CTRSET_CLOSED" 3 "BMS_CTRSET_CLOSING" 2 "BMS_CTRSET_OPENING" 1 "BMS_CTRSET_OPEN" 0 "BMS_CTRSET_SNA" ;
VAL_ 530 BMS_userChargeStatus 6 "BMS_CALIBRATING" 5 "BMS_CHARGE_STOPPED" 4 "BMS_CHARGE_COMPLETE" 3 "BMS_CHARGING" 2 "BMS_ABOUT_TO_CHARGE" 1 "BMS_NO_POWER" 0 "BMS_DISCONNECTED" ;
VAL_ 530 BMS_state 10 "BMS_DIAG" 9 "BMS_SNA" 8 "BMS_TEST" 7 "BMS_WELD" 6 "BMS_FAULT" 5 "BMS_CLEAR_FAULT" 4 "BMS_FEIM" 3 "BMS_CHARGE" 2 "BMS_SUPPORT" 1 "BMS_DRIVE" 0 "BMS_STANDBY" ;
VAL_ 530 BMS_diLimpRequest 1 "LIMP_REQUEST_WELDED" 0 "LIMP_REQUEST_NONE" ;
VAL_ 530 BMS_smStateRequest 10 "BMS_DIAG" 9 "BMS_SNA" 8 "BMS_TEST" 7 "BMS_WELD" 6 "BMS_FAULT" 5 "BMS_CLEAR_FAULT" 4 "BMS_FEIM" 3 "BMS_CHARGE" 2 "BMS_SUPPORT" 1 "BMS_DRIVE" 0 "BMS_STANDBY" ;
VAL_ 530 BMS_hvState 6 "HV_UP" 5 "HV_UP_FOR_DC_CHARGE" 4 "HV_UP_FOR_CHARGE" 3 "HV_UP_FOR_DRIVE" 2 "HV_GOING_DOWN" 1 "HV_COMING_UP" 0 "HV_DOWN" ;
VAL_ 2028 BMS_cellTempTargetMode 11 "V2X_SESSION" 10 "PASSIVE_COOL_ON_NAV" 9 "ACTIVE_COOL_ON_NAV" 8 "SOH_HEAT_PACK" 7 "DRAGSTRIP" 6 "PASSIVE_HEAT_ON_NAV" 5 "ACTIVE_HEAT_ON_NAV" 4 "DISCONNECTED_PRECONDITION" 3 "CONNECTED_PRECONDITION" 2 "HIGH_POWER_CHARGE" 1 "LOW_POWER_CHARGE" 0 "DEFAULT" ;
VAL_ 754 BMS_nmKeepAwakeReason 7 "BMS_KEEPAWAKE_REASON_PRECONDITIONING" 6 "BMS_KEEPAWAKE_REASON_CP_ACTIVE" 5 "BMS_KEEPAWAKE_REASON_BMS_ACTIVE" 4 "BMS_KEEPAWAKE_REASON_HVP_ACTIVE" 3 "BMS_KEEPAWAKE_REASON_FC_CTR_CLEANING" 2 "BMS_KEEPAWAKE_REASON_CRITICAL_ALERT" 1 "BMS_KEEPAWAKE_REASON_CTRS_CLOSED" 0 "BMS_KEEPAWAKE_REASON_NONE_SNA" ;
VAL_ 754 BMS_nmWakeUpReason 4 "BMS_WAKEUP_REASON_CRITICALALERT" 3 "BMS_WAKEUP_REASON_WANTTOCHARGE" 2 "BMS_WAKEUP_REASON_CAN_HVS" 1 "BMS_WAKEUP_REASON_CAN_VEH" 0 "BMS_WAKEUP_REASON_NONE" ;
VAL_ 796 CC_pilotState 3 "CC_PILOT_STATE_SNA" 2 "CC_PILOT_STATE_FAULTED" 1 "CC_PILOT_STATE_IDLE" 0 "CC_PILOT_STATE_READY" ;
VAL_ 796 CC_gridGrounding 2 "CC_GRID_GROUNDING_SNA" 1 "CC_GRID_GROUNDING_IT_SplitPhase" 0 "CC_GRID_GROUNDING_TN_TT" ;
VAL_ 797 CC_buttonState 1 "CC_BUTTON_PRESSED" 0 "CC_BUTTON_RELEASED" ;
VAL_ 812 CC_contactor1Closed 3 "CC_CONTACTOR_SNA" 1 "CC_CONTACTOR_CLOSED" 0 "CC_CONTACTOR_OPEN" ;
VAL_ 812 CC_contactor2Closed 3 "CC_CONTACTOR_SNA" 1 "CC_CONTACTOR_CLOSED" 0 "CC_CONTACTOR_OPEN" ;
VAL_ 870 CMPD_infoBuildType 4 "INFO_MFG_BUILD" 3 "INFO_TRACEABLE_CI_BUILD" 2 "INFO_LOCAL_BUILD" 1 "INFO_PLATFORM_BUILD" 0 "INFO_UNKNOWN_BUILD" ;
VAL_ 680 CMPD_state 15 "CMPD_STATE_SNA" 4 "CMPD_STATE_IDLE" 3 "CMPD_STATE_FAULT" 2 "CMPD_STATE_STANDBY" 1 "CMPD_STATE_RUNNING" 0 "CMPD_STATE_INIT" ;
VAL_ 680 CMPD_wasteHeatState 3 "CMPD_WASTE_HEAT_STATE_UNUSED" 2 "CMPD_WASTE_HEAT_STATE_NOT_AVAILABLE" 1 "CMPD_WASTE_HEAT_STATE_ACTIVE" 0 "CMPD_WASTE_HEAT_STATE_OFF" ;
VAL_ 867 CMP_infoBuildType 4 "INFO_MFG_BUILD" 3 "INFO_TRACEABLE_CI_BUILD" 2 "INFO_LOCAL_BUILD" 1 "INFO_PLATFORM_BUILD" 0 "INFO_UNKNOWN_BUILD" ;
